VERSION "HNNBNNNYNNNNNNNNNNNNNNNNNNNNNNNNNNNNNNNNNN/4/%%%/4/'%**4NNN///"

NS_ :

BS_:

BU_: Airbag_D4 EPB_D4 ESP_D4 Gateway_D4C7 Getriebe_AL551_951_D4_C7 Getriebe_DL501_C7 Getriebe_VL381_C7 LWS_D4 Motor_EDC17_D4 Motor_ME17_BY Motor_MED17_SIMOS8_D4 Motor_Slave_D4 QSP_D4 SAK_C7 SCR_C7 SCU_D4

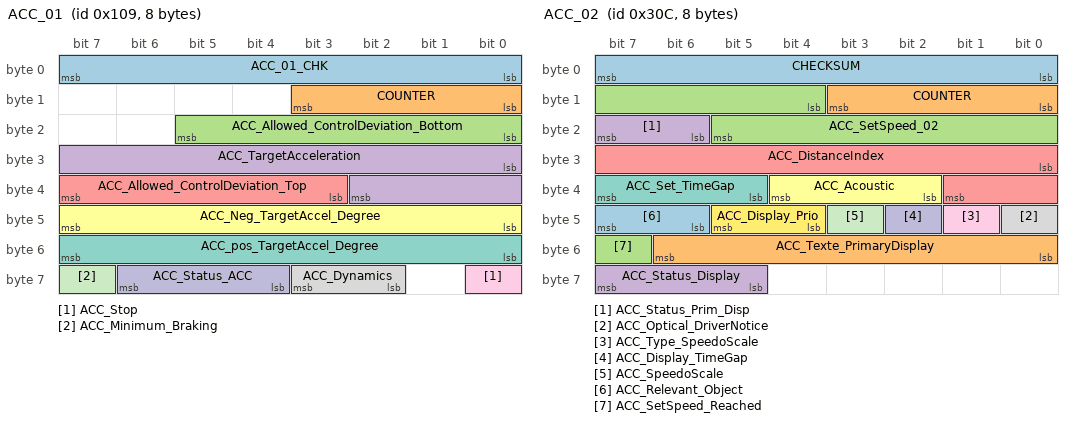
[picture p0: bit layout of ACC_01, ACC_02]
BO_ 265 ACC_01: 8 Gateway_B8
 SG_ ACC_01_CHK : 0|8@1+ (1,0) [0|255] ""  Magnetic_Ride_LB,Motor_MLB_AU48_AU416_Diesel,Motor_MLB_B8_Q5_Otto,Motor_MLB_Q5_Hybrid
 SG_ COUNTER : 8|4@1+ (1,0) [0|15] ""  Magnetic_Ride_LB,Motor_MLB_AU48_AU416_Diesel,Motor_MLB_B8_Q5_Otto,Motor_MLB_Q5_Hybrid
 SG_ ACC_Allowed_ControlDeviation_Bottom : 16|6@1+ (0.024,0) [0|1.512] "Unit_MeterPerSeconSquar"  Motor_MLB_AU48_AU416_Diesel,Motor_MLB_B8_Q5_Otto,Motor_MLB_Q5_Hybrid
 SG_ ACC_TargetAcceleration : 24|11@1+ (0.005,-7.22) [-7.22|3.01] "Unit_MeterPerSeconSquar"  Magnetic_Ride_LB,Motor_MLB_AU48_AU416_Diesel,Motor_MLB_B8_Q5_Otto,Motor_MLB_Q5_Hybrid
 SG_ ACC_Allowed_ControlDeviation_Top : 35|5@1+ (0.0625,0) [0|1.9375] "Unit_MeterPerSeconSquar"  Motor_MLB_AU48_AU416_Diesel,Motor_MLB_B8_Q5_Otto,Motor_MLB_Q5_Hybrid
 SG_ ACC_Neg_TargetAccel_Degree : 40|8@1+ (0.05,0) [0|12.7] "Unit_MeterPerCubicSecon"  Motor_MLB_AU48_AU416_Diesel,Motor_MLB_B8_Q5_Otto,Motor_MLB_Q5_Hybrid
 SG_ ACC_pos_TargetAccel_Degree : 48|8@1+ (0.05,0) [0|12.7] "Unit_MeterPerCubicSecon"  Motor_MLB_AU48_AU416_Diesel,Motor_MLB_B8_Q5_Otto,Motor_MLB_Q5_Hybrid
 SG_ ACC_Dynamics : 58|2@1+ (1,0) [0|3] ""  Motor_MLB_AU48_AU416_Diesel,Motor_MLB_B8_Q5_Otto,Motor_MLB_Q5_Hybrid
 SG_ ACC_Stop : 56|1@1+ (1,0) [0|1] ""  XXX
 SG_ ACC_Status_ACC : 60|3@1+ (1,0) [0|7] ""  XXX
 SG_ ACC_Minimum_Braking : 63|1@1+ (1,0) [0|1] ""  Motor_MLB_AU48_AU416_Diesel,Motor_MLB_B8_Q5_Otto,Motor_MLB_Q5_Hybrid

BO_ 780 ACC_02: 8 Gateway_D4C7
 SG_ CHECKSUM : 0|8@1+ (1,0) [0|255] ""  HUD_C7,Kombi_D4
 SG_ COUNTER : 8|4@1+ (1,0) [0|15] ""  HUD_C7,Kombi_D4
 SG_ ACC_SetSpeed_02 : 12|10@1+ (0.32,0) [0.00|326.72] "Unit_KiloMeterPerHour"  HUD_C7,Kombi_D4
 SG_ ACC_Status_Prim_Disp : 22|2@1+ (1.0,0.0) [0.0|3] ""  HUD_C7,Kombi_D4
 SG_ ACC_DistanceIndex : 24|10@1+ (1,0) [1|1021] ""  HUD_C7,Kombi_D4
 SG_ ACC_Acoustic : 34|3@1+ (1.0,0.0) [0.0|7] ""  Kombi_D4
 SG_ ACC_Set_TimeGap : 37|3@1+ (1.0,0.0) [0.0|7] ""  Kombi_D4
 SG_ ACC_Optical_DriverNotice : 40|1@1+ (1.0,0.0) [0.0|1] ""  Kombi_D4
 SG_ ACC_Type_SpeedoScale : 41|1@1+ (1.0,0.0) [0.0|1] ""  Kombi_D4
 SG_ ACC_Display_TimeGap : 42|1@1+ (1.0,0.0) [0.0|1] ""  Kombi_D4
 SG_ ACC_SpeedoScale : 43|1@1+ (1.0,0.0) [0.0|1] ""  Kombi_D4
 SG_ ACC_Display_Prio : 44|2@1+ (1.0,0.0) [0.0|3] ""  Vector__XXX
 SG_ ACC_Relevant_Object : 46|2@1+ (1.0,0.0) [0.0|3] ""  HUD_C7,Kombi_D4
 SG_ ACC_Texte_PrimaryDisplay : 48|7@1+ (1.0,0.0) [0.0|127] ""  HUD_C7,Kombi_D4
 SG_ ACC_SetSpeed_Reached : 55|1@1+ (1.0,0.0) [0.0|1] ""  Kombi_D4
 SG_ ACC_Status_Display : 61|3@1+ (1.0,0.0) [0.0|7] ""  APS_D4,Kombi_D4

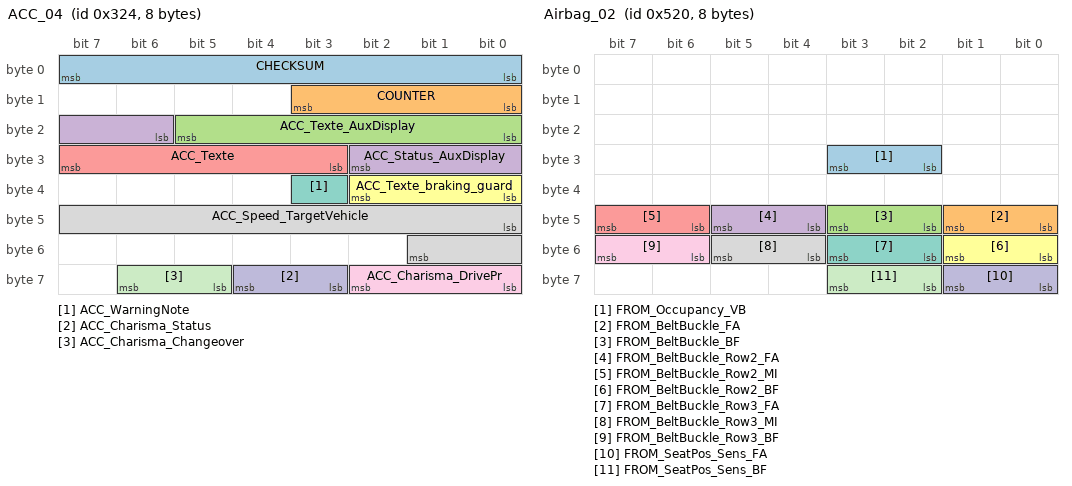
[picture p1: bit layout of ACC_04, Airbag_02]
BO_ 804 ACC_04: 8 Gateway_D4C7
 SG_ CHECKSUM : 0|8@1+ (1,0) [0|255] ""  HUD_C7,Kombi_D4
 SG_ COUNTER : 8|4@1+ (1,0) [0|15] ""  HUD_C7,Kombi_D4
 SG_ ACC_Texte_AuxDisplay : 16|6@1+ (1.0,0.0) [0.0|63] ""  Kombi_D4
 SG_ ACC_Status_AuxDisplay : 22|5@1+ (1.0,0.0) [0.0|31] ""  HUD_C7,Kombi_D4
 SG_ ACC_Texte : 27|5@1+ (1.0,0.0) [0.0|31] ""  Kombi_D4
 SG_ ACC_Texte_braking_guard : 32|3@1+ (1.0,0.0) [0.0|7] ""  HUD_C7,Kombi_D4
 SG_ ACC_WarningNote : 35|1@1+ (1.0,0.0) [0.0|1] ""  Vector__XXX
 SG_ ACC_Speed_TargetVehicle : 40|10@1+ (0.32,0) [0.00|326.72] "Unit_KiloMeterPerHour"  Vector__XXX
 SG_ ACC_Charisma_DrivePr : 56|3@1+ (1.0,0.0) [0.0|7] ""  Vector__XXX
 SG_ ACC_Charisma_Status : 59|2@1+ (1.0,0.0) [0.0|3] ""  Vector__XXX
 SG_ ACC_Charisma_Changeover : 61|2@1+ (1.0,0.0) [0.0|3] ""  Vector__XXX

BO_ 269 ACC_05: 8 Gateway_D4C7
 SG_ ACC_05_CHK : 0|8@1+ (1,0) [0|255] ""  EPB_D4,Getriebe_AL551_951_D4_C7,Getriebe_DL501_C7,Getriebe_VL381_C7,Motor_EDC17_D4,Motor_ME17_BY,Motor_MED17_SIMOS8_D4
 SG_ COUNTER : 8|4@1+ (1,0) [0|15] ""  EPB_D4,Getriebe_AL551_951_D4_C7,Getriebe_DL501_C7,Getriebe_VL381_C7,Motor_EDC17_D4,Motor_ME17_BY,Motor_MED17_SIMOS8_D4
 SG_ ACC_Enable_TorqueReq : 12|1@1+ (1.0,0.0) [0.0|1] ""  Motor_EDC17_D4,Motor_ME17_BY,Motor_MED17_SIMOS8_D4
 SG_ ACC_Enable_DecelReq : 13|1@1+ (1.0,0.0) [0.0|1] ""  Getriebe_AL551_951_D4_C7,Getriebe_DL501_C7,Getriebe_VL381_C7
 SG_ ACC_GearboxPosition_P : 14|1@1+ (1.0,0.0) [0.0|1] ""  Getriebe_AL551_951_D4_C7,Getriebe_DL501_C7,Getriebe_VL381_C7
 SG_ ACC_Limited_PullAwayDyn : 15|1@1+ (1.0,0.0) [0.0|1] ""  Motor_EDC17_D4,Motor_ME17_BY,Motor_MED17_SIMOS8_D4
 SG_ ACC_TorqueRequest : 16|10@1+ (1,0) [0|1021] ""  Motor_EDC17_D4,Motor_ME17_BY,Motor_MED17_SIMOS8_D4
 SG_ ACC_Allowed_ControlDeviation : 26|6@1+ (0.024,0) [0.000|1.512] "Unit_MeterPerSeconSquar"  Getriebe_AL551_951_D4_C7,Getriebe_DL501_C7,Getriebe_VL381_C7
 SG_ ACC_Decel_Req : 32|11@1+ (0.005,-7.22) [-7.220|3.015] "Unit_MeterPerSeconSquar"  Vector__XXX
 SG_ ACC_Loeseanforderung : 43|1@1+ (1.0,0.0) [0.0|1] ""  Vector__XXX
 SG_ ACC_StartStop_Info : 44|2@1+ (1.0,0.0) [0.0|3] ""  Motor_EDC17_D4,Motor_ME17_BY,Motor_MED17_SIMOS8_D4
 SG_ ACC_Vorbefuellung_BrakeSystem : 47|1@1+ (1.0,0.0) [0.0|1] ""  Vector__XXX
 SG_ ACC_ax_Gearbox : 48|9@1+ (0.024,-2.016) [-2.016|10.248] "Unit_MeterPerSeconSquar"  Getriebe_AL551_951_D4_C7,Getriebe_DL501_C7,Getriebe_VL381_C7
 SG_ ACC_Status_ACC : 57|3@1+ (1.0,0.0) [0.0|7] ""  EPB_D4,Motor_EDC17_D4,Motor_ME17_BY,Motor_MED17_SIMOS8_D4
 SG_ ACC_Actuation_EPB : 60|1@1+ (1.0,0.0) [0.0|1] ""  EPB_D4,Motor_EDC17_D4,Motor_ME17_BY,Motor_MED17_SIMOS8_D4
 SG_ ACC_Influence_ESP : 61|1@1+ (1.0,0.0) [0.0|1] ""  Vector__XXX
 SG_ ACC_Stop : 62|1@1+ (1.0,0.0) [0.0|1] ""  Vector__XXX
 SG_ ACC_KD_Error : 63|1@1+ (1.0,0.0) [0.0|1] ""  Vector__XXX

BO_ 279 ACC_10: 8 XXX
 SG_ CHECKSUM : 0|8@1+ (1,0) [0|255] ""  XXX
 SG_ COUNTER : 8|4@1+ (1,0) [0|15] ""  XXX
 SG_ AWV1_Req_Prefill : 16|1@1+ (1,0) [0|1] ""  XXX
 SG_ ANB_CM_Info : 17|1@1+ (1,0) [0|1] ""  XXX
 SG_ AWV2_Enable : 18|1@1+ (1,0) [0|1] ""  XXX
 SG_ AWV1_HBA_Param : 19|2@1+ (1,0) [0|3] ""  XXX
 SG_ AWV2_JerkProfile : 21|3@1+ (1,0) [0|7] ""  XXX
 SG_ AWV2_PrioWarning : 24|1@1+ (1,0) [0|1] ""  XXX
 SG_ ANB_CM_Request : 25|1@1+ (1,0) [0|1] ""  XXX
 SG_ ANB_Info_PartialBraking : 26|1@1+ (1,0) [0|1] ""  XXX
 SG_ ANB_EmergencyFlash : 27|1@1+ (1,0) [0|1] ""  XXX
 SG_ ANB_PartialBraking_Enable : 28|1@1+ (1,0) [0|1] ""  XXX
 SG_ ANB_TargetBrake_Teilbrems_Decel_Req : 29|10@1+ (0.024,-20.016) [-20.016|4.536] "Unit_MeterPerSeconSquar"  XXX
 SG_ ANB_TargetBraking_Enable : 39|1@1+ (1,0) [0|1] ""  XXX
 SG_ AWV_BeforeStage : 40|1@1+ (1,0) [0|1] ""  XXX
 SG_ AWV_Hold : 41|1@1+ (1,0) [0|1] ""  XXX
 SG_ AWV_CityANB_Variant : 42|1@1+ (1,0) [0|1] ""  XXX
 SG_ PCF_Enable : 43|1@1+ (1,0) [0|1] ""  XXX
 SG_ AWV1_ECD_StartUp : 44|1@1+ (1,0) [0|1] ""  XXX
 SG_ AWV_AWA_VZ_Req_Lenkmomoffset : 46|1@1+ (1.0,0.0) [0.0|1] ""  XXX
 SG_ AWV_AWA_Req_Lenkmomoffset : 47|9@1+ (0.01,0) [0.00|5.11] "Unit_NewtoMeter"  XXX
 SG_ PCF_Time_to_collision : 56|8@1+ (0.01,0) [0|2.5] "Unit_Secon"  XXX

BO_ 64 Airbag_01: 8 Airbag_D4
 SG_ Airbag_01_CHK : 0|8@1+ (1,0) [0|255] ""  Gateway_D4C7,Motor_EDC17_D4,Motor_ME17_BY,Motor_MED17_SIMOS8_D4
 SG_ Airbag_01_BZ : 8|4@1+ (1,0) [0|15] ""  Gateway_D4C7,Motor_EDC17_D4,Motor_ME17_BY,Motor_MED17_SIMOS8_D4
 SG_ FROM_RGS_Anst : 12|4@1+ (1.0,0.0) [0.0|15] ""  Gateway_D4C7
 SG_ FROM_Front_Crash : 16|1@1+ (1.0,0.0) [0.0|1] ""  Gateway_D4C7
 SG_ FROM_Rear_Crash : 17|1@1+ (1.0,0.0) [0.0|1] ""  Gateway_D4C7
 SG_ FROM_SF_Crash : 18|1@1+ (1.0,0.0) [0.0|1] ""  Gateway_D4C7
 SG_ FROM_SB_Crash : 19|1@1+ (1.0,0.0) [0.0|1] ""  Gateway_D4C7
 SG_ FROM_Rollover_Crash : 20|1@1+ (1.0,0.0) [0.0|1] ""  Gateway_D4C7
 SG_ FROM_Crash_Int : 21|3@1+ (1.0,0.0) [0.0|7] ""  Gateway_D4C7,Motor_EDC17_D4,Motor_ME17_BY,Motor_MED17_SIMOS8_D4
 SG_ FROM_Lamp : 24|1@1+ (1.0,0.0) [0.0|1] ""  Gateway_D4C7
 SG_ FROM_Deactivated : 25|1@1+ (1.0,0.0) [0.0|1] ""  Gateway_D4C7
 SG_ FROM_VB_Deactivated : 26|1@1+ (1.0,0.0) [0.0|1] ""  Gateway_D4C7
 SG_ FROM_SystemError : 27|1@1+ (1.0,0.0) [0.0|1] ""  Gateway_D4C7
 SG_ FROM_Diagnostics : 28|1@1+ (1.0,0.0) [0.0|1] ""  Gateway_D4C7
 SG_ FROM_ActuatorTest : 29|1@1+ (1.0,0.0) [0.0|1] ""  Gateway_D4C7,Motor_EDC17_D4,Motor_ME17_BY,Motor_MED17_SIMOS8_D4
 SG_ FROM_Erh_Open_VB : 30|2@1+ (1.0,0.0) [0.0|3] ""  Gateway_D4C7
 SG_ FROM_BeltWarn_VF : 32|1@1+ (1.0,0.0) [0.0|1] ""  Gateway_D4C7
 SG_ FROM_BeltWarn_VB : 33|1@1+ (1.0,0.0) [0.0|1] ""  Gateway_D4C7
 SG_ FROM_Display_Pedestrian : 34|2@1+ (1.0,0.0) [0.0|3] ""  Gateway_D4C7
 SG_ FROM_Texte_AKS : 36|2@1+ (1.0,0.0) [0.0|3] ""  Gateway_D4C7
 SG_ FROM_PAO_Lamp_Req : 38|1@1+ (1.0,0.0) [0.0|1] ""  Gateway_D4C7
 SG_ FROM_MKB_Valid : 39|1@1+ (1.0,0.0) [0.0|1] ""  Gateway_D4C7
 SG_ FROM_MKB_Request : 40|1@1+ (1.0,0.0) [0.0|1] ""  Gateway_D4C7
 SG_ FROM_SupplyVoltage : 41|1@1+ (1.0,0.0) [0.0|1] ""  Gateway_D4C7
 SG_ FROM_KD_Error : 63|1@1+ (1.0,0.0) [0.0|1] ""  Gateway_D4C7

BO_ 1312 Airbag_02: 8 Airbag_D4
 SG_ FROM_Occupancy_VB : 26|2@1+ (1.0,0.0) [0.0|3] ""  Gateway_D4C7
 SG_ FROM_BeltBuckle_FA : 40|2@1+ (1.0,0.0) [0.0|3] ""  EPB_D4,Gateway_D4C7,Motor_EDC17_D4,Motor_ME17_BY,Motor_MED17_SIMOS8_D4
 SG_ FROM_BeltBuckle_BF : 42|2@1+ (1.0,0.0) [0.0|3] ""  Gateway_D4C7
 SG_ FROM_BeltBuckle_Row2_FA : 44|2@1+ (1.0,0.0) [0.0|3] ""  Gateway_D4C7
 SG_ FROM_BeltBuckle_Row2_MI : 46|2@1+ (1.0,0.0) [0.0|3] ""  Gateway_D4C7
 SG_ FROM_BeltBuckle_Row2_BF : 48|2@1+ (1.0,0.0) [0.0|3] ""  Gateway_D4C7
 SG_ FROM_BeltBuckle_Row3_FA : 50|2@1+ (1.0,0.0) [0.0|3] ""  Gateway_D4C7
 SG_ FROM_BeltBuckle_Row3_MI : 52|2@1+ (1.0,0.0) [0.0|3] ""  Gateway_D4C7
 SG_ FROM_BeltBuckle_Row3_BF : 54|2@1+ (1.0,0.0) [0.0|3] ""  Gateway_D4C7
 SG_ FROM_SeatPos_Sens_FA : 56|2@1+ (1.0,0.0) [0.0|3] ""  Gateway_D4C7
 SG_ FROM_SeatPos_Sens_BF : 58|2@1+ (1.0,0.0) [0.0|3] ""  Gateway_D4C7

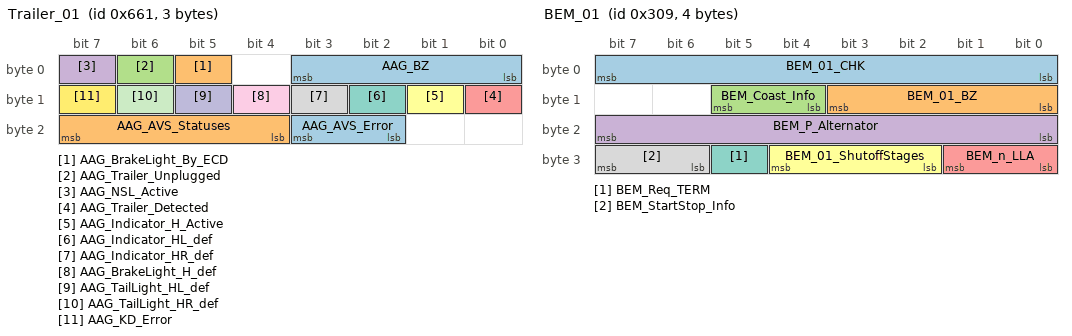
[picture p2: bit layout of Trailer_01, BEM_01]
BO_ 1633 Trailer_01: 3 Gateway_D4C7
 SG_ AAG_BZ : 0|4@1+ (1,0) [0|15] ""  Getriebe_AL551_951_D4_C7,Motor_EDC17_D4,Motor_ME17_BY,Motor_MED17_SIMOS8_D4
 SG_ AAG_BrakeLight_By_ECD : 5|1@1+ (1.0,0.0) [0.0|1] ""  Motor_EDC17_D4,Motor_ME17_BY,Motor_MED17_SIMOS8_D4
 SG_ AAG_Trailer_Unplugged : 6|1@1+ (1.0,0.0) [0.0|1] ""  Vector__XXX
 SG_ AAG_NSL_Active : 7|1@1+ (1.0,0.0) [0.0|1] ""  Vector__XXX
 SG_ AAG_Trailer_Detected : 8|1@1+ (1.0,0.0) [0.0|1] ""  Getriebe_AL551_951_D4_C7,Getriebe_DL501_C7,Getriebe_VL381_C7,Motor_EDC17_D4,Motor_ME17_BY,Motor_MED17_SIMOS8_D4
 SG_ AAG_Indicator_H_Active : 9|1@1+ (1.0,0.0) [0.0|1] ""  Vector__XXX
 SG_ AAG_Indicator_HL_def : 10|1@1+ (1.0,0.0) [0.0|1] ""  Vector__XXX
 SG_ AAG_Indicator_HR_def : 11|1@1+ (1.0,0.0) [0.0|1] ""  Vector__XXX
 SG_ AAG_BrakeLight_H_def : 12|1@1+ (1.0,0.0) [0.0|1] ""  Motor_EDC17_D4,Motor_ME17_BY,Motor_MED17_SIMOS8_D4
 SG_ AAG_TailLight_HL_def : 13|1@1+ (1.0,0.0) [0.0|1] ""  Vector__XXX
 SG_ AAG_TailLight_HR_def : 14|1@1+ (1.0,0.0) [0.0|1] ""  Vector__XXX
 SG_ AAG_KD_Error : 15|1@1+ (1.0,0.0) [0.0|1] ""  Vector__XXX
 SG_ AAG_AVS_Error : 18|2@1+ (1.0,0.0) [0.0|3] ""  Vector__XXX
 SG_ AAG_AVS_Statuses : 20|4@1+ (1.0,0.0) [0.0|15] ""  Vector__XXX

BO_ 777 BEM_01: 4 Gateway_D4C7
 SG_ BEM_01_CHK : 0|8@1+ (1,0) [0|255] ""  Motor_EDC17_D4,Motor_ME17_BY,Motor_MED17_SIMOS8_D4
 SG_ BEM_01_BZ : 8|4@1+ (1,0) [0|15] ""  Motor_EDC17_D4,Motor_ME17_BY,Motor_MED17_SIMOS8_D4
 SG_ BEM_Coast_Info : 12|2@1+ (1.0,0.0) [0.0|3] ""  Vector__XXX
 SG_ BEM_P_Alternator : 16|8@1+ (50,0) [0|12700] "Unit_Watt"  Motor_EDC17_D4,Motor_ME17_BY,Motor_MED17_SIMOS8_D4
 SG_ BEM_n_LLA : 24|2@1+ (1.0,0.0) [0.0|3] ""  Motor_EDC17_D4,Motor_ME17_BY,Motor_MED17_SIMOS8_D4
 SG_ BEM_01_ShutoffStages : 26|3@1+ (1.0,0.0) [0.0|7] ""  Vector__XXX
 SG_ BEM_Req_TERM : 29|1@1+ (1.0,0.0) [0.0|1] ""  Motor_EDC17_D4,Motor_ME17_BY,Motor_MED17_SIMOS8_D4
 SG_ BEM_StartStop_Info : 30|2@1+ (1.0,0.0) [0.0|3] ""  Motor_EDC17_D4,Motor_ME17_BY,Motor_MED17_SIMOS8_D4

BO_ 867 FlashModes_01: 4 Gateway_D4C7
 SG_ BM_ZV_Open : 0|1@1+ (1.0,0.0) [0.0|1] ""  Vector__XXX
 SG_ BM_ZV_Closed : 1|1@1+ (1.0,0.0) [0.0|1] ""  Vector__XXX
 SG_ BM_DWA_On : 2|1@1+ (1.0,0.0) [0.0|1] ""  Vector__XXX
 SG_ BM_DWA_Alarm : 3|1@1+ (1.0,0.0) [0.0|1] ""  Vector__XXX
 SG_ BM_Crash : 4|1@1+ (1.0,0.0) [0.0|1] ""  Vector__XXX
 SG_ BM_Panic : 5|1@1+ (1.0,0.0) [0.0|1] ""  Vector__XXX
 SG_ BM_Not_Braking : 6|1@1+ (1.0,0.0) [0.0|1] ""  Vector__XXX
 SG_ BM_GDO : 7|1@1+ (1.0,0.0) [0.0|1] ""  Vector__XXX
 SG_ BM_Left : 8|1@1+ (1.0,0.0) [0.0|1] ""  Vector__XXX
 SG_ BM_Right : 9|1@1+ (1.0,0.0) [0.0|1] ""  Vector__XXX
 SG_ BM_HazardFlash : 10|1@1+ (1.0,0.0) [0.0|1] ""  Vector__XXX
 SG_ BM_Motorway : 11|1@1+ (1.0,0.0) [0.0|1] ""  Vector__XXX
 SG_ BM_Taxi_Notalarm : 12|1@1+ (1.0,0.0) [0.0|1] ""  Vector__XXX
 SG_ BM_Telematics : 13|1@1+ (1.0,0.0) [0.0|1] ""  Vector__XXX
 SG_ BM_HD_Opening_angelernt : 14|1@1+ (1.0,0.0) [0.0|1] ""  Vector__XXX
 SG_ BM_WBT_Lighting : 15|1@1+ (1.0,0.0) [0.0|1] ""  Vector__XXX
 SG_ Flash_Left_Veh_Clock : 16|1@1+ (1.0,0.0) [0.0|1] ""  Vector__XXX
 SG_ Flash_Right_Veh_Clock : 17|1@1+ (1.0,0.0) [0.0|1] ""  Vector__XXX
 SG_ Flash_Left_Cluster_Clock : 18|1@1+ (1.0,0.0) [0.0|1] ""  Kombi_D4
 SG_ Flash_Right_Cluster_Clock : 19|1@1+ (1.0,0.0) [0.0|1] ""  Kombi_D4
 SG_ BM_NBA_n_Coded_n_Active : 20|1@1+ (1.0,0.0) [0.0|1] ""  Vector__XXX
 SG_ BM_NBA_Status : 21|2@1+ (1.0,0.0) [0.0|3] ""  Vector__XXX
 SG_ Flash_FWB_Active : 23|1@1+ (1.0,0.0) [0.0|1] ""  Vector__XXX

BO_ 482 CCP_GE_CR0_01: 8 Gateway_D4C7
 SG_ CCP_GE_CRO_01_Data : 0|64@1+ (1,0) [0|1] ""  Getriebe_AL551_951_D4_C7,Getriebe_DL501_C7,Getriebe_VL381_C7

BO_ 490 CCP_GE_Ditto_01: 8 Getriebe_AL551_951_D4_C7
 SG_ CCP_GE_Ditto_01_Data : 0|64@1+ (1,0) [0|1] ""  Gateway_D4C7

BO_ 480 CCP_MO_CRO_01: 8 Gateway_D4C7
 SG_ CCP_MO_CRO_01_Data : 0|64@1+ (1,0) [0|1] ""  Motor_EDC17_D4,Motor_ME17_BY,Motor_MED17_SIMOS8_D4

BO_ 2616986624 CCP_MO_CRO_02: 8 Vector__XXX
 SG_ CCP_MO_CRO_02_Data : 0|64@1+ (1,0) [0|1] ""  Motor_EDC17_D4,Motor_ME17_BY,Motor_MED17_SIMOS8_D4

BO_ 488 CCP_MO_Ditto_01: 8 Motor_EDC17_D4
 SG_ CCP_MO_Ditto_01_Data : 0|64@1+ (1,0) [0|1] ""  Gateway_D4C7

BO_ 2616986625 CCP_MO_Ditto_02: 8 Motor_EDC17_D4
 SG_ CCP_MO_Ditto_02_Data : 0|64@1+ (1,0) [0|1] ""  Vector__XXX

BO_ 481 CCP_MOS_CRO_01: 8 Gateway_D4C7
 SG_ CCP_MOS_CRO_01_Data : 0|64@1+ (1,0) [0|1] ""  Motor_Slave_D4

BO_ 2616986629 CCP_MOS_CRO_02: 8 Vector__XXX
 SG_ CCP_MOS_CRO_02_Data : 0|64@1+ (1,0) [0|1] ""  Motor_Slave_D4

BO_ 489 CCP_MOS_Ditto_01: 8 Motor_Slave_D4
 SG_ CCP_MOS_Ditto_01_Data : 0|64@1+ (1,0) [0|1] ""  Gateway_D4C7

BO_ 2616986630 CCP_MOS_Ditto_02: 8 Motor_Slave_D4
 SG_ CCP_MOS_Ditto_02_Data : 0|64@1+ (1,0) [0|1] ""  Vector__XXX

BO_ 2617042432 CCP_SoundActuator_CRO_01: 8 Vector__XXX
 SG_ CCP_SoundActuator_CRO_01_Data : 0|64@1+ (1.0,0.0) [0.0|18446744073709551615] ""  SAK_C7

BO_ 2617042433 CCP_SoundActuator_Ditto_01: 8 SAK_C7
 SG_ CCP_SoundActuator_Ditto_01_Data : 0|64@1+ (1.0,0.0) [0.0|18446744073709551615] ""  Vector__XXX

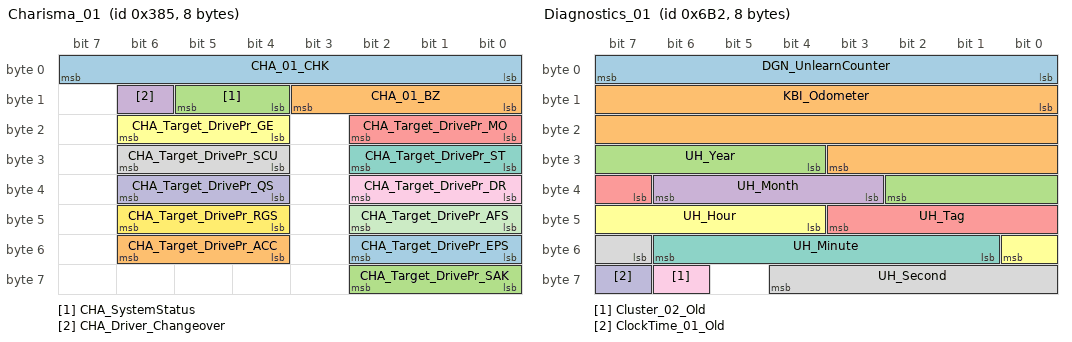
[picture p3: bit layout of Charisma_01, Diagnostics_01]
BO_ 901 Charisma_01: 8 Gateway_D4C7
 SG_ CHA_01_CHK : 0|8@1+ (1,0) [0|255] ""  Getriebe_AL551_951_D4_C7,Getriebe_DL501_C7,Getriebe_VL381_C7,Motor_EDC17_D4,Motor_ME17_BY,Motor_MED17_SIMOS8_D4,SCU_D4
 SG_ CHA_01_BZ : 8|4@1+ (1,0) [0|15] ""  Motor_EDC17_D4,Motor_ME17_BY,Motor_MED17_SIMOS8_D4
 SG_ CHA_SystemStatus : 12|2@1+ (1.0,0.0) [0.0|3] ""  Getriebe_AL551_951_D4_C7,Getriebe_DL501_C7,Getriebe_VL381_C7,Motor_EDC17_D4,Motor_ME17_BY,Motor_MED17_SIMOS8_D4,SCU_D4
 SG_ CHA_Driver_Changeover : 14|1@1+ (1.0,0.0) [0.0|1] ""  Vector__XXX
 SG_ CHA_Target_DrivePr_MO : 16|3@1+ (1.0,0.0) [0.0|7] ""  Motor_EDC17_D4,Motor_ME17_BY,Motor_MED17_SIMOS8_D4
 SG_ CHA_Target_DrivePr_GE : 20|3@1+ (1.0,0.0) [0.0|7] ""  Getriebe_AL551_951_D4_C7,Getriebe_DL501_C7,Getriebe_VL381_C7
 SG_ CHA_Target_DrivePr_ST : 24|3@1+ (1.0,0.0) [0.0|7] ""  Vector__XXX
 SG_ CHA_Target_DrivePr_SCU : 28|3@1+ (1.0,0.0) [0.0|7] ""  SCU_D4
 SG_ CHA_Target_DrivePr_DR : 32|3@1+ (1.0,0.0) [0.0|7] ""  Vector__XXX
 SG_ CHA_Target_DrivePr_QS : 36|3@1+ (1.0,0.0) [0.0|7] ""  Vector__XXX
 SG_ CHA_Target_DrivePr_AFS : 40|3@1+ (1.0,0.0) [0.0|7] ""  Vector__XXX
 SG_ CHA_Target_DrivePr_RGS : 44|3@1+ (1.0,0.0) [0.0|7] ""  Vector__XXX
 SG_ CHA_Target_DrivePr_EPS : 48|3@1+ (1.0,0.0) [0.0|7] ""  Vector__XXX
 SG_ CHA_Target_DrivePr_ACC : 52|3@1+ (1.0,0.0) [0.0|7] ""  Vector__XXX
 SG_ CHA_Target_DrivePr_SAK : 56|3@1+ (1.0,0.0) [0.0|7] ""  Vector__XXX

BO_ 2617027072 DEV_Airbag_01: 4 Airbag_D4
 SG_ DEV_Airbag_01 : 0|32@1+ (1.0,0.0) [0.0|4294967295] ""  Vector__XXX

BO_ 1714 Diagnostics_01: 8 Gateway_D4C7
 SG_ DGN_UnlearnCounter : 0|8@1+ (1,0) [0|254] ""  Airbag_D4,EPB_D4,Getriebe_AL551_951_D4_C7,SAK_C7,SCR_C7,SCU_D4
 SG_ KBI_Odometer : 8|20@1+ (1,0) [0|1048573] "Unit_KiloMeter"  Airbag_D4,EPB_D4,Getriebe_AL551_951_D4_C7,Getriebe_DL501_C7,Getriebe_VL381_C7,Motor_EDC17_D4,Motor_ME17_BY,Motor_MED17_SIMOS8_D4,SAK_C7,SCR_C7,SCU_D4
 SG_ UH_Year : 28|7@1+ (1,2000) [2000|2127] "Unit_Year"  Airbag_D4,EPB_D4,Getriebe_AL551_951_D4_C7,Getriebe_DL501_C7,Getriebe_VL381_C7,Motor_EDC17_D4,Motor_ME17_BY,Motor_MED17_SIMOS8_D4,SAK_C7,SCR_C7,SCU_D4
 SG_ UH_Month : 35|4@1+ (1,0) [1|12] "Unit_Month"  Airbag_D4,EPB_D4,Getriebe_AL551_951_D4_C7,Getriebe_DL501_C7,Getriebe_VL381_C7,Motor_EDC17_D4,Motor_ME17_BY,Motor_MED17_SIMOS8_D4,SAK_C7,SCR_C7,SCU_D4
 SG_ UH_Tag : 39|5@1+ (1,0) [1|31] "Unit_Day"  Airbag_D4,EPB_D4,Getriebe_AL551_951_D4_C7,Getriebe_DL501_C7,Getriebe_VL381_C7,Motor_EDC17_D4,Motor_ME17_BY,Motor_MED17_SIMOS8_D4,SAK_C7,SCR_C7,SCU_D4
 SG_ UH_Hour : 44|5@1+ (1,0) [0|23] "Unit_Hours"  Airbag_D4,EPB_D4,Getriebe_AL551_951_D4_C7,Getriebe_DL501_C7,Getriebe_VL381_C7,Motor_EDC17_D4,Motor_ME17_BY,Motor_MED17_SIMOS8_D4,SAK_C7,SCR_C7,SCU_D4
 SG_ UH_Minute : 49|6@1+ (1,0) [0|59] "Unit_Minut"  Airbag_D4,EPB_D4,Getriebe_AL551_951_D4_C7,Getriebe_DL501_C7,Getriebe_VL381_C7,Motor_EDC17_D4,Motor_ME17_BY,Motor_MED17_SIMOS8_D4,SAK_C7,SCR_C7,SCU_D4
 SG_ UH_Second : 55|6@1+ (1,0) [0|59] "Unit_Secon"  Airbag_D4,EPB_D4,Getriebe_AL551_951_D4_C7,Getriebe_DL501_C7,Getriebe_VL381_C7,Motor_EDC17_D4,Motor_ME17_BY,Motor_MED17_SIMOS8_D4,SAK_C7,SCR_C7,SCU_D4
 SG_ Cluster_02_Old : 62|1@1+ (1.0,0.0) [0.0|1] ""  Airbag_D4,Getriebe_AL551_951_D4_C7,Getriebe_DL501_C7,Getriebe_VL381_C7,SCR_C7,SCU_D4
 SG_ ClockTime_01_Old : 63|1@1+ (1.0,0.0) [0.0|1] ""  Airbag_D4,Getriebe_AL551_951_D4_C7,Getriebe_DL501_C7,Getriebe_VL381_C7,SCR_C7,SCU_D4

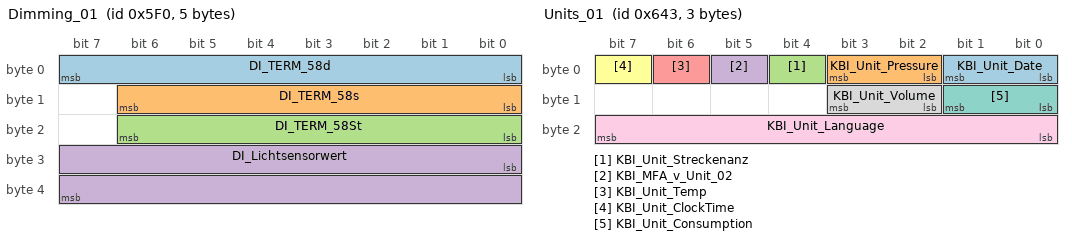
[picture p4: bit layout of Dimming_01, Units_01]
BO_ 1520 Dimming_01: 5 Gateway_D4C7
 SG_ DI_TERM_58d : 0|8@1+ (1,0) [0|253] ""  Airbag_D4,Getriebe_AL551_951_D4_C7
 SG_ DI_TERM_58s : 8|7@1+ (1,0) [0|100] "Unit_PerCent"  Getriebe_AL551_951_D4_C7
 SG_ DI_TERM_58St : 16|7@1+ (1,0) [0|100] "Unit_PerCent"  Getriebe_AL551_951_D4_C7
 SG_ DI_Lichtsensorwert : 24|16@1+ (1,0) [0|65535] ""  Airbag_D4,Getriebe_AL551_951_D4_C7

BO_ 1603 Units_01: 3 Gateway_D4C7
 SG_ KBI_Unit_Date : 0|2@1+ (1.0,0.0) [0.0|3] ""  Vector__XXX
 SG_ KBI_Unit_Pressure : 2|2@1+ (1.0,0.0) [0.0|3] ""  Vector__XXX
 SG_ KBI_Unit_Streckenanz : 4|1@1+ (1.0,0.0) [0.0|1] ""  Motor_EDC17_D4
 SG_ KBI_MFA_v_Unit_02 : 5|1@1+ (1.0,0.0) [0.0|1] ""  Vector__XXX
 SG_ KBI_Unit_Temp : 6|1@1+ (1.0,0.0) [0.0|1] ""  Vector__XXX
 SG_ KBI_Unit_ClockTime : 7|1@1+ (1.0,0.0) [0.0|1] ""  Vector__XXX
 SG_ KBI_Unit_Consumption : 8|2@1+ (1.0,0.0) [0.0|3] ""  Vector__XXX
 SG_ KBI_Unit_Volume : 10|2@1+ (1.0,0.0) [0.0|3] ""  Vector__XXX
 SG_ KBI_Unit_Language : 16|8@1+ (1,0) [0|255] ""  Vector__XXX

BO_ 260 EPB_01: 8 EPB_D4
 SG_ EPB_01_CHK : 0|8@1+ (1,0) [0|255] ""  Gateway_D4C7,Motor_EDC17_D4,Motor_ME17_BY,Motor_MED17_SIMOS8_D4
 SG_ EPB_01_BZ : 8|4@1+ (1,0) [0|15] ""  Gateway_D4C7,Motor_EDC17_D4,Motor_ME17_BY,Motor_MED17_SIMOS8_D4
 SG_ EPB_QBit_LongAccel : 12|1@1+ (1.0,0.0) [0.0|1] ""  Gateway_D4C7
 SG_ EPB_QBit_PedalTravel_Clutch : 13|1@1+ (1.0,0.0) [0.0|1] ""  Gateway_D4C7,Motor_EDC17_D4,Motor_ME17_BY,Motor_MED17_SIMOS8_D4
 SG_ EPB_BCM2_Engine_Wakeup : 14|1@1+ (1.0,0.0) [0.0|1] ""  Gateway_D4C7
 SG_ EPB_Enable_Decel_Req : 15|1@1+ (1.0,0.0) [0.0|1] ""  Gateway_D4C7,Getriebe_AL551_951_D4_C7,Motor_EDC17_D4,Motor_ME17_BY,Motor_MED17_SIMOS8_D4
 SG_ EPB_Decel_Req : 16|8@1+ (0.048,-7.968) [-7.968|4.224] "Unit_MeterPerSeconSquar"  Gateway_D4C7
 SG_ EPB_LongAccel : 24|8@1+ (1,-128) [-128|126] "Unit_PerCentOfForceOfGravi"  Gateway_D4C7
 SG_ EPB_PedalTravel_Clutch : 32|8@1+ (0.4,0) [8.0|92.0] "Unit_PerCent"  Gateway_D4C7,Motor_EDC17_D4,Motor_ME17_BY,Motor_MED17_SIMOS8_D4
 SG_ EPB_PullAwayRequest_Detected : 48|1@1+ (1.0,0.0) [0.0|1] ""  Gateway_D4C7
 SG_ EPB_DAA_BoundaryCond_erf : 49|1@1+ (1.0,0.0) [0.0|1] ""  Gateway_D4C7
 SG_ EPB_ErrorStatus : 50|2@1+ (1.0,0.0) [0.0|3] ""  Gateway_D4C7
 SG_ EPB_Schalterposition : 52|2@1+ (1.0,0.0) [0.0|3] ""  Gateway_D4C7,Getriebe_AL551_951_D4_C7,Motor_EDC17_D4,Motor_ME17_BY,Motor_MED17_SIMOS8_D4
 SG_ EPB_QBit_Schalterpos : 54|1@1+ (1.0,0.0) [0.0|1] ""  Gateway_D4C7,Getriebe_AL551_951_D4_C7,Motor_EDC17_D4,Motor_ME17_BY,Motor_MED17_SIMOS8_D4
 SG_ EPB_Consistency_ACC : 55|1@1+ (1.0,0.0) [0.0|1] ""  Gateway_D4C7
 SG_ EPB_ClampForce : 56|5@1+ (1,0) [0|29] "Unit_KiloNewto"  Gateway_D4C7,Getriebe_AL551_951_D4_C7,Getriebe_DL501_C7,Getriebe_VL381_C7
 SG_ EPB_Status : 61|2@1+ (1.0,0.0) [0.0|3] ""  Gateway_D4C7,Getriebe_AL551_951_D4_C7,Getriebe_DL501_C7,Motor_EDC17_D4,Motor_ME17_BY,Motor_MED17_SIMOS8_D4
 SG_ EPB_KD_Error : 63|1@1+ (1.0,0.0) [0.0|1] ""  Gateway_D4C7

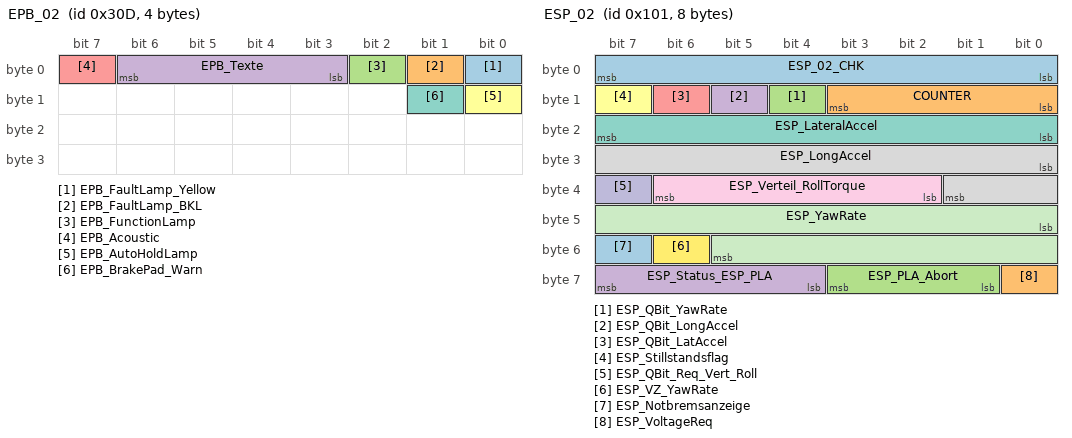
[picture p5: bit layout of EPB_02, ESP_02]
BO_ 781 EPB_02: 4 EPB_D4
 SG_ EPB_FaultLamp_Yellow : 0|1@1+ (1.0,0.0) [0.0|1] ""  Gateway_D4C7
 SG_ EPB_FaultLamp_BKL : 1|1@1+ (1.0,0.0) [0.0|1] ""  Gateway_D4C7
 SG_ EPB_FunctionLamp : 2|1@1+ (1.0,0.0) [0.0|1] ""  Gateway_D4C7
 SG_ EPB_Texte : 3|4@1+ (1.0,0.0) [0.0|15] ""  Gateway_D4C7
 SG_ EPB_Acoustic : 7|1@1+ (1.0,0.0) [0.0|1] ""  Gateway_D4C7
 SG_ EPB_AutoHoldLamp : 8|1@1+ (1.0,0.0) [0.0|1] ""  Gateway_D4C7
 SG_ EPB_BrakePad_Warn : 9|1@1+ (1.0,0.0) [0.0|1] ""  Gateway_D4C7

BO_ 256 ESP_01: 8 Gateway_D4C7
 SG_ ESP_01_CHK : 0|8@1+ (1,0) [0|255] ""  Airbag_D4,EPB_D4,Getriebe_AL551_951_D4_C7,Getriebe_DL501_C7,Getriebe_VL381_C7,Motor_EDC17_D4,Motor_ME17_BY,Motor_MED17_SIMOS8_D4
 SG_ COUNTER : 8|4@1+ (1,0) [0|15] ""  Airbag_D4,EPB_D4,Getriebe_AL551_951_D4_C7,Getriebe_DL501_C7,Getriebe_VL381_C7,Motor_EDC17_D4,Motor_ME17_BY,Motor_MED17_SIMOS8_D4
 SG_ ASR_Torque_Slow : 12|10@1+ (1,0) [0|1021] ""  Airbag_D4,Getriebe_AL551_951_D4_C7,Getriebe_DL501_C7,Motor_EDC17_D4,Motor_ME17_BY,Motor_MED17_SIMOS8_D4
 SG_ ASR_MSR_Torque_Fast : 22|10@1+ (1,0) [0|1021] ""  Airbag_D4,Getriebe_AL551_951_D4_C7,Getriebe_DL501_C7,Motor_EDC17_D4,Motor_ME17_BY,Motor_MED17_SIMOS8_D4
 SG_ ESP_v_Signal : 32|16@1+ (0.01,0) [0.00|655.32] "Unit_KiloMeterPerHour"  Airbag_D4,Getriebe_AL551_951_D4_C7,Getriebe_DL501_C7,Getriebe_VL381_C7,Motor_EDC17_D4,Motor_ME17_BY,Motor_MED17_SIMOS8_D4,SAK_C7,SCR_C7
 SG_ ASR_Keying_Passive : 48|1@1+ (1.0,0.0) [0.0|1] ""  Airbag_D4,Getriebe_AL551_951_D4_C7,Getriebe_DL501_C7,Getriebe_VL381_C7,Motor_EDC17_D4,Motor_ME17_BY,Motor_MED17_SIMOS8_D4
 SG_ ESP_Keying_Passive : 49|1@1+ (1.0,0.0) [0.0|1] ""  Airbag_D4,Getriebe_AL551_951_D4_C7,Getriebe_DL501_C7,Getriebe_VL381_C7,Motor_EDC17_D4,Motor_ME17_BY,Motor_MED17_SIMOS8_D4
 SG_ ESP_SystemStatus : 50|1@1+ (1.0,0.0) [0.0|1] ""  Airbag_D4,Motor_EDC17_D4,Motor_ME17_BY,Motor_MED17_SIMOS8_D4
 SG_ ASR_ShiftIntervention : 51|2@1+ (1.0,0.0) [0.0|3] ""  Airbag_D4,Getriebe_AL551_951_D4_C7,Getriebe_DL501_C7,Getriebe_VL381_C7
 SG_ OBD_RoughRoad : 53|1@1+ (1.0,0.0) [0.0|1] ""  Motor_ME17_BY,Motor_MED17_SIMOS8_D4
 SG_ OBD_QBit_RoughRoad : 54|1@1+ (1.0,0.0) [0.0|1] ""  Motor_ME17_BY,Motor_MED17_SIMOS8_D4
 SG_ ESP_QBit_v_Signal : 55|1@1+ (1.0,0.0) [0.0|1] ""  Airbag_D4,Getriebe_AL551_951_D4_C7,Getriebe_DL501_C7,Getriebe_VL381_C7,Motor_EDC17_D4,Motor_ME17_BY,Motor_MED17_SIMOS8_D4,SCR_C7
 SG_ ABS_Braking : 56|1@1+ (1.0,0.0) [0.0|1] ""  Airbag_D4,EPB_D4,Getriebe_AL551_951_D4_C7,Getriebe_DL501_C7,Getriebe_VL381_C7,Motor_EDC17_D4,Motor_ME17_BY,Motor_MED17_SIMOS8_D4
 SG_ ASR_Req : 57|1@1+ (1.0,0.0) [0.0|1] ""  Airbag_D4,Getriebe_AL551_951_D4_C7,Getriebe_DL501_C7,Getriebe_VL381_C7,Motor_EDC17_D4,Motor_ME17_BY,Motor_MED17_SIMOS8_D4
 SG_ MSR_Req : 58|1@1+ (1.0,0.0) [0.0|1] ""  Airbag_D4,Getriebe_VL381_C7,Motor_EDC17_D4,Motor_ME17_BY,Motor_MED17_SIMOS8_D4
 SG_ EBV_Intervention : 59|1@1+ (1.0,0.0) [0.0|1] ""  Airbag_D4,Getriebe_AL551_951_D4_C7,Getriebe_DL501_C7,Motor_EDC17_D4,Motor_ME17_BY,Motor_MED17_SIMOS8_D4
 SG_ EDS_Intervention : 60|1@1+ (1.0,0.0) [0.0|1] ""  Airbag_D4,Getriebe_AL551_951_D4_C7,Getriebe_DL501_C7,Getriebe_VL381_C7,Motor_EDC17_D4,Motor_ME17_BY,Motor_MED17_SIMOS8_D4
 SG_ ESP_Intervention : 61|1@1+ (1.0,0.0) [0.0|1] ""  Airbag_D4,Getriebe_AL551_951_D4_C7,Getriebe_DL501_C7,Getriebe_VL381_C7,Motor_EDC17_D4,Motor_ME17_BY,Motor_MED17_SIMOS8_D4
 SG_ ESP_ASP : 62|1@1+ (1.0,0.0) [0.0|1] ""  Motor_EDC17_D4,Motor_ME17_BY,Motor_MED17_SIMOS8_D4
 SG_ ESP_KD_Error : 63|1@1+ (1.0,0.0) [0.0|1] ""  Vector__XXX

BO_ 257 ESP_02: 8 Gateway_D4C7
 SG_ ESP_02_CHK : 0|8@1+ (1,0) [0|255] ""  Airbag_D4,EPB_D4,Getriebe_AL551_951_D4_C7,Getriebe_DL501_C7,Getriebe_VL381_C7,Motor_EDC17_D4,Motor_ME17_BY,Motor_MED17_SIMOS8_D4
 SG_ COUNTER : 8|4@1+ (1,0) [0|15] ""  Airbag_D4,EPB_D4,Getriebe_AL551_951_D4_C7,Getriebe_DL501_C7,Getriebe_VL381_C7,Motor_EDC17_D4,Motor_ME17_BY,Motor_MED17_SIMOS8_D4
 SG_ ESP_QBit_YawRate : 12|1@1+ (1.0,0.0) [0.0|1] ""  Airbag_D4
 SG_ ESP_QBit_LongAccel : 13|1@1+ (1.0,0.0) [0.0|1] ""  Airbag_D4,EPB_D4,Getriebe_AL551_951_D4_C7,Getriebe_DL501_C7,Getriebe_VL381_C7,Motor_EDC17_D4,Motor_ME17_BY,Motor_MED17_SIMOS8_D4
 SG_ ESP_QBit_LatAccel : 14|1@1+ (1.0,0.0) [0.0|1] ""  Airbag_D4,Getriebe_AL551_951_D4_C7,Getriebe_DL501_C7,Motor_EDC17_D4,Motor_ME17_BY,Motor_MED17_SIMOS8_D4
 SG_ ESP_Stillstandsflag : 15|1@1+ (1.0,0.0) [0.0|1] ""  Motor_EDC17_D4,Motor_ME17_BY,Motor_MED17_SIMOS8_D4
 SG_ ESP_LateralAccel : 16|8@1+ (0.01,-1.27) [-1.27|1.27] "Unit_ForceOfGravi"  Airbag_D4,Getriebe_AL551_951_D4_C7,Getriebe_DL501_C7,Motor_EDC17_D4,Motor_ME17_BY,Motor_MED17_SIMOS8_D4
 SG_ ESP_LongAccel : 24|10@1+ (0.03125,-16) [-16.00000|15.90625] "Unit_MeterPerSeconSquar"  Airbag_D4,EPB_D4,Getriebe_AL551_951_D4_C7,Getriebe_DL501_C7,Getriebe_VL381_C7,Motor_EDC17_D4,Motor_ME17_BY,Motor_MED17_SIMOS8_D4
 SG_ ESP_Verteil_RollTorque : 34|5@1+ (0.1,-1) [-1.0|1.0] ""  Vector__XXX
 SG_ ESP_QBit_Req_Vert_Roll : 39|1@1+ (1.0,0.0) [0.0|1] ""  Vector__XXX
 SG_ ESP_YawRate : 40|14@1+ (0.01,0) [0.00|163.82] "Unit_DegreOfArcPerSecon"  Airbag_D4
 SG_ ESP_VZ_YawRate : 54|1@1+ (1.0,0.0) [0.0|1] ""  Airbag_D4
 SG_ ESP_Notbremsanzeige : 55|1@1+ (1.0,0.0) [0.0|1] ""  Vector__XXX
 SG_ ESP_VoltageReq : 56|1@1+ (1.0,0.0) [0.0|1] ""  Vector__XXX
 SG_ ESP_PLA_Abort : 57|3@1+ (1.0,0.0) [0.0|7] ""  Vector__XXX
 SG_ ESP_Status_ESP_PLA : 60|4@1+ (1.0,0.0) [0.0|15] ""  Vector__XXX

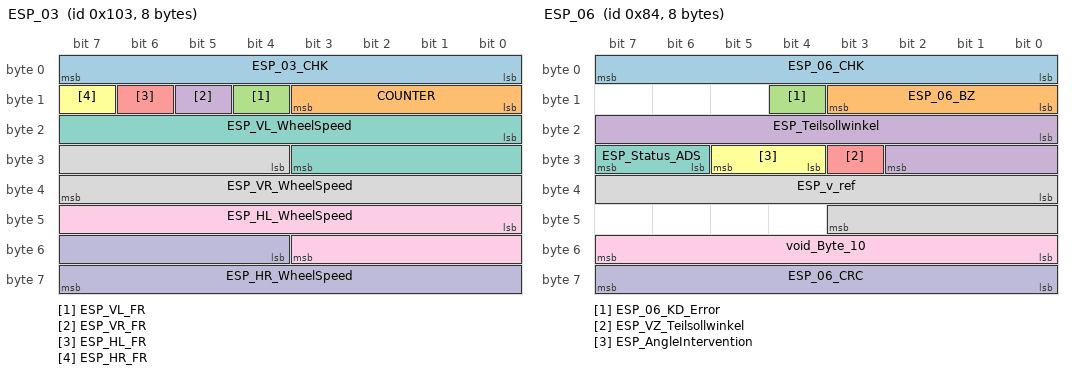
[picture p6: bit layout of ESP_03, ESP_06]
BO_ 259 ESP_03: 8 Gateway_D4C7
 SG_ ESP_03_CHK : 0|8@1+ (1,0) [0|255] ""  Airbag_D4,EPB_D4,Getriebe_AL551_951_D4_C7,Getriebe_DL501_C7,Getriebe_VL381_C7,LWS_D4,Motor_EDC17_D4,Motor_ME17_BY,Motor_MED17_SIMOS8_D4,SCU_D4
 SG_ COUNTER : 8|4@1+ (1,0) [0|15] ""  Airbag_D4,EPB_D4,Getriebe_AL551_951_D4_C7,Getriebe_DL501_C7,Getriebe_VL381_C7,LWS_D4,Motor_EDC17_D4,Motor_ME17_BY,Motor_MED17_SIMOS8_D4,SCU_D4
 SG_ ESP_VL_FR : 12|1@1+ (1.0,0.0) [0.0|1] ""  Airbag_D4,EPB_D4,Getriebe_AL551_951_D4_C7,Getriebe_DL501_C7,Motor_EDC17_D4,Motor_ME17_BY,Motor_MED17_SIMOS8_D4,SCU_D4
 SG_ ESP_VR_FR : 13|1@1+ (1.0,0.0) [0.0|1] ""  Airbag_D4,EPB_D4,Getriebe_AL551_951_D4_C7,Getriebe_DL501_C7,Motor_EDC17_D4,Motor_ME17_BY,Motor_MED17_SIMOS8_D4,SCU_D4
 SG_ ESP_HL_FR : 14|1@1+ (1.0,0.0) [0.0|1] ""  Airbag_D4,EPB_D4,Getriebe_AL551_951_D4_C7,Getriebe_DL501_C7,Motor_EDC17_D4,Motor_ME17_BY,Motor_MED17_SIMOS8_D4,SCU_D4
 SG_ ESP_HR_FR : 15|1@1+ (1.0,0.0) [0.0|1] ""  Airbag_D4,EPB_D4,Getriebe_AL551_951_D4_C7,Getriebe_DL501_C7,Motor_EDC17_D4,Motor_ME17_BY,Motor_MED17_SIMOS8_D4,SCU_D4
 SG_ ESP_VL_WheelSpeed : 16|12@1+ (0.1,0) [0.0|409.2] "Unit_KiloMeterPerHour"  Airbag_D4,EPB_D4,Getriebe_AL551_951_D4_C7,Getriebe_DL501_C7,Getriebe_VL381_C7,LWS_D4,SCU_D4
 SG_ ESP_VR_WheelSpeed : 28|12@1+ (0.1,0) [0.0|409.2] "Unit_KiloMeterPerHour"  Airbag_D4,EPB_D4,Getriebe_AL551_951_D4_C7,Getriebe_DL501_C7,Getriebe_VL381_C7,LWS_D4,SCU_D4
 SG_ ESP_HL_WheelSpeed : 40|12@1+ (0.1,0) [0.0|409.2] "Unit_KiloMeterPerHour"  Airbag_D4,EPB_D4,Getriebe_AL551_951_D4_C7,Getriebe_DL501_C7,Getriebe_VL381_C7,LWS_D4,SCU_D4
 SG_ ESP_HR_WheelSpeed : 52|12@1+ (0.1,0) [0.0|409.2] "Unit_KiloMeterPerHour"  Airbag_D4,EPB_D4,Getriebe_AL551_951_D4_C7,Getriebe_DL501_C7,Getriebe_VL381_C7,LWS_D4,SCU_D4

BO_ 776 ESP_04: 8 Gateway_D4C7
 SG_ ESP_Meldungen : 0|3@1+ (1.0,0.0) [0.0|7] ""  Vector__XXX
 SG_ ESP_HDC_FuncLamp : 3|1@1+ (1.0,0.0) [0.0|1] ""  Vector__XXX
 SG_ ESP_Lamp : 4|1@1+ (1.0,0.0) [0.0|1] ""  Vector__XXX
 SG_ ABS_Lamp : 5|1@1+ (1.0,0.0) [0.0|1] ""  Vector__XXX
 SG_ BK_Lamp : 6|1@1+ (1.0,0.0) [0.0|1] ""  Vector__XXX
 SG_ ESP_Acoustic : 7|2@1+ (1.0,0.0) [0.0|3] ""  Vector__XXX
 SG_ ESP_Diagnostics : 9|1@1+ (1.0,0.0) [0.0|1] ""  SCU_D4
 SG_ ESP_Textanzeigen_02 : 10|5@1+ (1.0,0.0) [0.0|31] ""  Vector__XXX
 SG_ ESP_Off_Lamp : 15|1@1+ (1.0,0.0) [0.0|1] ""  Vector__XXX
 SG_ ESP_m_WheelSpeed : 16|15@1+ (0.002,0) [0.000|65.278] "Unit_Hertz"  Vector__XXX
 SG_ ESP_ASR_Lamp : 31|1@1+ (1.0,0.0) [0.0|1] ""  Vector__XXX
 SG_ ESP_DistPulse_VA : 32|11@1+ (1,0) [0|2047] ""  Vector__XXX
 SG_ ESP_ErrorStatus_DistPulse : 43|1@1+ (1.0,0.0) [0.0|1] ""  Vector__XXX
 SG_ ESP_DistPulse_Overflow : 44|1@1+ (1.0,0.0) [0.0|1] ""  Vector__XXX
 SG_ ESP_QBit_DistPulse_VA : 45|1@1+ (1.0,0.0) [0.0|1] ""  Vector__XXX
 SG_ ESP_Displaywarnungen : 46|2@1+ (1.0,0.0) [0.0|3] ""  Vector__XXX
 SG_ ESP_HDC_ControlSpeed : 48|7@1+ (0.32,0) [0.32|39.68] "Unit_KiloMeterPerHour"  Vector__XXX
 SG_ ESP_BKV_Warning : 55|1@1+ (1.0,0.0) [0.0|1] ""  Vector__XXX
 SG_ ESP_ToothCount : 56|8@1+ (1,0) [0|255] ""  Vector__XXX

BO_ 262 ESP_05: 8 Gateway_D4C7
 SG_ ESP_05_CHK : 0|8@1+ (1,0) [0|255] ""  EPB_D4,Getriebe_AL551_951_D4_C7,Getriebe_DL501_C7,Getriebe_VL381_C7,Motor_EDC17_D4,Motor_ME17_BY,Motor_MED17_SIMOS8_D4,SCU_D4
 SG_ COUNTER : 8|4@1+ (1,0) [0|15] ""  EPB_D4,Getriebe_AL551_951_D4_C7,Getriebe_DL501_C7,Getriebe_VL381_C7,Motor_EDC17_D4,Motor_ME17_BY,Motor_MED17_SIMOS8_D4,SCU_D4
 SG_ ESP_QBit_BrakePressure : 12|1@1+ (1.0,0.0) [0.0|1] ""  EPB_D4,Getriebe_AL551_951_D4_C7,Getriebe_DL501_C7,Motor_EDC17_D4,Motor_ME17_BY,Motor_MED17_SIMOS8_D4
 SG_ ESP_QBit_Driver_Brakes : 13|1@1+ (1.0,0.0) [0.0|1] ""  Motor_EDC17_D4,Motor_ME17_BY,Motor_MED17_SIMOS8_D4
 SG_ ESP_Threshold_Vacuum : 14|2@1+ (1.0,0.0) [0.0|3] ""  Vector__XXX
 SG_ ESP_BrakePressure : 16|10@1+ (0.3,-30) [-30.0|276.6] "Unit_Bar"  EPB_D4,Getriebe_AL551_951_D4_C7,Getriebe_DL501_C7,Motor_EDC17_D4,Motor_ME17_BY,Motor_MED17_SIMOS8_D4
 SG_ ESP_Driver_Brakes : 26|1@1+ (1.0,0.0) [0.0|1] ""  Motor_EDC17_D4,Motor_ME17_BY,Motor_MED17_SIMOS8_D4
 SG_ ESP_Decel_TSK_Active : 27|1@1+ (1.0,0.0) [0.0|1] ""  Getriebe_AL551_951_D4_C7,Motor_EDC17_D4,Motor_ME17_BY,Motor_MED17_SIMOS8_D4
 SG_ ESP_SteeringIntervention_ADS : 28|1@1+ (1.0,0.0) [0.0|1] ""  Motor_EDC17_D4,Motor_ME17_BY,Motor_MED17_SIMOS8_D4,SCU_D4
 SG_ ESP_Consistency_TSK : 29|1@1+ (1.0,0.0) [0.0|1] ""  Motor_EDC17_D4,Motor_ME17_BY,Motor_MED17_SIMOS8_D4
 SG_ ESP_BrakeJerk_AWV2 : 30|1@1+ (1.0,0.0) [0.0|1] ""  Vector__XXX
 SG_ ESP_Consistency_AWV2 : 31|1@1+ (1.0,0.0) [0.0|1] ""  Vector__XXX
 SG_ ECD_Error : 32|1@1+ (1.0,0.0) [0.0|1] ""  Motor_EDC17_D4,Motor_ME17_BY,Motor_MED17_SIMOS8_D4
 SG_ ECD_Not_Available : 33|1@1+ (1.0,0.0) [0.0|1] ""  Motor_EDC17_D4,Motor_ME17_BY,Motor_MED17_SIMOS8_D4
 SG_ ESP_Status_BrakesTemp : 34|1@1+ (1.0,0.0) [0.0|1] ""  Motor_EDC17_D4,Motor_ME17_BY,Motor_MED17_SIMOS8_D4
 SG_ ESP_AutoHold_Standby : 35|1@1+ (1.0,0.0) [0.0|1] ""  EPB_D4,Getriebe_AL551_951_D4_C7
 SG_ ESP_HDC_Standby : 36|1@1+ (1.0,0.0) [0.0|1] ""  Vector__XXX
 SG_ ESP_HBA_Active : 37|1@1+ (1.0,0.0) [0.0|1] ""  Vector__XXX
 SG_ ESP_Prefill_Triggered : 38|1@1+ (1.0,0.0) [0.0|1] ""  Vector__XXX
 SG_ ESP_Reversing_Detected : 39|1@1+ (1.0,0.0) [0.0|1] ""  Motor_EDC17_D4,Motor_ME17_BY,Motor_MED17_SIMOS8_D4
 SG_ ESP_Status_HillStartAssist : 40|1@1+ (1.0,0.0) [0.0|1] ""  Motor_EDC17_D4,Motor_MED17_SIMOS8_D4
 SG_ ESP_HDC_Active : 41|1@1+ (1.0,0.0) [0.0|1] ""  Vector__XXX
 SG_ ESP_StartStop_Info : 42|2@1+ (1.0,0.0) [0.0|3] ""  Motor_EDC17_D4,Motor_ME17_BY,Motor_MED17_SIMOS8_D4
 SG_ ESP_Interv_HL : 44|1@1+ (1.0,0.0) [0.0|1] ""  Vector__XXX
 SG_ ESP_Interv_HR : 45|1@1+ (1.0,0.0) [0.0|1] ""  Vector__XXX
 SG_ ESP_Interv_VL : 46|1@1+ (1.0,0.0) [0.0|1] ""  Vector__XXX
 SG_ ESP_Interv_VR : 47|1@1+ (1.0,0.0) [0.0|1] ""  Vector__XXX
 SG_ ESP_BKV_Vacuum : 48|8@1+ (4,0) [0|1012] "Unit_MilliBar"  Motor_EDC17_D4,Motor_ME17_BY,Motor_MED17_SIMOS8_D4
 SG_ ESP_AutoHold_Active : 56|1@1+ (1.0,0.0) [0.0|1] ""  EPB_D4,Getriebe_AL551_951_D4_C7,Getriebe_DL501_C7,Getriebe_VL381_C7,Motor_EDC17_D4,Motor_ME17_BY,Motor_MED17_SIMOS8_D4
 SG_ ESP_FStatus_HillStartAssist : 57|1@1+ (1.0,0.0) [0.0|1] ""  Vector__XXX
 SG_ ESP_Decel_EPB_Active : 58|1@1+ (1.0,0.0) [0.0|1] ""  EPB_D4,Getriebe_AL551_951_D4_C7
 SG_ ECD_BrakeLight : 59|1@1+ (1.0,0.0) [0.0|1] ""  Motor_EDC17_D4,Motor_ME17_BY,Motor_MED17_SIMOS8_D4
 SG_ ESP_Decel_EPB_Avail : 60|1@1+ (1.0,0.0) [0.0|1] ""  EPB_D4
 SG_ ESP_Status_BrakePressure : 61|1@1+ (1.0,0.0) [0.0|1] ""  EPB_D4,Motor_EDC17_D4,Motor_ME17_BY,Motor_MED17_SIMOS8_D4
 SG_ ESP_Request_EPB : 62|2@1+ (1.0,0.0) [0.0|3] ""  EPB_D4

BO_ 132 ESP_06: 8 ESP_D4
 SG_ ESP_06_CHK : 0|8@1+ (1,0) [0|255] ""  SCU_D4
 SG_ ESP_06_BZ : 8|4@1+ (1,0) [0|15] ""  Airbag_D4,SCU_D4
 SG_ ESP_06_KD_Error : 12|1@1+ (1.0,0.0) [0.0|1] ""  Gateway_D4C7
 SG_ ESP_Teilsollwinkel : 16|11@1+ (0.1,0) [0.0|204.7] "Unit_DegreOfArc"  SCU_D4
 SG_ ESP_VZ_Teilsollwinkel : 27|1@1+ (1.0,0.0) [0.0|1] ""  SCU_D4
 SG_ ESP_AngleIntervention : 28|2@1+ (1.0,0.0) [0.0|3] ""  SCU_D4
 SG_ ESP_Status_ADS : 30|2@1+ (1.0,0.0) [0.0|3] ""  SCU_D4
 SG_ ESP_v_ref : 32|12@1+ (0.125,0) [0.000|511.500] "Unit_KiloMeterPerHour"  Airbag_D4
 SG_ void_Byte_10 : 48|8@1+ (1,0) [0|255] ""  Vector__XXX
 SG_ ESP_06_CRC : 56|8@1+ (1,0) [0|255] ""  Airbag_D4,SCU_D4

BO_ 914 ESP_07_FR: 8 Gateway_D4C7
 SG_ ESP_07_CHK : 0|8@1+ (1,0) [0|255] ""  LWS_D4,Motor_EDC17_D4,Motor_ME17_BY,Motor_MED17_SIMOS8_D4
 SG_ ESP_07_BZ : 8|4@1+ (1,0) [0|15] ""  LWS_D4,Motor_EDC17_D4,Motor_ME17_BY,Motor_MED17_SIMOS8_D4
 SG_ ESP_ACC_LDE : 12|1@1+ (1.0,0.0) [0.0|1] ""  Vector__XXX
 SG_ ESP_Quattro_Drive : 13|1@1+ (1.0,0.0) [0.0|1] ""  Vector__XXX
 SG_ ESP_Coding_ADS : 14|2@1+ (1.0,0.0) [0.0|3] ""  LWS_D4
 SG_ ESP_RTA_HL : 16|8@1+ (0.048828125,-6.20117) [-6.201170000|6.152345625] "Unit_PerCent"  Vector__XXX
 SG_ ESP_RTA_HR : 24|8@1+ (0.048828125,-6.20117) [-6.201170000|6.152345625] "Unit_PerCent"  Vector__XXX
 SG_ ESP_RTA_VR : 32|8@1+ (0.048828125,-6.20117) [-6.201170000|6.152345625] "Unit_PerCent"  Vector__XXX
 SG_ OBD_Error_WheelSensor_HL : 40|4@1+ (1.0,0.0) [0.0|15] ""  Motor_EDC17_D4,Motor_ME17_BY,Motor_MED17_SIMOS8_D4
 SG_ OBD_Error_WheelSensor_HR : 44|4@1+ (1.0,0.0) [0.0|15] ""  Motor_EDC17_D4,Motor_ME17_BY,Motor_MED17_SIMOS8_D4
 SG_ OBD_Error_WheelSensor_VL : 48|4@1+ (1.0,0.0) [0.0|15] ""  Motor_EDC17_D4,Motor_ME17_BY,Motor_MED17_SIMOS8_D4
 SG_ OBD_Error_WheelSensor_VR : 52|4@1+ (1.0,0.0) [0.0|15] ""  Motor_EDC17_D4,Motor_ME17_BY,Motor_MED17_SIMOS8_D4
 SG_ ESP_Qualification_DriveType : 56|1@1+ (1.0,0.0) [0.0|1] ""  Vector__XXX
 SG_ ESP_Offroad_Mode : 57|1@1+ (1.0,0.0) [0.0|1] ""  Vector__XXX
 SG_ ESP_MKB_ausloesbar : 58|1@1+ (1.0,0.0) [0.0|1] ""  Vector__XXX
 SG_ ESP_MKB_Status : 59|1@1+ (1.0,0.0) [0.0|1] ""  Vector__XXX
 SG_ ESP_CM_Variant : 60|1@1+ (1.0,0.0) [0.0|1] ""  Vector__XXX
 SG_ ESP_OBD_Status : 61|1@1+ (1.0,0.0) [0.0|1] ""  Vector__XXX

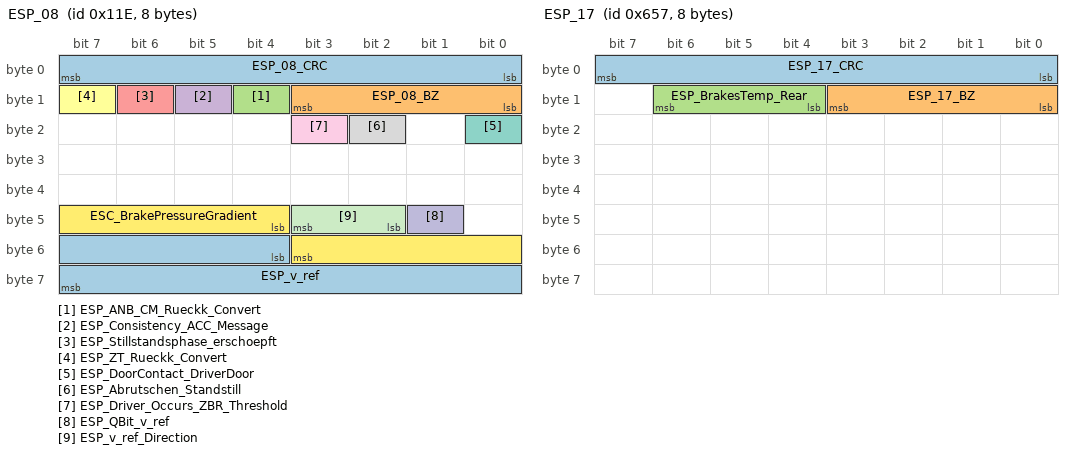
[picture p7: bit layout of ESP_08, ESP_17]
BO_ 286 ESP_08: 8 Vector__XXX
 SG_ ESP_08_CRC : 0|8@1+ (1,0) [0|255] "" Vector__XXX
 SG_ ESP_08_BZ : 8|4@1+ (1,0) [0|15] "" Vector__XXX
 SG_ ESP_ANB_CM_Rueckk_Convert : 12|1@1+ (1,0) [0|1] "" Vector__XXX
 SG_ ESP_Consistency_ACC_Message : 13|1@1+ (1,0) [0|1] "" Vector__XXX
 SG_ ESP_Stillstandsphase_erschoepft : 14|1@1+ (1,0) [0|1] "" Vector__XXX
 SG_ ESP_ZT_Rueckk_Convert : 15|1@1+ (1,0) [0|1] "" Vector__XXX
 SG_ ESP_DoorContact_DriverDoor : 16|1@1+ (1,0) [0|1] "" Vector__XXX
 SG_ ESP_Abrutschen_Standstill : 18|1@1+ (1,0) [0|1] "" Vector__XXX
 SG_ ESP_Driver_Occurs_ZBR_Threshold : 19|1@1+ (1,0) [0|1] "" Vector__XXX
 SG_ ESP_QBit_v_ref : 41|1@1+ (1,0) [0|1] "" Vector__XXX
 SG_ ESP_v_ref_Direction : 42|2@1+ (1,0) [0|3] "" Vector__XXX
 SG_ ESC_BrakePressureGradient : 44|8@1+ (10,0) [0|2500] "Unit_BarPerSecon" Vector__XXX
 SG_ ESP_v_ref : 52|12@1+ (0.125,0) [0|511.5] "Unit_KiloMeterPerHour" Vector__XXX

BO_ 1623 ESP_17: 8 ESP_D4
 SG_ ESP_17_CRC : 0|8@1+ (1,0) [0|255] ""  EPB_D4
 SG_ ESP_17_BZ : 8|4@1+ (1,0) [0|15] ""  EPB_D4
 SG_ ESP_BrakesTemp_Rear : 12|3@1+ (1.0,0.0) [0.0|7] ""  EPB_D4

BO_ 924 Gateway_05: 8 Gateway_D4C7
 SG_ BCM1_02_Old : 0|1@1+ (1.0,0.0) [0.0|1] ""  Motor_EDC17_D4,Motor_ME17_BY,Motor_MED17_SIMOS8_D4
 SG_ Wiper_01_Old : 1|1@1+ (1.0,0.0) [0.0|1] ""  Motor_EDC17_D4,Motor_ME17_BY,Motor_MED17_SIMOS8_D4
 SG_ Climate_02_Old : 2|1@1+ (1.0,0.0) [0.0|1] ""  Vector__XXX
 SG_ BCM1_01_Old : 3|1@1+ (1.0,0.0) [0.0|1] ""  EPB_D4,Motor_EDC17_D4,Motor_ME17_BY,Motor_MED17_SIMOS8_D4
 SG_ ESP_07_Old : 4|1@1+ (1.0,0.0) [0.0|1] ""  Airbag_D4,Motor_EDC17_D4,Motor_ME17_BY,Motor_MED17_SIMOS8_D4
 SG_ DoorECU_BT_1_Old : 5|1@1+ (1.0,0.0) [0.0|1] ""  Motor_EDC17_D4,Motor_ME17_BY,Motor_MED17_SIMOS8_D4
 SG_ DoorECU_HL_1_Old : 6|1@1+ (1.0,0.0) [0.0|1] ""  Motor_EDC17_D4,Motor_ME17_BY,Motor_MED17_SIMOS8_D4
 SG_ DoorECU_HR_1_Old : 7|1@1+ (1.0,0.0) [0.0|1] ""  Motor_EDC17_D4,Motor_ME17_BY,Motor_MED17_SIMOS8_D4
 SG_ Engine_02_Old : 8|1@1+ (1.0,0.0) [0.0|1] ""  Vector__XXX
 SG_ Climate_Sensor_02_Old : 9|1@1+ (1.0,0.0) [0.0|1] ""  Motor_EDC17_D4,Motor_ME17_BY,Motor_MED17_SIMOS8_D4,SCR_C7
 SG_ DoorECU_FT_1_Old : 10|1@1+ (1.0,0.0) [0.0|1] ""  Getriebe_AL551_951_D4_C7,Motor_EDC17_D4,Motor_ME17_BY,Motor_MED17_SIMOS8_D4
 SG_ Engine_05_Old : 11|1@1+ (1.0,0.0) [0.0|1] ""  Vector__XXX
 SG_ QSP_01_Old : 12|1@1+ (1.0,0.0) [0.0|1] ""  Motor_EDC17_D4,Motor_ME17_BY,Motor_MED17_SIMOS8_D4
 SG_ ParkAssist_01_Old : 13|1@1+ (1.0,0.0) [0.0|1] ""  Motor_EDC17_D4,Motor_ME17_BY,Motor_MED17_SIMOS8_D4
 SG_ Chassis_02_Old : 14|1@1+ (1.0,0.0) [0.0|1] ""  Motor_EDC17_D4,Motor_ME17_BY,Motor_MED17_SIMOS8_D4
 SG_ GW_05_va_27 : 15|1@1+ (1,0) [0|1] ""  Vector__XXX
 SG_ BCM1_MH_WIV_Switch : 16|1@1+ (1.0,0.0) [0.0|1] ""  Motor_EDC17_D4,Motor_ME17_BY,Motor_MED17_SIMOS8_D4
 SG_ Wiper_Front_Active : 17|1@1+ (1.0,0.0) [0.0|1] ""  Motor_EDC17_D4,Motor_ME17_BY,Motor_MED17_SIMOS8_D4
 SG_ BCM1_ReversingLight_Switch : 18|1@1+ (1.0,0.0) [0.0|1] ""  EPB_D4,Motor_EDC17_D4,Motor_ME17_BY,Motor_MED17_SIMOS8_D4
 SG_ MO_Status_NormalOperation_01 : 19|1@1+ (1.0,0.0) [0.0|1] ""  Vector__XXX
 SG_ TERM_AuxHeater_Enable : 20|1@1+ (1.0,0.0) [0.0|1] ""  Vector__XXX
 SG_ BCM1_ForwardGear_Engaged : 21|1@1+ (1.0,0.0) [0.0|1] ""  EPB_D4
 SG_ ESP_Coding_ADS : 22|2@1+ (1.0,0.0) [0.0|3] ""  Airbag_D4,Motor_EDC17_D4,Motor_ME17_BY,Motor_MED17_SIMOS8_D4
 SG_ QSP_StartStop_Info : 24|2@1+ (1.0,0.0) [0.0|3] ""  Motor_EDC17_D4,Motor_ME17_BY,Motor_MED17_SIMOS8_D4
 SG_ FA_StartStop_Info : 26|2@1+ (1.0,0.0) [0.0|3] ""  Motor_EDC17_D4,Motor_ME17_BY,Motor_MED17_SIMOS8_D4
 SG_ PH_StartStop_Info : 28|2@1+ (1.0,0.0) [0.0|3] ""  Motor_EDC17_D4,Motor_ME17_BY,Motor_MED17_SIMOS8_D4
 SG_ TERM_FoggingRisk : 30|1@1+ (1.0,0.0) [0.0|1] ""  Vector__XXX
 SG_ BCM1_GLW_HighBeam_Req : 31|1@1+ (1.0,0.0) [0.0|1] ""  Vector__XXX
 SG_ BCM1_RHeadlights_Veh_Req : 32|1@1+ (1.0,0.0) [0.0|1] ""  Vector__XXX
 SG_ FT_Door_Opened : 33|1@1+ (1.0,0.0) [0.0|1] ""  Getriebe_AL551_951_D4_C7,Motor_EDC17_D4,Motor_ME17_BY,Motor_MED17_SIMOS8_D4
 SG_ MO_Handshake_STH : 34|1@1+ (1.0,0.0) [0.0|1] ""  Vector__XXX
 SG_ FT_ParkPawl : 35|1@1+ (1.0,0.0) [0.0|1] ""  Motor_EDC17_D4,Motor_ME17_BY,Motor_MED17_SIMOS8_D4
 SG_ BCM1_OBD_FStatus_ATemp : 36|4@1+ (1.0,0.0) [0.0|15] ""  Airbag_D4,Motor_EDC17_D4,Motor_ME17_BY,Motor_MED17_SIMOS8_D4,SCR_C7
 SG_ BCM1_Outside_Temp_Unfilt : 40|8@1+ (0.5,-50) [-50.0|76.0] "Unit_DegreCelsi"  Airbag_D4,Motor_EDC17_D4,Motor_ME17_BY,Motor_MED17_SIMOS8_D4,SCR_C7
 SG_ BCM1_OilPressure_Switch : 48|1@1+ (1.0,0.0) [0.0|1] ""  Vector__XXX
 SG_ BCM1_OilPressure_Switch_2 : 49|1@1+ (1.0,0.0) [0.0|1] ""  Vector__XXX
 SG_ BT_Door_Opened : 50|1@1+ (1.0,0.0) [0.0|1] ""  Motor_EDC17_D4,Motor_ME17_BY,Motor_MED17_SIMOS8_D4
 SG_ HL_Door_Opened : 51|1@1+ (1.0,0.0) [0.0|1] ""  Motor_EDC17_D4,Motor_ME17_BY,Motor_MED17_SIMOS8_D4
 SG_ HR_Door_Opened : 52|1@1+ (1.0,0.0) [0.0|1] ""  Motor_EDC17_D4,Motor_ME17_BY,Motor_MED17_SIMOS8_D4
 SG_ BCM1_Adaptive_LightDistribution_Req : 53|1@1+ (1.0,0.0) [0.0|1] ""  Vector__XXX
 SG_ BCM1_Sliding_Leuchtw_Req : 54|1@1+ (1.0,0.0) [0.0|1] ""  Vector__XXX
 SG_ BCM1_Switch_StartStop : 55|1@1+ (1.0,0.0) [0.0|1] ""  Motor_EDC17_D4,Motor_ME17_BY,Motor_MED17_SIMOS8_D4
 SG_ ESP_Offroad_Mode : 56|1@1+ (1.0,0.0) [0.0|1] ""  Vector__XXX
 SG_ MO_Enable_Recup : 57|2@1+ (1.0,0.0) [0.0|3] ""  Vector__XXX

BO_ 927 Gateway_06: 8 XXX
 SG_ FROM_BeltBuckle_FA : 30|2@1+ (1,0) [0|3] "" XXX

BO_ 1604 Gateway_11: 8 Gateway_D4C7
 SG_ SMLS_01_Old : 0|1@1+ (1.0,0.0) [0.0|1] ""  Motor_EDC17_D4,Motor_ME17_BY,Motor_MED17_SIMOS8_D4
 SG_ HUD_01_Old : 1|1@1+ (1,0) [0|1] ""  Vector__XXX
 SG_ BCM1_01_Old : 2|1@1+ (1.0,0.0) [0.0|1] ""  Vector__XXX
 SG_ BCM1_02_Old : 3|1@1+ (1.0,0.0) [0.0|1] ""  Motor_EDC17_D4,Motor_ME17_BY,Motor_MED17_SIMOS8_D4
 SG_ BCM2_02_Old : 4|1@1+ (1.0,0.0) [0.0|1] ""  Getriebe_VL381_C7
 SG_ HYB_Req_E_Mode_Old : 5|1@1+ (1.0,0.0) [0.0|1] ""  Vector__XXX
 SG_ BCM1_04_Old : 6|1@1+ (1,0) [0|1] ""  Vector__XXX
 SG_ ESP_04_Old : 7|1@1+ (1.0,0.0) [0.0|1] ""  SCU_D4
 SG_ GW_11_va_20 : 8|1@1+ (1,0) [0|1] ""  Vector__XXX
 SG_ GW_11_va_21 : 9|1@1+ (1,0) [0|1] ""  Vector__XXX
 SG_ GW_11_va_22 : 10|1@1+ (1,0) [0|1] ""  Vector__XXX
 SG_ GW_11_va_23 : 11|1@1+ (1,0) [0|1] ""  Vector__XXX
 SG_ GW_11_va_24 : 12|1@1+ (1,0) [0|1] ""  Vector__XXX
 SG_ GW_11_va_25 : 13|1@1+ (1,0) [0|1] ""  Vector__XXX
 SG_ GW_11_va_26 : 14|1@1+ (1,0) [0|1] ""  Vector__XXX
 SG_ GW_11_va_27 : 15|1@1+ (1,0) [0|1] ""  Vector__XXX
 SG_ BH_Indicator_Left : 16|1@1+ (1.0,0.0) [0.0|1] ""  Motor_EDC17_D4,Motor_ME17_BY,Motor_MED17_SIMOS8_D4
 SG_ BH_Indicator_Right : 17|1@1+ (1.0,0.0) [0.0|1] ""  Motor_EDC17_D4,Motor_ME17_BY,Motor_MED17_SIMOS8_D4
 SG_ BM_Motorway : 18|1@1+ (1.0,0.0) [0.0|1] ""  Vector__XXX
 SG_ BH_HighBeam : 19|1@1+ (1.0,0.0) [0.0|1] ""  Vector__XXX
 SG_ BH_HeadlightFlash : 20|1@1+ (1.0,0.0) [0.0|1] ""  Vector__XXX
 SG_ BCM1_MH_Switch : 21|1@1+ (1.0,0.0) [0.0|1] ""  Motor_EDC17_D4,Motor_ME17_BY,Motor_MED17_SIMOS8_D4
 SG_ HYB_Req_E_Mode : 22|1@1+ (1.0,0.0) [0.0|1] ""  Vector__XXX
 SG_ HUD_NV_in_Display : 23|1@1+ (1.0,0.0) [0.0|1] ""  Vector__XXX
 SG_ BCM1_Tourist_Light_Req : 24|1@1+ (1.0,0.0) [0.0|1] ""  Vector__XXX
 SG_ LV_LowBeam_Left_def : 25|1@1+ (1.0,0.0) [0.0|1] ""  Vector__XXX
 SG_ LV_LowBeam_Right_def : 26|1@1+ (1.0,0.0) [0.0|1] ""  Vector__XXX
 SG_ LV_LowBeam_Display : 27|1@1+ (1.0,0.0) [0.0|1] ""  Vector__XXX
 SG_ LV_AFL_Active_Display : 28|1@1+ (1.0,0.0) [0.0|1] ""  Vector__XXX
 SG_ BCM1_Light_Darkness_Active : 29|1@1+ (1.0,0.0) [0.0|1] ""  Vector__XXX
 SG_ LV_RearFogLight_Display : 30|1@1+ (1.0,0.0) [0.0|1] ""  Vector__XXX
 SG_ BCM1_LeftHandTraffic : 31|1@1+ (1.0,0.0) [0.0|1] ""  Vector__XXX
 SG_ BCM2_P_Locked : 32|1@1+ (1.0,0.0) [0.0|1] ""  Getriebe_VL381_C7
 SG_ BCM1_LDS_Position : 33|3@1+ (1.0,0.0) [0.0|7] ""  Vector__XXX
 SG_ BCM1_AllWeatherLight_Req : 36|1@1+ (1.0,0.0) [0.0|1] ""  Vector__XXX
 SG_ HUD_DisplayFault_NV : 37|1@1+ (1.0,0.0) [0.0|1] ""  Vector__XXX
 SG_ ESP_Diagnostics : 38|1@1+ (1.0,0.0) [0.0|1] ""  SCU_D4

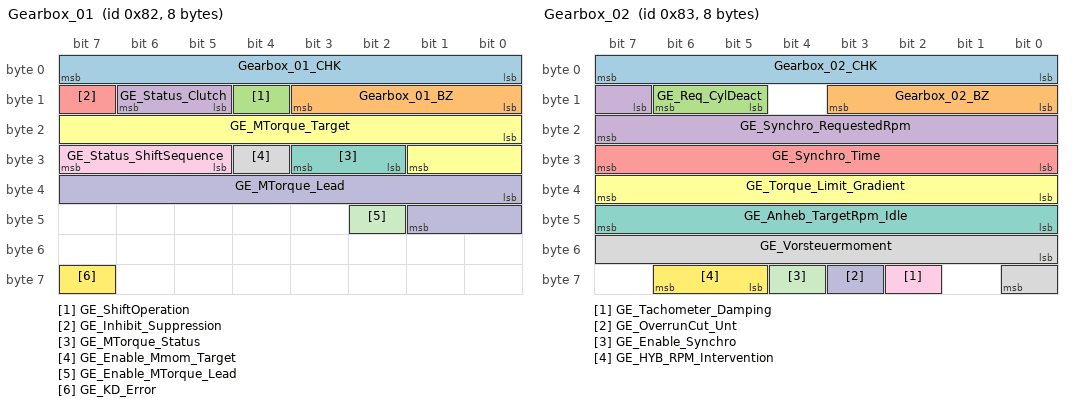
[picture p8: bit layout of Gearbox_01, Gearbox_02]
BO_ 130 Gearbox_01: 8 Getriebe_AL551_951_D4_C7
 SG_ Gearbox_01_CHK : 0|8@1+ (1,0) [0|255] ""  Gateway_D4C7,Motor_EDC17_D4,Motor_ME17_BY,Motor_MED17_SIMOS8_D4
 SG_ Gearbox_01_BZ : 8|4@1+ (1,0) [0|15] ""  Gateway_D4C7,Motor_EDC17_D4,Motor_ME17_BY,Motor_MED17_SIMOS8_D4
 SG_ GE_ShiftOperation : 12|1@1+ (1.0,0.0) [0.0|1] ""  Gateway_D4C7,Motor_EDC17_D4,Motor_ME17_BY,Motor_MED17_SIMOS8_D4
 SG_ GE_Status_Clutch : 13|2@1+ (1.0,0.0) [0.0|3] ""  Gateway_D4C7,Motor_EDC17_D4,Motor_ME17_BY,Motor_MED17_SIMOS8_D4
 SG_ GE_Inhibit_Suppression : 15|1@1+ (1.0,0.0) [0.0|1] ""  Gateway_D4C7,Motor_EDC17_D4,Motor_ME17_BY,Motor_MED17_SIMOS8_D4
 SG_ GE_MTorque_Target : 16|10@1+ (1,0) [0|1021] ""  Gateway_D4C7,Motor_EDC17_D4,Motor_ME17_BY,Motor_MED17_SIMOS8_D4
 SG_ GE_MTorque_Status : 26|2@1+ (1.0,0.0) [0.0|3] ""  Gateway_D4C7,Motor_EDC17_D4,Motor_ME17_BY,Motor_MED17_SIMOS8_D4
 SG_ GE_Enable_Mmom_Target : 28|1@1+ (1,0) [0|1] ""  Gateway_D4C7
 SG_ GE_Status_ShiftSequence : 29|3@1+ (1,0) [0|7] ""  Gateway_D4C7
 SG_ GE_MTorque_Lead : 32|10@1+ (1,0) [0|1021] ""  Gateway_D4C7,Motor_EDC17_D4,Motor_ME17_BY,Motor_MED17_SIMOS8_D4
 SG_ GE_Enable_MTorque_Lead : 42|1@1+ (1.0,0.0) [0.0|1] ""  Gateway_D4C7,Motor_EDC17_D4,Motor_ME17_BY,Motor_MED17_SIMOS8_D4
 SG_ GE_KD_Error : 63|1@1+ (1.0,0.0) [0.0|1] ""  Gateway_D4C7

BO_ 131 Gearbox_02: 8 Getriebe_AL551_951_D4_C7
 SG_ Gearbox_02_CHK : 0|8@1+ (1,0) [0|255] ""  Motor_EDC17_D4,Motor_ME17_BY,Motor_MED17_SIMOS8_D4
 SG_ Gearbox_02_BZ : 8|4@1+ (1,0) [0|15] ""  Motor_EDC17_D4,Motor_ME17_BY,Motor_MED17_SIMOS8_D4
 SG_ GE_Req_CylDeact : 13|2@1+ (1.0,0.0) [0.0|3] ""  Motor_ME17_BY,Motor_MED17_SIMOS8_D4
 SG_ GE_Synchro_RequestedRpm : 15|9@1+ (25,0) [0|12750] "Unit_MinutInver"  Motor_EDC17_D4,Motor_ME17_BY,Motor_MED17_SIMOS8_D4
 SG_ GE_Synchro_Time : 24|8@1+ (20,0) [0|5080] "Unit_MilliSecon"  Motor_EDC17_D4,Motor_ME17_BY,Motor_MED17_SIMOS8_D4
 SG_ GE_Torque_Limit_Gradient : 32|8@1+ (10,0) [0|2540] "Unit_NewtoMeterPerSecon"  Motor_EDC17_D4,Motor_ME17_BY,Motor_MED17_SIMOS8_D4
 SG_ GE_Anheb_TargetRpm_Idle : 40|8@1+ (10,0) [0|2540] "Unit_MinutInver"  Motor_EDC17_D4,Motor_ME17_BY,Motor_MED17_SIMOS8_D4
 SG_ GE_Vorsteuermoment : 48|9@1+ (1,0) [0|509] ""  Motor_EDC17_D4,Motor_ME17_BY,Motor_MED17_SIMOS8_D4
 SG_ GE_Tachometer_Damping : 58|1@1+ (1.0,0.0) [0.0|1] ""  Motor_EDC17_D4,Motor_ME17_BY,Motor_MED17_SIMOS8_D4
 SG_ GE_OverrunCut_Unt : 59|1@1+ (1.0,0.0) [0.0|1] ""  Motor_EDC17_D4,Motor_ME17_BY,Motor_MED17_SIMOS8_D4
 SG_ GE_Enable_Synchro : 60|1@1+ (1.0,0.0) [0.0|1] ""  Motor_EDC17_D4,Motor_ME17_BY,Motor_MED17_SIMOS8_D4
 SG_ GE_HYB_RPM_Intervention : 61|2@1+ (1.0,0.0) [0.0|3] ""  Vector__XXX

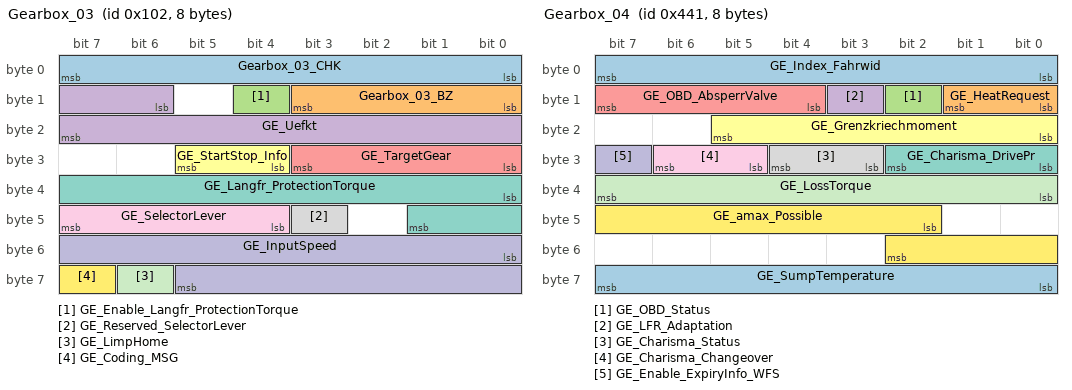
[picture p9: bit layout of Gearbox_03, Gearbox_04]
BO_ 258 Gearbox_03: 8 Getriebe_AL551_951_D4_C7
 SG_ Gearbox_03_CHK : 0|8@1+ (1,0) [0|255] ""  EPB_D4,Gateway_D4C7,Motor_EDC17_D4,Motor_ME17_BY,Motor_MED17_SIMOS8_D4
 SG_ Gearbox_03_BZ : 8|4@1+ (1,0) [0|15] ""  EPB_D4,Gateway_D4C7,Motor_EDC17_D4,Motor_ME17_BY,Motor_MED17_SIMOS8_D4
 SG_ GE_Enable_Langfr_ProtectionTorque : 12|1@1+ (1.0,0.0) [0.0|1] ""  Gateway_D4C7,Motor_EDC17_D4,Motor_ME17_BY,Motor_MED17_SIMOS8_D4
 SG_ GE_Uefkt : 14|10@1+ (0.1,0) [0.0|102.2] ""  EPB_D4,Gateway_D4C7,Motor_EDC17_D4,Motor_ME17_BY,Motor_MED17_SIMOS8_D4
 SG_ GE_TargetGear : 24|4@1+ (1.0,0.0) [0.0|15] ""  Gateway_D4C7,Motor_EDC17_D4,Motor_ME17_BY,Motor_MED17_SIMOS8_D4
 SG_ GE_StartStop_Info : 28|2@1+ (1.0,0.0) [0.0|3] ""  Gateway_D4C7,Motor_EDC17_D4,Motor_ME17_BY,Motor_MED17_SIMOS8_D4
 SG_ GE_Langfr_ProtectionTorque : 32|10@1+ (1,0) [0|1021] ""  Gateway_D4C7,Motor_EDC17_D4,Motor_ME17_BY,Motor_MED17_SIMOS8_D4
 SG_ GE_Reserved_SelectorLever : 43|1@1+ (1,0) [0|1] ""  Gateway_D4C7
 SG_ GE_SelectorLever : 44|4@1+ (1.0,0.0) [0.0|15] ""  EPB_D4,Gateway_D4C7,Motor_EDC17_D4,Motor_ME17_BY,Motor_MED17_SIMOS8_D4
 SG_ GE_InputSpeed : 48|14@1+ (1,0) [0|16381] "Unit_MinutInver"  Gateway_D4C7,Motor_EDC17_D4,Motor_ME17_BY,Motor_MED17_SIMOS8_D4
 SG_ GE_LimpHome : 62|1@1+ (1.0,0.0) [0.0|1] ""  Gateway_D4C7,Motor_EDC17_D4,Motor_ME17_BY,Motor_MED17_SIMOS8_D4
 SG_ GE_Coding_MSG : 63|1@1+ (1.0,0.0) [0.0|1] ""  Gateway_D4C7

BO_ 1089 Gearbox_04: 8 Getriebe_AL551_951_D4_C7
 SG_ GE_Index_Fahrwid : 0|8@1+ (0.249,-31.623) [-31.623|31.623] ""  Gateway_D4C7,Motor_EDC17_D4,Motor_ME17_BY,Motor_MED17_SIMOS8_D4
 SG_ GE_HeatRequest : 8|2@1+ (1.0,0.0) [0.0|3] ""  Gateway_D4C7,Motor_EDC17_D4,Motor_ME17_BY,Motor_MED17_SIMOS8_D4
 SG_ GE_OBD_Status : 10|1@1+ (1.0,0.0) [0.0|1] ""  Gateway_D4C7,Motor_EDC17_D4,Motor_ME17_BY,Motor_MED17_SIMOS8_D4
 SG_ GE_LFR_Adaptation : 11|1@1+ (1,0) [0|1] ""  Gateway_D4C7,Motor_EDC17_D4,Motor_ME17_BY,Motor_MED17_SIMOS8_D4
 SG_ GE_OBD_AbsperrValve : 12|4@1+ (1.0,0.0) [0.0|15] ""  Gateway_D4C7
 SG_ GE_Grenzkriechmoment : 16|6@1+ (2,0) [0|122] ""  Gateway_D4C7
 SG_ GE_Charisma_DrivePr : 24|3@1+ (1.0,0.0) [0.0|7] ""  Gateway_D4C7
 SG_ GE_Charisma_Status : 27|2@1+ (1.0,0.0) [0.0|3] ""  Gateway_D4C7
 SG_ GE_Charisma_Changeover : 29|2@1+ (1.0,0.0) [0.0|3] ""  Gateway_D4C7
 SG_ GE_Enable_ExpiryInfo_WFS : 31|1@1+ (1.0,0.0) [0.0|1] ""  Gateway_D4C7,Motor_EDC17_D4,Motor_ME17_BY,Motor_MED17_SIMOS8_D4
 SG_ GE_LossTorque : 32|8@1+ (1,0) [0|254] ""  EPB_D4,Gateway_D4C7,Motor_EDC17_D4,Motor_ME17_BY,Motor_MED17_SIMOS8_D4
 SG_ GE_amax_Possible : 42|9@1+ (0.024,-2.016) [-2.016|10.224] "Unit_MeterPerSeconSquar"  Gateway_D4C7,Motor_EDC17_D4,Motor_ME17_BY,Motor_MED17_SIMOS8_D4
 SG_ GE_SumpTemperature : 56|8@1+ (1,-58) [-58|196] "Unit_DegreCelsi"  Gateway_D4C7,Motor_EDC17_D4,Motor_ME17_BY,Motor_MED17_SIMOS8_D4

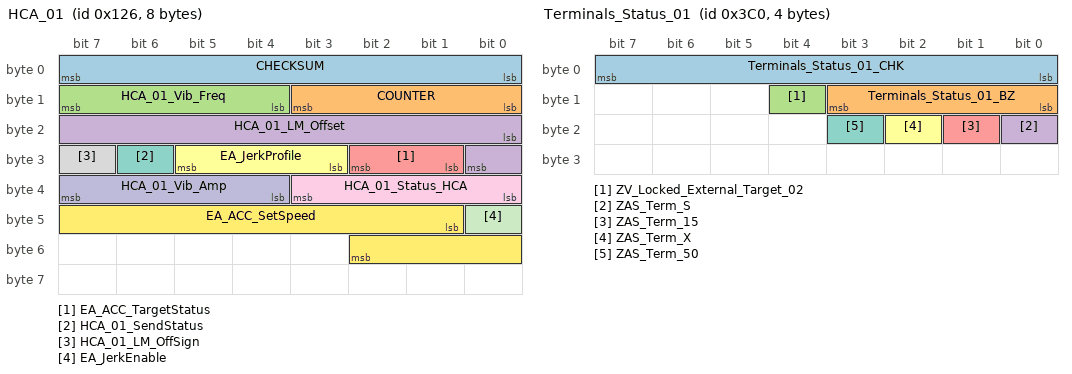
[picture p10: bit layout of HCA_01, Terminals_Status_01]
BO_ 294 HCA_01: 8 Frontsensorik
 SG_ CHECKSUM : 0|8@1+ (1,0) [0|255] "" Vector__XXX
 SG_ COUNTER : 8|4@1+ (1,0) [0|15] "" Vector__XXX
 SG_ HCA_01_Vib_Freq : 12|4@1+ (1,15) [15|30] "Unit_Hertz" Vector__XXX
 SG_ HCA_01_LM_Offset : 16|9@1+ (1,0) [0|511] "Unit_centiNewtoMeter" Vector__XXX
 SG_ EA_ACC_TargetStatus : 25|2@1+ (1,0) [0|3] ""  Frontradar
 SG_ EA_JerkProfile : 27|3@1+ (1,0) [0|7] "" Vector__XXX
 SG_ HCA_01_SendStatus : 30|1@1+ (1,0) [0|1] "" Vector__XXX
 SG_ HCA_01_LM_OffSign : 31|1@1+ (1,0) [0|1] "" Vector__XXX
 SG_ HCA_01_Status_HCA : 32|4@1+ (1,0) [0|15] "" Vector__XXX
 SG_ HCA_01_Vib_Amp : 36|4@1+ (0.2,0) [0|3] "Unit_NewtoMeter" Vector__XXX
 SG_ EA_JerkEnable : 40|1@1+ (1,0) [0|1] "" Vector__XXX
 SG_ EA_ACC_SetSpeed : 41|10@1+ (0.32,0) [0|327.04] "Unit_KiloMeterPerHour"  Frontradar

BO_ 1811 ISO_ABS_Req: 8 Gateway_D4C7
 SG_ ISO_ABS_Req_Data : 0|64@1+ (1.0,0.0) [0.0|18446744073709551615] ""  ESP_D4

BO_ 1917 ISO_ABS_Resp: 8 ESP_D4
 SG_ ISO_ABS_Resp_Data : 0|64@1+ (1.0,0.0) [0.0|18446744073709551615] ""  Gateway_D4C7

BO_ 1813 ISO_Airbag_01_Req: 8 Gateway_D4C7
 SG_ ISO_Airbag_01_Req_Data : 0|64@1+ (1.0,0.0) [0.0|18446744073709551615] ""  Airbag_D4

BO_ 1919 ISO_Airbag_01_Resp: 8 Airbag_D4
 SG_ ISO_Airbag_01_Resp_Data : 0|64@1+ (1.0,0.0) [0.0|18446744073709551615] ""  Gateway_D4C7

BO_ 1874 ISO_EPB_Req: 8 Gateway_D4C7
 SG_ ISO_EPB_Req_Data : 0|64@1+ (1.0,0.0) [0.0|18446744073709551615] ""  EPB_D4

BO_ 1980 ISO_EPB_Resp: 8 EPB_D4
 SG_ ISO_EPB_Resp_Data : 0|64@1+ (1.0,0.0) [0.0|18446744073709551615] ""  Gateway_D4C7

BO_ 1795 ISO_Functional_Req_Aggregate: 8 Gateway_D4C7
 SG_ ISO_Functionaler_Req_Aggregate : 0|64@1+ (1.0,0.0) [0.0|18446744073709551615] ""  Getriebe_AL551_951_D4_C7,Getriebe_DL501_C7,Getriebe_VL381_C7,Motor_EDC17_D4,Motor_ME17_BY,Motor_MED17_SIMOS8_D4,Motor_Slave_D4,SCR_C7

BO_ 1792 ISO_Functional_Req_All: 8 Gateway_D4C7
 SG_ ISO_ALL_01_Req_Data : 0|64@1+ (1.0,0.0) [0.0|18446744073709551615] ""  Airbag_D4,EPB_D4,ESP_D4,Getriebe_AL551_951_D4_C7,Getriebe_DL501_C7,Getriebe_VL381_C7,Motor_EDC17_D4,Motor_ME17_BY,Motor_MED17_SIMOS8_D4,Motor_Slave_D4,SAK_C7,SCR_C7

BO_ 2015 ISO_Functional_Req_OBD: 8 Gateway_D4C7
 SG_ ISO_OBD_Functional_Req_Data : 0|64@1+ (1.0,0.0) [0.0|18446744073709551615] ""  Getriebe_AL551_951_D4_C7,Getriebe_DL501_C7,Getriebe_VL381_C7,Motor_EDC17_D4,Motor_ME17_BY,Motor_MED17_SIMOS8_D4,Motor_Slave_D4,SCR_C7

BO_ 2017 ISO_Gearbox_01_Req: 8 Gateway_D4C7
 SG_ ISO_Gearbox_01_Req_Data : 0|64@1+ (1.0,0.0) [0.0|18446744073709551615] ""  Getriebe_AL551_951_D4_C7,Getriebe_DL501_C7,Getriebe_VL381_C7

BO_ 2025 ISO_Gearbox_01_Resp: 8 Getriebe_AL551_951_D4_C7
 SG_ ISO_Gearbox_01_Resp_Data : 0|64@1+ (1.0,0.0) [0.0|18446744073709551615] ""  Gateway_D4C7

BO_ 2016 ISO_MO_01_Req: 8 Gateway_D4C7
 SG_ ISO_MO_01_Req_Data : 0|64@1+ (1.0,0.0) [0.0|18446744073709551615] ""  Motor_EDC17_D4,Motor_ME17_BY,Motor_MED17_SIMOS8_D4

BO_ 2024 ISO_MO_01_Resp: 8 Motor_EDC17_D4
 SG_ ISO_MO_01_Resp_Data : 0|64@1+ (1.0,0.0) [0.0|18446744073709551615] ""  Gateway_D4C7

BO_ 2018 ISO_MOS_01_Req: 8 Gateway_D4C7
 SG_ ISO_MOS_01_Req_Data : 0|64@1+ (1.0,0.0) [0.0|18446744073709551615] ""  Motor_Slave_D4

BO_ 2026 ISO_MOS_01_Resp: 8 Motor_Slave_D4
 SG_ ISO_MOS_01_Resp_Data : 0|64@1+ (1.0,0.0) [0.0|18446744073709551615] ""  Gateway_D4C7

BO_ 2019 ISO_OBD_Reserved5_Req: 8 Gateway_D4C7
 SG_ ISO_OBD_Reserved5_Req_Data : 0|64@1+ (1.0,0.0) [0.0|18446744073709551615] ""  Vector__XXX

BO_ 2027 ISO_OBD_Reserved5_Resp: 8 Vector__XXX
 SG_ ISO_OBD_Reserved5_Resp_Data : 0|64@1+ (1.0,0.0) [0.0|18446744073709551615] ""  Gateway_D4C7

BO_ 1834 ISO_SCR_Req: 8 Gateway_D4C7
 SG_ ISO_SCR_Req_Data : 0|64@1+ (1.0,0.0) [0.0|18446744073709551615] ""  SCR_C7

BO_ 1940 ISO_SCR_Resp: 8 SCR_C7
 SG_ ISO_SCR_Resp_Data : 0|64@1+ (1.0,0.0) [0.0|18446744073709551615] ""  Gateway_D4C7

BO_ 1814 ISO_SCU_Req: 8 Gateway_D4C7
 SG_ ISO_SCU_Req_Data : 0|64@1+ (1.0,0.0) [0.0|18446744073709551615] ""  Vector__XXX

BO_ 1920 ISO_SCU_Resp: 8 Vector__XXX
 SG_ ISO_SCU_Resp_Data : 0|64@1+ (1.0,0.0) [0.0|18446744073709551615] ""  Gateway_D4C7

BO_ 1820 ISO_SoundActuator_Req: 8 Gateway_D4C7
 SG_ ISO_SoundActuator_Req_Data : 0|64@1+ (1.0,0.0) [0.0|18446744073709551615] ""  SAK_C7

BO_ 1926 ISO_SoundActuator_Resp: 8 SAK_C7
 SG_ ISO_SoundActuator_Resp_Data : 0|64@1+ (1.0,0.0) [0.0|18446744073709551615] ""  Gateway_D4C7

BO_ 1875 ISO_SelectorLever_Req: 8 Gateway_D4C7
 SG_ ISO_SelectorLever_Req_Data : 0|64@1+ (1.0,0.0) [0.0|18446744073709551615] ""  Getriebe_AL551_951_D4_C7

BO_ 1981 ISO_SelectorLever_Resp: 8 Getriebe_AL551_951_D4_C7
 SG_ ISO_SelectorLever_Resp_Data : 0|64@1+ (1.0,0.0) [0.0|18446744073709551615] ""  Gateway_D4C7

BO_ 1424 Kessy_02: 8 Gateway_D4C7
 SG_ KY_Funkschl_Nr : 0|4@1+ (1.0,0.0) [0.0|15] ""  Vector__XXX
 SG_ KY_ID_Geb_Authorised : 4|1@1+ (1.0,0.0) [0.0|1] ""  Vector__XXX
 SG_ KY_ID_Geb_Inserted : 5|1@1+ (1.0,0.0) [0.0|1] ""  Vector__XXX
 SG_ KY_FFB_Frequency : 6|2@1+ (1.0,0.0) [0.0|3] ""  Vector__XXX
 SG_ KY_HF_Active : 8|1@1+ (1.0,0.0) [0.0|1] ""  Vector__XXX
 SG_ KY_LF_Active : 9|1@1+ (1.0,0.0) [0.0|1] ""  Vector__XXX
 SG_ KY_ELV_Lock : 10|1@1+ (1.0,0.0) [0.0|1] ""  EPB_D4
 SG_ KY_ELV_entr : 11|1@1+ (1.0,0.0) [0.0|1] ""  Vector__XXX
 SG_ KY_ELV_enable_Request : 12|1@1+ (1.0,0.0) [0.0|1] ""  Vector__XXX
 SG_ KY_Valet_Parking : 14|1@1+ (1.0,0.0) [0.0|1] ""  Vector__XXX
 SG_ KY_Keyless_Fitment : 15|1@1+ (1.0,0.0) [0.0|1] ""  Vector__XXX
 SG_ KY_FBS_Driver_Notices : 16|3@1+ (1.0,0.0) [0.0|7] ""  Vector__XXX
 SG_ FBS_Warn_Steering_def : 19|1@1+ (1.0,0.0) [0.0|1] ""  Vector__XXX
 SG_ FBS_Warn_SteerLocking_def : 20|1@1+ (1.0,0.0) [0.0|1] ""  Vector__XXX
 SG_ FBS_Warn_Key_Batt : 21|1@1+ (1.0,0.0) [0.0|1] ""  Vector__XXX
 SG_ FBS_Prio_Warn_04 : 22|1@1+ (1.0,0.0) [0.0|1] ""  Vector__XXX
 SG_ FBS_Prio_Warn_05 : 23|1@1+ (1.0,0.0) [0.0|1] ""  Vector__XXX
 SG_ KY_KYL_Driver_Notices : 24|3@1+ (1.0,0.0) [0.0|7] ""  Vector__XXX
 SG_ KYL_Warn_No_Key : 27|1@1+ (1.0,0.0) [0.0|1] ""  Vector__XXX
 SG_ KYL_Warn_Kessy_Defective : 28|1@1+ (1.0,0.0) [0.0|1] ""  Vector__XXX
 SG_ KY_KYL_Prio_Warn_03 : 29|1@1+ (1.0,0.0) [0.0|1] ""  Vector__XXX
 SG_ KY_KYL_Prio_Warn_04 : 30|1@1+ (1.0,0.0) [0.0|1] ""  Vector__XXX
 SG_ KY_KYL_Prio_Warn_05 : 31|1@1+ (1.0,0.0) [0.0|1] ""  Vector__XXX
 SG_ KY_Key_Target : 32|4@1+ (1.0,0.0) [0.0|15] ""  Vector__XXX
 SG_ KY_Key_Actual : 36|4@1+ (1.0,0.0) [0.0|15] ""  Vector__XXX
 SG_ KY_WFS_Safe : 40|1@1+ (1.0,0.0) [0.0|1] ""  Vector__XXX
 SG_ KY_WFS_LZ : 41|2@1+ (1.0,0.0) [0.0|3] ""  Vector__XXX
 SG_ KY_StartStop_Info : 43|2@1+ (1.0,0.0) [0.0|3] ""  Motor_EDC17_D4,Motor_ME17_BY,Motor_MED17_SIMOS8_D4
 SG_ KYL_Notzuendschloss : 45|1@1+ (1.0,0.0) [0.0|1] ""  Vector__XXX
 SG_ KYL_Warn_Notzuendschloss : 46|1@1+ (1.0,0.0) [0.0|1] ""  Vector__XXX
 SG_ FBS_KD_Error : 47|1@1+ (1.0,0.0) [0.0|1] ""  Vector__XXX

BO_ 960 Terminals_Status_01: 4 Gateway_D4C7
 SG_ Terminals_Status_01_CHK : 0|8@1+ (1,0) [0|255] ""  EPB_D4,Getriebe_AL551_951_D4_C7,Motor_EDC17_D4,Motor_ME17_BY,Motor_MED17_SIMOS8_D4
 SG_ Terminals_Status_01_BZ : 8|4@1+ (1,0) [0|15] ""  EPB_D4,Getriebe_AL551_951_D4_C7,Motor_EDC17_D4,Motor_ME17_BY,Motor_MED17_SIMOS8_D4
 SG_ ZV_Locked_External_Target_02 : 12|1@1+ (1.0,0.0) [0.0|1] ""  Getriebe_AL551_951_D4_C7
 SG_ ZAS_Term_S : 16|1@1+ (1.0,0.0) [0.0|1] ""  EPB_D4,Getriebe_AL551_951_D4_C7
 SG_ ZAS_Term_15 : 17|1@1+ (1.0,0.0) [0.0|1] ""  EPB_D4,Getriebe_AL551_951_D4_C7,Getriebe_DL501_C7,Motor_EDC17_D4,Motor_ME17_BY,Motor_MED17_SIMOS8_D4,SCU_D4
 SG_ ZAS_Term_X : 18|1@1+ (1.0,0.0) [0.0|1] ""  EPB_D4,SCU_D4
 SG_ ZAS_Term_50 : 19|1@1+ (1.0,0.0) [0.0|1] ""  EPB_D4,Motor_EDC17_D4,Motor_ME17_BY,Motor_MED17_SIMOS8_D4

BO_ 959 Climate_01: 8 Gateway_D4C7
 SG_ TERM_Rpm_Trailer : 0|1@1+ (1.0,0.0) [0.0|1] ""  Motor_EDC17_D4,Motor_ME17_BY,Motor_MED17_SIMOS8_D4
 SG_ TERM_PreWarn_Compressor_On : 1|1@1+ (1.0,0.0) [0.0|1] ""  Motor_EDC17_D4,Motor_ME17_BY,Motor_MED17_SIMOS8_D4
 SG_ TERM_Handshake_BEM : 2|1@1+ (1.0,0.0) [0.0|1] ""  Vector__XXX
 SG_ TERM_Compressor_Torque_Old : 3|1@1+ (1.0,0.0) [0.0|1] ""  Vector__XXX
 SG_ TERM_PreWarn_HHS_On : 4|1@1+ (1.0,0.0) [0.0|1] ""  Motor_EDC17_D4,Motor_ME17_BY,Motor_MED17_SIMOS8_D4
 SG_ TERM_PreWarn_HFS_On : 5|1@1+ (1.0,0.0) [0.0|1] ""  Motor_EDC17_D4,Motor_ME17_BY,Motor_MED17_SIMOS8_D4
 SG_ TERM_PreWarn_AuxHeater_On : 6|1@1+ (1.0,0.0) [0.0|1] ""  Vector__XXX
 SG_ TERM_KD_Error : 7|1@1+ (1.0,0.0) [0.0|1] ""  Vector__XXX
 SG_ TERM_Comp_rev_rq : 8|8@1+ (50,0) [0|8600] "Unit_MinutInver"  Vector__XXX
 SG_ TERM_Charisma_DrivePr : 16|3@1+ (1.0,0.0) [0.0|7] ""  Vector__XXX
 SG_ TERM_Charisma_Status : 19|2@1+ (1.0,0.0) [0.0|3] ""  Vector__XXX
 SG_ TERM_Charisma_Changeover : 21|2@1+ (1.0,0.0) [0.0|3] ""  Vector__XXX
 SG_ TERM_Load_Compressor : 24|8@1+ (0.25,0) [0.00|63.50] "Unit_NewtoMeter"  Motor_EDC17_D4,Motor_ME17_BY,Motor_MED17_SIMOS8_D4
 SG_ TERM_Power_Hzg_Target : 32|8@1+ (11,0) [0|2805] "Unit_Watt"  Vector__XXX
 SG_ TERM_Req_TERM : 40|8@1+ (0.4,0) [0.0|101.6] "Unit_PerCent"  Motor_EDC17_D4,Motor_ME17_BY,Motor_MED17_SIMOS8_D4
 SG_ TERM_4_Zones : 48|1@1+ (1.0,0.0) [0.0|1] ""  Motor_EDC17_D4,Motor_ME17_BY,Motor_MED17_SIMOS8_D4
 SG_ TERM_AC_Switch : 49|1@1+ (1.0,0.0) [0.0|1] ""  Getriebe_AL551_951_D4_C7
 SG_ TERM_State : 50|1@1+ (1.0,0.0) [0.0|1] ""  Getriebe_AL551_951_D4_C7,Motor_EDC17_D4,Motor_ME17_BY,Motor_MED17_SIMOS8_D4
 SG_ TERM_ThermalManagement : 51|2@1+ (1.0,0.0) [0.0|3] ""  Motor_EDC17_D4,Motor_ME17_BY,Motor_MED17_SIMOS8_D4
 SG_ TERM_Comp_enable : 53|1@1+ (1.0,0.0) [0.0|1] ""  Vector__XXX
 SG_ TERM_StartStop_Info : 54|2@1+ (1.0,0.0) [0.0|3] ""  Motor_EDC17_D4,Motor_ME17_BY,Motor_MED17_SIMOS8_D4
 SG_ TERM_el_AuxHeater_Stage : 56|3@1+ (1.0,0.0) [0.0|7] ""  Motor_EDC17_D4
 SG_ TERM_Diag_Absperrvent : 59|4@1+ (1.0,0.0) [0.0|15] ""  Vector__XXX

BO_ 779 Cluster_01: 8 Gateway_D4C7
 SG_ KBI_ABS_Lamp : 0|1@1+ (1.0,0.0) [0.0|1] ""  Getriebe_AL551_951_D4_C7
 SG_ KBI_ESP_Lamp : 1|1@1+ (1.0,0.0) [0.0|1] ""  Getriebe_AL551_951_D4_C7
 SG_ KBI_BKL_Lamp : 2|1@1+ (1.0,0.0) [0.0|1] ""  Getriebe_AL551_951_D4_C7
 SG_ KBI_Airbag_Lamp : 3|1@1+ (1.0,0.0) [0.0|1] ""  Getriebe_AL551_951_D4_C7
 SG_ KBI_SILA_Valid : 4|1@1+ (1.0,0.0) [0.0|1] ""  Getriebe_AL551_951_D4_C7
 SG_ KBI_Steering_Lamp : 5|1@1+ (1,0) [0|1] ""  Getriebe_AL551_951_D4_C7
 SG_ KBI_Preheat_System_Lamp : 6|1@1+ (1.0,0.0) [0.0|1] ""  Getriebe_AL551_951_D4_C7,Motor_EDC17_D4
 SG_ KBI_NV_in_Display : 7|1@1+ (1.0,0.0) [0.0|1] ""  Getriebe_AL551_951_D4_C7
 SG_ XCOUNTER : 8|4@1+ (1,0) [0|15] ""  Getriebe_AL551_951_D4_C7
 SG_ KBI_DisplayStatus_ACC : 12|1@1+ (1.0,0.0) [0.0|1] ""  Getriebe_AL551_951_D4_C7
 SG_ KBI_OilPressure_Switch : 15|1@1+ (1.0,0.0) [0.0|1] ""  Getriebe_AL551_951_D4_C7
 SG_ KBI_LowFuelWarning : 16|1@1+ (1.0,0.0) [0.0|1] ""  Getriebe_AL551_951_D4_C7,Motor_EDC17_D4,Motor_ME17_BY,Motor_MED17_SIMOS8_D4
 SG_ KBI_MFA_v_Unit_01 : 17|1@1+ (1.0,0.0) [0.0|1] ""  Getriebe_AL551_951_D4_C7,Motor_EDC17_D4,Motor_ME17_BY,Motor_MED17_SIMOS8_D4
 SG_ KBI_In_ActuatorTest : 18|1@1+ (1.0,0.0) [0.0|1] ""  Getriebe_AL551_951_D4_C7
 SG_ KBI_DisplayFault_LDW : 19|2@1+ (1.0,0.0) [0.0|3] ""  Getriebe_AL551_951_D4_C7
 SG_ KBI_Variant_USA : 21|1@1+ (1.0,0.0) [0.0|1] ""  Getriebe_AL551_951_D4_C7
 SG_ KBI_OilPressureWarning : 22|1@1+ (1.0,0.0) [0.0|1] ""  Getriebe_AL551_951_D4_C7
 SG_ KBI_Handbrake : 23|1@1+ (1.0,0.0) [0.0|1] ""  Getriebe_AL551_951_D4_C7
 SG_ KBI_V_Digital : 24|9@1+ (1,0) [0|511] ""  Getriebe_AL551_951_D4_C7
 SG_ KBI_PLA_in_Display : 33|1@1+ (1.0,0.0) [0.0|1] ""  Getriebe_AL551_951_D4_C7
 SG_ KBI_DisplayFault_NV : 34|1@1+ (1.0,0.0) [0.0|1] ""  Getriebe_AL551_951_D4_C7
 SG_ KBI_Displayed_Speed : 48|10@1+ (0.32,0) [0.00|325.12] "Unit_KiloMeterPerHour"  Getriebe_AL551_951_D4_C7,Getriebe_DL501_C7,Getriebe_VL381_C7,Motor_EDC17_D4,Motor_ME17_BY,Motor_MED17_SIMOS8_D4
 SG_ KBI_Unit_Speedo : 58|1@1+ (1.0,0.0) [0.0|1] ""  Getriebe_AL551_951_D4_C7,Motor_EDC17_D4,Motor_ME17_BY,Motor_MED17_SIMOS8_D4
 SG_ KBI_Consistency_ACC : 59|1@1+ (1.0,0.0) [0.0|1] ""  Getriebe_AL551_951_D4_C7
 SG_ KBI_Error_Display_ACC : 60|1@1+ (1.0,0.0) [0.0|1] ""  Getriebe_AL551_951_D4_C7
 SG_ KBI_DisplayFault_SWA : 61|2@1+ (1.0,0.0) [0.0|3] ""  Getriebe_AL551_951_D4_C7
 SG_ KBI_KD_Error : 63|1@1+ (1.0,0.0) [0.0|1] ""  Getriebe_AL551_951_D4_C7

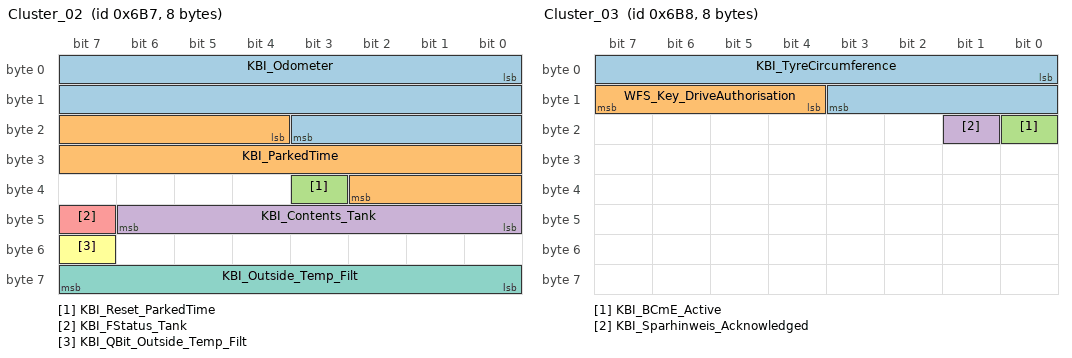
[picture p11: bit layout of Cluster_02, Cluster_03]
BO_ 1719 Cluster_02: 8 Gateway_D4C7
 SG_ KBI_Odometer : 0|20@1+ (1,0) [0|1048573] "Unit_KiloMeter"  Vector__XXX
 SG_ KBI_ParkedTime : 20|15@1+ (4,0) [0|131068] "Unit_Secon"  Getriebe_AL551_951_D4_C7,Getriebe_DL501_C7,Getriebe_VL381_C7,Motor_EDC17_D4,Motor_ME17_BY,Motor_MED17_SIMOS8_D4
 SG_ KBI_Reset_ParkedTime : 35|1@1+ (1.0,0.0) [0.0|1] ""  Getriebe_AL551_951_D4_C7,Getriebe_DL501_C7,Getriebe_VL381_C7,Motor_EDC17_D4,Motor_ME17_BY,Motor_MED17_SIMOS8_D4
 SG_ KBI_Contents_Tank : 40|7@1+ (1,0) [0|126] "Unit_Liter"  Motor_EDC17_D4,Motor_ME17_BY,Motor_MED17_SIMOS8_D4
 SG_ KBI_FStatus_Tank : 47|1@1+ (1.0,0.0) [0.0|1] ""  Motor_EDC17_D4,Motor_ME17_BY,Motor_MED17_SIMOS8_D4
 SG_ KBI_QBit_Outside_Temp_Filt : 55|1@1+ (1.0,0.0) [0.0|1] ""  EPB_D4,Getriebe_AL551_951_D4_C7,Getriebe_DL501_C7,Getriebe_VL381_C7,Motor_EDC17_D4,Motor_ME17_BY,Motor_MED17_SIMOS8_D4,SCR_C7
 SG_ KBI_Outside_Temp_Filt : 56|8@1+ (0.5,-50) [-50.0|75.0] "Unit_DegreCelsi"  EPB_D4,Getriebe_AL551_951_D4_C7,Getriebe_DL501_C7,Getriebe_VL381_C7,Motor_EDC17_D4,Motor_ME17_BY,Motor_MED17_SIMOS8_D4,SCR_C7

BO_ 1720 Cluster_03: 8 Gateway_D4C7
 SG_ KBI_TyreCircumference : 0|12@1+ (1,0) [0|4095] "Unit_MilliMeter"  Getriebe_AL551_951_D4_C7,Getriebe_DL501_C7,Getriebe_VL381_C7
 SG_ WFS_Key_DriveAuthorisation : 12|4@1+ (1.0,0.0) [0.0|15] ""  Vector__XXX
 SG_ KBI_BCmE_Active : 16|1@1+ (1.0,0.0) [0.0|1] ""  Vector__XXX
 SG_ KBI_Sparhinweis_Acknowledged : 17|1@1+ (1.0,0.0) [0.0|1] ""  Vector__XXX

BO_ 517 KS_Airbag: 8 Airbag_D4
 SG_ KS_Airbag_Data : 0|64@1+ (1.0,0.0) [0.0|18446744073709551615] ""  Gateway_D4C7

BO_ 640 KS_Master: 8 Gateway_D4C7
 SG_ KS_Master_Data : 0|64@1+ (1.0,0.0) [0.0|18446744073709551615] ""  Airbag_D4

BO_ 919 LDW_02: 8 Gateway_D4C7
 SG_ LDW_Chime : 12|2@1+ (1.0,0.0) [0.0|3] ""  Kombi_D4
 SG_ LDW_SW_Warning_Left : 14|1@1+ (1.0,0.0) [0.0|1] ""  Vector__XXX
 SG_ LDW_SW_Warning_Right : 15|1@1+ (1.0,0.0) [0.0|1] ""  Vector__XXX
 SG_ LDW_Texte : 16|4@1+ (1.0,0.0) [0.0|15] ""  Kombi_D4
 SG_ LDW_Side_DLCTLC : 20|1@1+ (1.0,0.0) [0.0|1] ""  Vector__XXX
 SG_ LDW_LearnMode : 21|3@1+ (1.0,0.0) [0.0|7] ""  HUD_C7
 SG_ LDW_Anlaufsp_VLR : 24|4@1+ (1,0) [0|15] ""  SMLS_D4
 SG_ LDW_Vib_Amp_VLR : 28|4@1+ (1,0) [0|15] ""  SMLS_D4
 SG_ LDW_StartUpTime_VLR : 32|4@1+ (1,0) [0|15] ""  SMLS_D4
 SG_ LDW_LearnMode_Right : 36|2@1+ (1,0) [0|3] ""  XXX
 SG_ LDW_LearnMode_Left : 38|2@1+ (1,0) [0|3] ""  XXX
 SG_ LDW_DLC : 40|8@1+ (0.01,-1.25) [-1.25|1.25] "Unit_Meter"  Vector__XXX
 SG_ LDW_TLC : 48|5@1+ (0.1,0) [0.0|3.0] "Unit_Secon"  Vector__XXX
 SG_ LDW_Warning_Left : 56|1@1+ (1.0,0.0) [0.0|1] ""  SMLS_D4
 SG_ LDW_Warning_Right : 57|1@1+ (1.0,0.0) [0.0|1] ""  SMLS_D4
 SG_ LDW_CodingInfo_For_VLR : 58|2@1+ (1.0,0.0) [0.0|3] ""  SMLS_D4
 SG_ LDW_WindscreenHeating_Active : 60|1@1+ (1.0,0.0) [0.0|1] ""  Klima_D4_C7,SMLS_D4
 SG_ LDW_Status_LED_Yellow : 61|1@1+ (1.0,0.0) [0.0|1] ""  APS_D4,Kombi_D4
 SG_ LDW_Status_LED_Green : 62|1@1+ (1.0,0.0) [0.0|1] ""  APS_D4,Kombi_D4
 SG_ LDW_KD_Error : 63|1@1+ (1.0,0.0) [0.0|1] ""  Vector__XXX

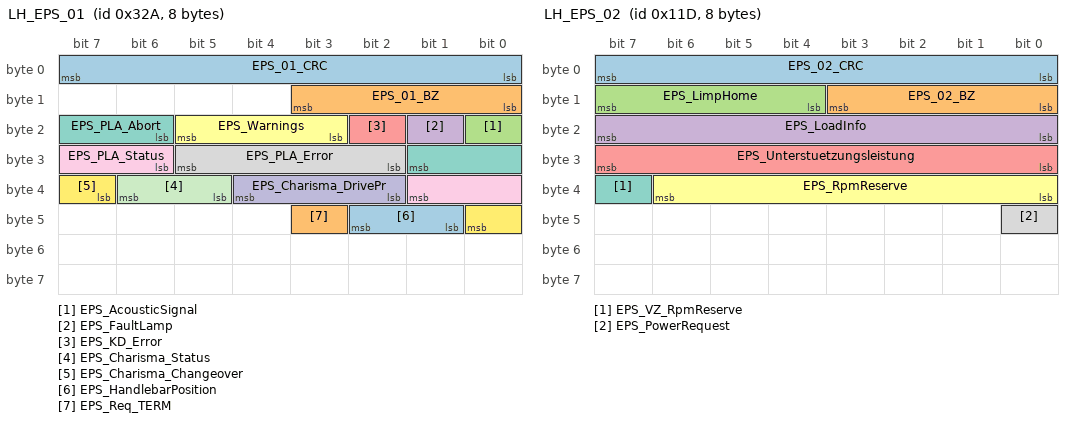
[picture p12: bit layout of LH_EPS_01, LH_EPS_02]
BO_ 810 LH_EPS_01: 8 Gateway_D4C7
 SG_ EPS_01_CRC : 0|8@1+ (1,0) [0|255] ""  APS_D4
 SG_ EPS_01_BZ : 8|4@1+ (1,0) [0|15] ""  APS_D4
 SG_ EPS_AcousticSignal : 16|1@1+ (1.0,0.0) [0.0|1] ""  Kombi_D4
 SG_ EPS_FaultLamp : 17|1@1+ (1.0,0.0) [0.0|1] ""  Vector__XXX
 SG_ EPS_KD_Error : 18|1@1+ (1.0,0.0) [0.0|1] ""  Vector__XXX
 SG_ EPS_Warnings : 19|3@1+ (1.0,0.0) [0.0|7] ""  Kombi_D4
 SG_ EPS_PLA_Abort : 22|4@1+ (1,0) [0|15] ""  APS_D4
 SG_ EPS_PLA_Error : 26|4@1+ (1,0) [0|15] ""  APS_D4
 SG_ EPS_PLA_Status : 30|4@1+ (1,0) [0|15] ""  APS_D4
 SG_ EPS_Charisma_DrivePr : 34|3@1+ (1.0,0.0) [0.0|7] ""  Vector__XXX
 SG_ EPS_Charisma_Status : 37|2@1+ (1.0,0.0) [0.0|3] ""  Vector__XXX
 SG_ EPS_Charisma_Changeover : 39|2@1+ (1.0,0.0) [0.0|3] ""  Vector__XXX
 SG_ EPS_HandlebarPosition : 41|2@1+ (1.0,0.0) [0.0|3] ""  Vector__XXX
 SG_ EPS_Req_TERM : 43|1@1+ (1.0,0.0) [0.0|1] ""  Vector__XXX

BO_ 285 LH_EPS_02: 8 Gateway_D4C7
 SG_ EPS_02_CRC : 0|8@1+ (1,0) [0|255] ""  SCU_D4
 SG_ EPS_02_BZ : 8|4@1+ (1,0) [0|15] ""  SCU_D4
 SG_ EPS_LimpHome : 12|4@1+ (1.0,0.0) [0.0|15] ""  Vector__XXX
 SG_ EPS_LoadInfo : 16|8@1+ (1,0) [0|253] "Unit_Amper"  Vector__XXX
 SG_ EPS_Unterstuetzungsleistung : 24|8@1+ (0.5,0) [0.0|100.0] "Unit_PerCent"  SCU_D4
 SG_ EPS_RpmReserve : 32|7@1+ (10,0) [0|1000] "Unit_DegreOfArcPerSecon"  SCU_D4
 SG_ EPS_VZ_RpmReserve : 39|1@1+ (1.0,0.0) [0.0|1] ""  SCU_D4
 SG_ EPS_PowerRequest : 40|1@1+ (1.0,0.0) [0.0|1] ""  Vector__XXX

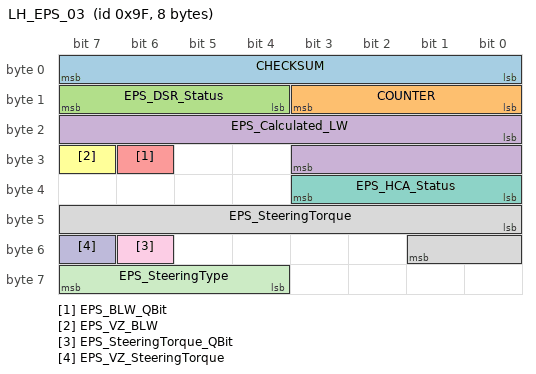
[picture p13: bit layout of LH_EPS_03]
BO_ 159 LH_EPS_03: 8 XXX
 SG_ CHECKSUM : 0|8@1+ (1,0) [0|255] ""  XXX
 SG_ COUNTER : 8|4@1+ (1,0) [0|15] ""  XXX
 SG_ EPS_DSR_Status : 12|4@1+ (1,0) [0|15] ""  XXX
 SG_ EPS_Calculated_LW : 16|12@1+ (0.15,0) [0|613.95] "Unit_DegreOfArc"  XXX
 SG_ EPS_BLW_QBit : 30|1@1+ (1,0) [0|1] ""  XXX
 SG_ EPS_VZ_BLW : 31|1@1+ (1,0) [0|1] ""  XXX
 SG_ EPS_HCA_Status : 32|4@1+ (1,0) [0|15] ""  XXX
 SG_ EPS_SteeringTorque : 40|10@1+ (1,0) [0|8] "Unit_centiNewtoMeter"  XXX
 SG_ EPS_SteeringTorque_QBit : 54|1@1+ (1,0) [0|1] ""  XXX
 SG_ EPS_VZ_SteeringTorque : 55|1@1+ (1,0) [0|1] ""  XXX
 SG_ EPS_SteeringType : 60|4@1+ (1,0) [0|15] ""  XXX

BO_ 1137 Light_Rear_01: 8 Gateway_D4C7
 SG_ Light_Rear_01_BZ : 0|4@1+ (1,0) [0|15] ""  Motor_EDC17_D4,Motor_ME17_BY,Motor_MED17_SIMOS8_D4
 SG_ BCM2_BrakeLight_By_ECD : 5|1@1+ (1.0,0.0) [0.0|1] ""  Motor_EDC17_D4,Motor_ME17_BY,Motor_MED17_SIMOS8_D4
 SG_ LH_OutsideLight_def : 7|1@1+ (1.0,0.0) [0.0|1] ""  Vector__XXX
 SG_ LH_SideLight_H_Active : 8|1@1+ (1.0,0.0) [0.0|1] ""  Vector__XXX
 SG_ LH_ParkingLight_HL_Active : 9|1@1+ (1.0,0.0) [0.0|1] ""  Vector__XXX
 SG_ LH_ParkingLight_HR_Active : 10|1@1+ (1.0,0.0) [0.0|1] ""  Vector__XXX
 SG_ LH_BrakeLight_H_Active : 11|1@1+ (1.0,0.0) [0.0|1] ""  Vector__XXX
 SG_ LH_RearFog_Active : 12|1@1+ (1.0,0.0) [0.0|1] ""  Vector__XXX
 SG_ LH_ReversingLight_Active : 13|1@1+ (1.0,0.0) [0.0|1] ""  Vector__XXX
 SG_ LH_Indicator_HL_Act : 14|1@1+ (1.0,0.0) [0.0|1] ""  Vector__XXX
 SG_ LH_Indicator_HR_Act : 15|1@1+ (1.0,0.0) [0.0|1] ""  Vector__XXX
 SG_ LH_Indicator_Left_def : 16|1@1+ (1.0,0.0) [0.0|1] ""  Vector__XXX
 SG_ LH_BrakeLight_Left_def : 17|1@1+ (1.0,0.0) [0.0|1] ""  Vector__XXX
 SG_ LH_TailLight_Left_def : 18|1@1+ (1.0,0.0) [0.0|1] ""  Vector__XXX
 SG_ LH_Reverse_Left_def : 19|1@1+ (1.0,0.0) [0.0|1] ""  Vector__XXX
 SG_ LH_Fog_Left_def : 20|1@1+ (1.0,0.0) [0.0|1] ""  Vector__XXX
 SG_ LH_End_Brake_Fog_Left_def : 21|1@1+ (1.0,0.0) [0.0|1] ""  Vector__XXX
 SG_ LH_End_Brake_Fog_Right_def : 22|1@1+ (1.0,0.0) [0.0|1] ""  Vector__XXX
 SG_ LH_End_Brake_Left_def : 24|1@1+ (1.0,0.0) [0.0|1] ""  Vector__XXX
 SG_ LH_End_Fog_Left_def : 25|1@1+ (1.0,0.0) [0.0|1] ""  Vector__XXX
 SG_ LH_SL_BRL_BLK_Left_def : 26|1@1+ (1.0,0.0) [0.0|1] ""  Vector__XXX
 SG_ LH_Brake_Blk_Left_def : 27|1@1+ (1.0,0.0) [0.0|1] ""  Vector__XXX
 SG_ LH_Indicator_Right_def : 32|1@1+ (1.0,0.0) [0.0|1] ""  Vector__XXX
 SG_ LH_BrakeLight_Right_def : 33|1@1+ (1.0,0.0) [0.0|1] ""  Vector__XXX
 SG_ LH_TailLight_Right_def : 34|1@1+ (1.0,0.0) [0.0|1] ""  Vector__XXX
 SG_ LH_Reverse_Right_def : 35|1@1+ (1.0,0.0) [0.0|1] ""  Vector__XXX
 SG_ LH_Fog_Right_def : 36|1@1+ (1.0,0.0) [0.0|1] ""  Vector__XXX
 SG_ LH_End_Brake_Right_def : 40|1@1+ (1.0,0.0) [0.0|1] ""  Vector__XXX
 SG_ LH_End_Fog_Right_def : 41|1@1+ (1.0,0.0) [0.0|1] ""  Vector__XXX
 SG_ LH_SL_BRL_BLK_Right_def : 42|1@1+ (1.0,0.0) [0.0|1] ""  Vector__XXX
 SG_ LH_Brake_Blk_Right_def : 43|1@1+ (1.0,0.0) [0.0|1] ""  Vector__XXX
 SG_ LH_Kennzl_def : 48|1@1+ (1.0,0.0) [0.0|1] ""  Vector__XXX
 SG_ LH_3_BrakeLight_def : 49|1@1+ (1.0,0.0) [0.0|1] ""  Motor_EDC17_D4,Motor_ME17_BY,Motor_MED17_SIMOS8_D4
 SG_ LH_Fog_mi_def : 50|1@1+ (1.0,0.0) [0.0|1] ""  Vector__XXX
 SG_ LH_Reverse_mi_def : 51|1@1+ (1.0,0.0) [0.0|1] ""  Vector__XXX
 SG_ LH_BrakeLight_Left_Total_def : 54|1@1+ (1.0,0.0) [0.0|1] ""  Motor_EDC17_D4,Motor_ME17_BY,Motor_MED17_SIMOS8_D4
 SG_ LH_BrakeLight_Right_Total_def : 55|1@1+ (1.0,0.0) [0.0|1] ""  Motor_EDC17_D4,Motor_ME17_BY,Motor_MED17_SIMOS8_D4

BO_ 267 LS_01: 4 Gateway_D4C7
 SG_ CHECKSUM : 0|8@1+ (1,0) [0|255] ""  Getriebe_AL551_951_D4_C7,Getriebe_DL501_C7,Getriebe_VL381_C7,Motor_EDC17_D4,Motor_ME17_BY,Motor_MED17_SIMOS8_D4
 SG_ COUNTER : 8|4@1+ (1,0) [0|15] ""  Getriebe_AL551_951_D4_C7,Getriebe_DL501_C7,Getriebe_VL381_C7,Motor_EDC17_D4,Motor_ME17_BY,Motor_MED17_SIMOS8_D4
 SG_ LS_MainSwitch : 12|1@1+ (1.0,0.0) [0.0|1] ""  Motor_EDC17_D4,Motor_ME17_BY,Motor_MED17_SIMOS8_D4
 SG_ LS_Cancel : 13|1@1+ (1.0,0.0) [0.0|1] ""  Motor_EDC17_D4,Motor_ME17_BY,Motor_MED17_SIMOS8_D4
 SG_ LS_Type_MainSwitch : 14|1@1+ (1.0,0.0) [0.0|1] ""  Motor_EDC17_D4,Motor_ME17_BY,Motor_MED17_SIMOS8_D4
 SG_ LS_Limiter : 15|1@1+ (1.0,0.0) [0.0|1] ""  Motor_EDC17_D4,Motor_ME17_BY,Motor_MED17_SIMOS8_D4
 SG_ LS_Tip_Set : 16|1@1+ (1.0,0.0) [0.0|1] ""  Getriebe_DL501_C7,Motor_EDC17_D4,Motor_ME17_BY,Motor_MED17_SIMOS8_D4
 SG_ LS_Tip_High : 17|1@1+ (1.0,0.0) [0.0|1] ""  Getriebe_DL501_C7,Motor_EDC17_D4,Motor_ME17_BY,Motor_MED17_SIMOS8_D4
 SG_ LS_Tip_Down : 18|1@1+ (1.0,0.0) [0.0|1] ""  Getriebe_DL501_C7,Motor_EDC17_D4,Motor_ME17_BY,Motor_MED17_SIMOS8_D4
 SG_ LS_Tip_Resume : 19|1@1+ (1.0,0.0) [0.0|1] ""  Getriebe_DL501_C7,Motor_EDC17_D4,Motor_ME17_BY,Motor_MED17_SIMOS8_D4
 SG_ LS_Adjustment_TimeGap : 20|2@1+ (1.0,0.0) [0.0|3] ""  Vector__XXX
 SG_ MFL_Tip_Down : 22|1@1+ (1.0,0.0) [0.0|1] ""  Getriebe_AL551_951_D4_C7,Getriebe_DL501_C7,Getriebe_VL381_C7
 SG_ MFL_Tip_Up : 23|1@1+ (1.0,0.0) [0.0|1] ""  Getriebe_AL551_951_D4_C7,Getriebe_DL501_C7,Getriebe_VL381_C7
 SG_ LS_Tiptronic_Error : 24|1@1+ (1.0,0.0) [0.0|1] ""  Getriebe_AL551_951_D4_C7,Getriebe_DL501_C7
 SG_ LS_Error : 25|1@1+ (1,0) [0|1] ""  Motor_EDC17_D4,Motor_ME17_BY,Motor_MED17_SIMOS8_D4
 SG_ LS_Coding : 26|3@1+ (1.0,0.0) [0.0|7] ""  Motor_EDC17_D4,Motor_ME17_BY,Motor_MED17_SIMOS8_D4
 SG_ LS_Tip_Stage_2 : 29|1@1+ (1.0,0.0) [0.0|1] ""  Motor_EDC17_D4,Motor_ME17_BY,Motor_MED17_SIMOS8_D4
 SG_ LS_GRA_ACC_2stufig : 30|1@1+ (1.0,0.0) [0.0|1] ""  Motor_EDC17_D4,Motor_ME17_BY,Motor_MED17_SIMOS8_D4
 SG_ MFL_M_Key : 31|1@1+ (1.0,0.0) [0.0|1] ""  Getriebe_AL551_951_D4_C7

VAL_ 159 EPS_HCA_Status 0 "disabled" 1 "initializing" 2 "fault" 3 "ready" 4 "rejected" 5 "active" ;
VAL_ 269 ACC_Enable_TorqueReq 0 "TorqueReq_Not_Enabled" 1 "TorqueReq_Enabled" ;
VAL_ 269 ACC_Enable_DecelReq 0 "DecelReq_Not_Enabled" 1 "DecelReq_Enabled" ;
VAL_ 269 ACC_GearboxPosition_P 0 "P_Position_Not_Requested" 1 "Request_P_Position" ;
VAL_ 269 ACC_Limited_PullAwayDyn 0 "No_Limitation" 1 "Limitation_PullAwayDynamics_Requested" ;
VAL_ 269 ACC_Loeseanforderung 0 "No_Request" 1 "Loeseanforderung" ;
VAL_ 269 ACC_StartStop_Info 0 "EngineRunning_LongTerm_Not_Necessary_StopEnable" 1 "EngineStartUp_Not_Mandatory_Necessary_StopInhibit_No_StartRequest" 2 "EngineStartUp_Mandatory_Necessary_StartRequest" 3 "SystemError" ;
VAL_ 269 ACC_Vorbefuellung_BrakeSystem 0 "Vorbefuellung_OFF" 1 "Vorbefuellung_ON" ;
VAL_ 269 ACC_Status_ACC 0 "ACC_OFF_MainSwitch_Off" 1 "ACC_INIT" 2 "ACC_STANDBY" 3 "ACC_Active_Controls" 4 "ACC_OVERRIDE" 5 "Not_Defined" 6 "Reversible_Error_In_ACC_System" 7 "Irreversible_Error_In_ACC_System" ;
VAL_ 269 ACC_Actuation_EPB 0 "No_EPB_Request" 1 "EPB_Actuator_Close" ;
VAL_ 269 ACC_Influence_ESP 0 "No_Zwangszuschaltung" 1 "ESP_Zwangszuschaltung" ;
VAL_ 269 ACC_Stop 0 "No_Stop_Requested" 1 "Stop_Requested" ;
VAL_ 269 ACC_KD_Error 0 "No_KD_Error" 1 "KD_Error" ;
VAL_ 64 FROM_RGS_Anst 4 "Active_Level_1" 5 "Active_Level_2" 6 "Active_Level_3" 7 "Active_Level_4" 8 "Deactivated" ;
VAL_ 64 FROM_Front_Crash 0 "No_Front_Crash" 1 "Front_Crash" ;
VAL_ 64 FROM_Rear_Crash 0 "No_Rear_Crash" 1 "Rear_Crash" ;
VAL_ 64 FROM_SF_Crash 0 "No_Side_Crash_Driver" 1 "Side_Crash_Driver" ;
VAL_ 64 FROM_SB_Crash 0 "No_Side_Crash_Passenger" 1 "Side_Crash_Passenger" ;
VAL_ 64 FROM_Rollover_Crash 0 "No_Rollover" 1 "Rollover" ;
VAL_ 64 FROM_Crash_Int 0 "No_Crash" 1 "Crash_Intensity_1" 2 "Crash_Intensity_2_(Only_ActuatorTest_B8)" 3 "Crash_Intensity_2_(Only_D4_C7_Colorado_NF_PAG__Crash_In_B8)" 4 "Crash_Intensity_3_(Old_VW/AUDI__Stellgiedtest_B8)" 5 "Crash_Intensity_3_(Old_PAG)" 7 "Crash_Intensity_3" ;
VAL_ 64 FROM_Lamp 0 "Off" 1 "On" ;
VAL_ 64 FROM_Deactivated 0 "Active" 1 "Deactivated" ;
VAL_ 64 FROM_VB_Deactivated 0 "PassengerAirbag_Active" 1 "PassengerAirbag_Deactivated" ;
VAL_ 64 FROM_SystemError 0 "No_Error" 1 "Airbag_SystemError" ;
VAL_ 64 FROM_Diagnostics 0 "Not_in_Diagnostics" 1 "in_Diagnostics" ;
VAL_ 64 FROM_ActuatorTest 0 "Not_In_ActuatorTest" 1 "Airbag_In_ActuatorTest" ;
VAL_ 64 FROM_Erh_Open_VB 0 "No_Display" 1 "PassengerAirbag_Deactivated" 2 "PassengerAirbag_Activated" 3 "Not_Defined" ;
VAL_ 64 FROM_BeltWarn_VF 0 "No_Warning" 1 "BeltWarning_Trigger" ;
VAL_ 64 FROM_BeltWarn_VB 0 "No_Warning" 1 "BeltWarning_Trigger" ;
VAL_ 64 FROM_Display_Pedestrian 0 "No_FSG_Aktion_Triggered" 1 "Bonnet_Open" 2 "SystemError" ;
VAL_ 64 FROM_Texte_AKS 0 "No_AKS_Ausloesung" 1 "AKS_Triggered" 2 "AKS_SystemError" ;
VAL_ 64 FROM_PAO_Lamp_Req 0 "Lamp_SwitchOff" 1 "Lamp_SwitchOn" ;
VAL_ 64 FROM_MKB_Valid 0 "MultiCollisionBraking_Not_Unlocked" 1 "MultiCollisionBraking_Unlocked" ;
VAL_ 64 FROM_MKB_Request 0 "MultiCollisionBraking_Not_Requested" 1 "MultiCollisionBraking_Requested" ;
VAL_ 64 FROM_SupplyVoltage 0 "Plausible" 1 "Implausible" ;
VAL_ 64 FROM_KD_Error 0 "No_KD_Error" 1 "KD_Error" ;
VAL_ 1312 FROM_Occupancy_VB 0 "Not_Available" 1 "Error" 2 "Not_Occupied" 3 "Occupied" ;
VAL_ 1312 FROM_BeltBuckle_FA 0 "Not_Fitted" 1 "Not_Avail�gbar (Error Or Init)" 2 "Not_Inserted" 3 "Inserted" ;
VAL_ 1312 FROM_BeltBuckle_BF 0 "Not_Fitted" 1 "Not_Avail�gbar (Error Or Init)" 2 "Not_Inserted" 3 "Inserted" ;
VAL_ 1312 FROM_BeltBuckle_Row2_FA 0 "Not_Fitted" 1 "Not_Avail�gbar (Error Or Init)" 2 "Not_Inserted" 3 "Inserted" ;
VAL_ 1312 FROM_BeltBuckle_Row2_MI 0 "Not_Fitted" 1 "Not_Avail�gbar (Error Or Init)" 2 "Not_Inserted" 3 "Inserted" ;
VAL_ 1312 FROM_BeltBuckle_Row2_BF 0 "Not_Fitted" 1 "Not_Avail�gbar (Error Or Init)" 2 "Not_Inserted" 3 "Inserted" ;
VAL_ 1312 FROM_BeltBuckle_Row3_FA 0 "Not_Fitted" 1 "Not_Avail�gbar (Error Or Init)" 2 "Not_Inserted" 3 "Inserted" ;
VAL_ 1312 FROM_BeltBuckle_Row3_MI 0 "Not_Fitted" 1 "Not_Avail�gbar (Error Or Init)" 2 "Not_Inserted" 3 "Inserted" ;
VAL_ 1312 FROM_BeltBuckle_Row3_BF 0 "Not_Fitted" 1 "Not_Avail�gbar (Error Or Init)" 2 "Not_Inserted" 3 "Inserted" ;
VAL_ 1312 FROM_SeatPos_Sens_FA 0 "Not Avail�gbar" 1 "Error" 2 "Seat Not Front" 3 "Seat Front" ;
VAL_ 1312 FROM_SeatPos_Sens_BF 0 "Not Avail�gbar" 1 "Error" 2 "Seat Not Front" 3 "Seat Front" ;
VAL_ 1633 AAG_BrakeLight_By_ECD 0 "BrakeLight_Actual_Off" 1 "BrakeLight_By_ECD_Active" ;
VAL_ 1633 AAG_Trailer_Unplugged 1 "Trailer_Was_At_TERM15_Off_Unplugged" ;
VAL_ 1633 AAG_NSL_Active 1 "Trailer_Nebelschusslicht_Active" ;
VAL_ 1633 AAG_Trailer_Detected 0 "No_Trailer_Detected" 1 "AAG_Trailer_Detected" ;
VAL_ 1633 AAG_Indicator_H_Active 1 "Trailer_Indicator_Active" ;
VAL_ 1633 AAG_Indicator_HL_def 1 "Trailer_Indicator_Left_Defective" ;
VAL_ 1633 AAG_Indicator_HR_def 1 "Trailer_Indicator_Right_Defective" ;
VAL_ 1633 AAG_BrakeLight_H_def 1 "Trailer_BrakeLight_Defective" ;
VAL_ 1633 AAG_TailLight_HL_def 1 "Trailer_TailLight_Left_Defective" ;
VAL_ 1633 AAG_TailLight_HR_def 1 "Trailer_TailLight_Right_Defective" ;
VAL_ 1633 AAG_KD_Error 0 "No_KD_Error" 1 "KD_Error" ;
VAL_ 1633 AAG_AVS_Error 0 "iO" 1 "niO" 2 "niO_VehicleStop_Required" 3 "tbd" ;
VAL_ 1633 AAG_AVS_Statuses 0 "EndPosition Retracted Reached" 1 "EndPosition Extended Reached" 2 "OffDrive Automatic " 3 "OnDrive Automatic" 4 "OffDrive Manual " 5 "OnDrive Manual" 6 "zwischenposition" 7 "Not Initialised" ;
VAL_ 777 BEM_Coast_Info 0 "No_Request" 1 "MinRpm_1" 2 "MinRpm_2" 3 "Segelveto" ;
VAL_ 777 BEM_P_Alternator 255 "Error" ;
VAL_ 777 BEM_n_LLA 0 "No_Increase" 1 "Stage_1" 2 "Stage_2" 3 "Stage_3" ;
VAL_ 777 BEM_01_ShutoffStages 0 "Stage_0_No_Restriction" 1 "Stage_1" 2 "Stage_2" 3 "Stage_3" 4 "TransportMode" 7 "Ruhestrommessmodus" ;
VAL_ 777 BEM_Req_TERM 0 "No Request" 1 "Request K�hlerl�fter Actuation" ;
VAL_ 777 BEM_StartStop_Info 0 "EngineRunning_Not_Necessary_(StopEnable)" 1 "EngineStartUp_Not_Mandatory_Necessary_(StopInhibit,No_StartRequest)" 2 "EngineStartUp_Mandatory_Necessary_(StartRequest)" 3 "SystemError" ;
VAL_ 901 CHA_SystemStatus 0 "Status in Order" 1 "Reserved" 2 "Reserved" 3 "Reserved" ;
VAL_ 901 CHA_Driver_Changeover 0 "No_Or_Automatic Changeover" 1 "manuelle_Changeover" ;
VAL_ 901 CHA_Target_DrivePr_MO 0 "Not_Occupied" 1 "Programm_1" 2 "Programm_2" 3 "Programm_3" 4 "Programm_4" 5 "Programm_5" 6 "Programm_6" 7 "Programm_7" ;
VAL_ 901 CHA_Target_DrivePr_GE 0 "Not_Occupied" 1 "Programm_1" 2 "Programm_2" 3 "Programm_3" 4 "Programm_4" 5 "Programm_5" 6 "Programm_6" 7 "Programm_7" ;
VAL_ 901 CHA_Target_DrivePr_ST 0 "Not_Occupied" 1 "Programm_1" 2 "Programm_2" 3 "Programm_3" 4 "Programm_4" 5 "Programm_5" 6 "Programm_6" 7 "Programm_7" ;
VAL_ 901 CHA_Target_DrivePr_SCU 0 "Not_Occupied" 1 "Programm_1" 2 "Programm_2" 3 "Programm_3" 4 "Programm_4" 5 "Programm_5" 6 "Programm_6" 7 "Programm_7" ;
VAL_ 901 CHA_Target_DrivePr_DR 0 "Not_Occupied" 1 "Programm_1" 2 "Programm_2" 3 "Programm_3" 4 "Programm_4" 5 "Programm_5" 6 "Programm_6" 7 "Programm_7" ;
VAL_ 901 CHA_Target_DrivePr_QS 0 "Not_Occupied" 1 "Programm_1" 2 "Programm_2" 3 "Programm_3" 4 "Programm_4" 5 "Programm_5" 6 "Programm_6" 7 "Programm_7" ;
VAL_ 901 CHA_Target_DrivePr_AFS 0 "Not_Occupied" 1 "Programm_1" 2 "Programm_2" 3 "Programm_3" 4 "Programm_4" 5 "Programm_5" 6 "Programm_6" 7 "Programm_7" ;
VAL_ 901 CHA_Target_DrivePr_RGS 0 "Not_Occupied" 1 "Programm_1" 2 "Programm_2" 3 "Programm_3" 4 "Programm_4" 5 "Programm_5" 6 "Programm_6" 7 "Programm_7" ;
VAL_ 901 CHA_Target_DrivePr_EPS 0 "Not_Occupied" 1 "Programm_1" 2 "Programm_2" 3 "Programm_3" 4 "Programm_4" 5 "Programm_5" 6 "Programm_6" 7 "Programm_7" ;
VAL_ 901 CHA_Target_DrivePr_ACC 0 "Not_Occupied" 1 "Programm_1" 2 "Programm_2" 3 "Programm_3" 4 "Programm_4" 5 "Programm_5" 6 "Programm_6" 7 "Programm_7" ;
VAL_ 901 CHA_Target_DrivePr_SAK 0 "Not_Occupied" 1 "Programm_1" 2 "Programm_2" 3 "Programm_3" 4 "Programm_4" 5 "Programm_5" 6 "Programm_6" 7 "Programm_7" ;
VAL_ 1714 DGN_UnlearnCounter 255 "ung�ltiger Z�hlerstand Or No g�ltiger DriveCycle" ;
VAL_ 1714 KBI_Odometer 1048574 "Init" 1048575 "Error" ;
VAL_ 1714 UH_Month 14 "Reserved" ;
VAL_ 1714 UH_Tag 0 "Reserved" ;
VAL_ 1714 Cluster_02_Old 0 "Current" 1 "Outdated" ;
VAL_ 1714 ClockTime_01_Old 0 "Current" 1 "Outdated" ;
VAL_ 1520 DI_TERM_58d 254 "Init" 255 "Error" ;
VAL_ 1520 DI_TERM_58s 126 "Init" 127 "Error" ;
VAL_ 1520 DI_TERM_58St 126 "Init" 127 "Error" ;
VAL_ 1603 KBI_Unit_Date 0 "Tag/Month/Year" 1 "Month/Tag/Year" 2 "Year/Month/Tag" 3 "Reserved" ;
VAL_ 1603 KBI_Unit_Pressure 0 "PressureInfo in bar" 1 "PressureInfo in psi" 2 "PressureInfo in kPa" 3 "tbd." ;
VAL_ 1603 KBI_Unit_Streckenanz 0 "Kilometres" 1 "Miles" ;
VAL_ 1603 KBI_MFA_v_Unit_02 0 "kmh" 1 "mph" ;
VAL_ 1603 KBI_Unit_Temp 0 "Degree Celsius �C" 1 "Degree Fahrenheit �F" ;
VAL_ 1603 KBI_Unit_ClockTime 0 "24h" 1 " 12h AT/PM" ;
VAL_ 1603 KBI_Unit_Consumption 0 "mpg UK" 1 "mpg USA" 2 "Litres/100km" 3 "km/Litres" ;
VAL_ 1603 KBI_Unit_Volume 0 "Litres" 1 "Gallons UK" 2 "Gallons USA" 3 "Reserved" ;
VAL_ 260 EPB_QBit_LongAccel 0 "g�ltiger Value" 1 "Substitute-, Init- Or ErrorValue" ;
VAL_ 260 EPB_QBit_PedalTravel_Clutch 0 "g�ltiger Value" 1 "Substitute-, Init- Or ErrorValue" ;
VAL_ 260 EPB_BCM2_Engine_Wakeup 0 "No Request" 1 "Request On BCM2 Wakeupleitung To Engine hochzuziehen DueTo From Car-Wakeup" ;
VAL_ 260 EPB_Enable_Decel_Req 0 "Not Enabled" 1 "Enabled" ;
VAL_ 260 EPB_LongAccel 255 "Error" ;
VAL_ 260 EPB_PedalTravel_Clutch 0 "Init" 255 "Error" ;
VAL_ 260 EPB_PullAwayRequest_Detected 0 "No PullAwayRequest Detected" 1 "PullAwayRequest Detected" ;
VAL_ 260 EPB_DAA_BoundaryCond_erf 0 "BoundaryCond_Not_Met" 1 "BoundaryCond_Met" ;
VAL_ 260 EPB_ErrorStatus 0 "No Error in EPB - AVH May From ESP OffFilt�hrt Become" 1 "Only VW526: tempor�rer Error" 2 "Only VW526: EPB in Diagnostics" 3 "Error in EPB - AVH May From ESP Not OffFilt�hrt Become" ;
VAL_ 260 EPB_Schalterposition 0 "No DriverRequest" 1 "DriverRequest �ffnen" 2 "DriverRequest Schlie�en" 3 "Error" ;
VAL_ 260 EPB_QBit_Schalterpos 0 "g�ltiger Value (Full Function)" 1 " Substitute-, Init- Or ErrorValue (Switch ausser Function)" ;
VAL_ 260 EPB_Consistency_ACC 0 "No Error Detected" 1 "Error Detected" ;
VAL_ 260 EPB_ClampForce 30 "Init" 31 "Error" ;
VAL_ 260 EPB_Status 0 "Open" 1 "Brake_geschl_(ClampForce_Full/reduziert)" 2 "Actuator In Run" 3 "Error" ;
VAL_ 260 EPB_KD_Error 0 "No_KD_Error" 1 "KD_Error" ;
VAL_ 781 EPB_FaultLamp_Yellow 0 "Off" 1 "On" ;
VAL_ 781 EPB_FaultLamp_BKL 0 "BKL Off" 1 "BKL On" ;
VAL_ 781 EPB_FunctionLamp 0 "Off" 1 "On" ;
VAL_ 781 EPB_Texte 0 "No_Display" 1 "InclinationAngle_Closed_Large" 2 "ParkingBrake_From_Hand_Open" 3 "EPB_in_Diagnostics" 4 "BrakePedal_Press" 5 "tbd." 6 "tbd." 7 "St�rung PullAwayAssistant" 8 "Abschleppschutz Blocked" ;
VAL_ 781 EPB_Acoustic 0 "WarningTone Off" 1 "WarningTone On" ;
VAL_ 781 EPB_AutoHoldLamp 0 "Lamp Off (AutoHold Inactive)" 1 "Lamp On (AutoHold Active)" ;
VAL_ 781 EPB_BrakePad_Warn 0 "BrakePad_ok" 1 "BrakePad_Under_Minimum" ;
VAL_ 256 ASR_Torque_Slow 1022 "Init" 1023 "Error" ;
VAL_ 256 ASR_MSR_Torque_Fast 1022 "Init" 1023 "Error" ;
VAL_ 256 ESP_v_Signal 65533 "Undervoltage" 65534 "Init" 65535 "Error" ;
VAL_ 256 ASR_Keying_Passive 0 "ASR_Activated" 1 "ASR_Passive_Keyed_Or_Thresholds_Changed" ;
VAL_ 256 ESP_Keying_Passive 0 "ESP_Activated" 1 "ESP_Passive_Keyed_Or_Thresholds_Changed" ;
VAL_ 256 ESP_SystemStatus 0 "iO" 1 "Error" ;
VAL_ 256 ASR_ShiftIntervention 0 "No Request" 1 "ASR_ShiftMap" 2 "R�ckschaltung" 3 "ShiftInhibit" ;
VAL_ 256 OBD_RoughRoad 0 "No RoughRoad Detected" 1 "RoughRoad Detected" ;
VAL_ 256 OBD_QBit_RoughRoad 0 "Valid_Value" 1 "Substitute_Init_Or_ErrorValue" ;
VAL_ 256 ESP_QBit_v_Signal 0 "Valid_Value" 1 "Substitute_Init_Or_ErrorValue" ;
VAL_ 256 ABS_Braking 0 "No_ABS_Control" 1 "ABS_Control_Active" ;
VAL_ 256 ASR_Req 0 "No_Request" 1 "ASR_Request" ;
VAL_ 256 MSR_Req 0 "No Request" 1 "MSR-Request" ;
VAL_ 256 EBV_Intervention 0 "No EBV-Intervention" 1 "EBV-Intervention" ;
VAL_ 256 EDS_Intervention 0 "No_EDS_Intervention" 1 "EDS_Intervention" ;
VAL_ 256 ESP_Intervention 0 "No_ESP_Intervention" 1 "ESP_Intervention_Active" ;
VAL_ 256 ESP_ASP 0 "Inactive" 1 "Active" ;
VAL_ 256 ESP_KD_Error 0 "No_KD_Error" 1 "KD_Error" ;
VAL_ 257 ESP_QBit_YawRate 0 "Valid_Value" 1 "Substitute_Init_Or_ErrorValue" ;
VAL_ 257 ESP_QBit_LongAccel 0 "Valid_Value" 1 "Substitute_Init_Or_ErrorValue" ;
VAL_ 257 ESP_QBit_LatAccel 0 "Valid_Value" 1 "Substitute_Init_Or_ErrorValue" ;
VAL_ 257 ESP_Stillstandsflag 0 "No_Standstill_Detected" 1 "Standstill_Detected" ;
VAL_ 257 ESP_LateralAccel 255 "Error" ;
VAL_ 257 ESP_LongAccel 1022 "Signal_Not_Present" 1023 "Error" ;
VAL_ 257 ESP_Verteil_RollTorque 30 "Init" 31 "Error" ;
VAL_ 257 ESP_QBit_Req_Vert_Roll 0 "Valid_Value" 1 "Substitute_Init_Or_ErrorValue" ;
VAL_ 257 ESP_YawRate 16383 "Error" ;
VAL_ 257 ESP_VZ_YawRate 0 "Positive" 1 "Negative" ;
VAL_ 257 ESP_Notbremsanzeige 0 "No_EmergencyBraking_Detected" 1 "EmergencyBraking_Detected" ;
VAL_ 257 ESP_VoltageReq 0 "No_Request" 1 "Request_VoltageValue_1" ;
VAL_ 257 ESP_PLA_Abort 0 "Init" 1 "SpeedExceedance" 2 "Wrong_PLA_Status" 3 "Deactivation_By_Abort_Steering" 4 "PLA_BrakeRequest_After_Standstill" 5 "Abort_By_Term15_Off" 6 "Abort_By_FT_Open" ;
VAL_ 257 ESP_Status_ESP_PLA 0 "ESP_PLA_Deactivated" 1 "ESP_PLA_Init" 2 "ESP_PLA_Error" 4 "ESP_PLA_Activatable" 6 "ESP_PLA_Brake_Active" 8 "ESP_PLA_Operational" 9 "ESP_PLA_Restart" 10 "ESP_PLA_Abort" ;
VAL_ 259 ESP_VL_FR 0 "Forward" 1 "Reverse" ;
VAL_ 259 ESP_VR_FR 0 "Forward" 1 "Reverse" ;
VAL_ 259 ESP_HL_FR 0 "Forward" 1 "Reverse" ;
VAL_ 259 ESP_HR_FR 0 "Forward" 1 "Reverse" ;
VAL_ 259 ESP_VL_WheelSpeed 4093 "Undervoltage" 4094 "Init" 4095 "Error" ;
VAL_ 259 ESP_VR_WheelSpeed 4093 "Undervoltage" 4094 "Init" 4095 "Error" ;
VAL_ 259 ESP_HL_WheelSpeed 4093 "Undervoltage" 4094 "Init" 4095 "Error" ;
VAL_ 259 ESP_HR_WheelSpeed 4093 "Undervoltage" 4094 "Init" 4095 "Error" ;
VAL_ 776 ESP_Meldungen 0 "No_Display_No_Chime" 1 "AutoHold_Notice_1_And_No_Chime" 2 "Malfunction_AutoHold_And_1x_Chime" 3 "Malfunction_HillHold_And_1x_Chime" 4 "TakeOver_And_1x_Chime" ;
VAL_ 776 ESP_HDC_FuncLamp 0 "Off" 1 "On" ;
VAL_ 776 ESP_Lamp 0 "Off" 1 "On" ;
VAL_ 776 ABS_Lamp 0 "Off" 1 "On" ;
VAL_ 776 BK_Lamp 0 "Off" 1 "On" ;
VAL_ 776 ESP_Acoustic 0 "No_Acoustic" 1 "1x_Beep" ;
VAL_ 776 ESP_Diagnostics 0 "ESP_Not_in_Diagnostics" 1 "ESP_in_Diagnostics" ;
VAL_ 776 ESP_Textanzeigen_02 0 "No_Text" 1 "ESP_Malfunction" 2 "ABS_Malfunction" 3 "ESP_ABS_Malfunction" 4 "Not_Defined" 5 "ASR_Malfunction" 6 "ESP_switched_off" 7 "ASR_off" 8 "ESP_ASR_on" 9 "Malfunction_HillHold" 10 "No_BrakeForceAmplification" 11 "ASR_Activated" 12 "ABS_ASR_Malfunction" 13 "Please_Tyre_Check" 14 "Malfunction_AutoHold" 15 "ESP_offroad" 16 "AutoHold_Notice_1" 17 "ESP_sport" 18 "ESP_ForcedActivation" ;
VAL_ 776 ESP_Off_Lamp 0 "Lamp_Off" 1 "Lamp_On" ;
VAL_ 776 ESP_m_WheelSpeed 32765 "Undervoltage" 32766 "Init" 32767 "Error" ;
VAL_ 776 ESP_ASR_Lamp 0 "ESP_ASR_Lamp_Off" 1 "ESP_ASR_Lamp_On" ;
VAL_ 776 ESP_ErrorStatus_DistPulse 0 "DistancePulses_iO" 1 "Error" ;
VAL_ 776 ESP_DistPulse_Overflow 0 "Reset And No �RangeRun" 1 "AtLeast 1x �RangeRun" ;
VAL_ 776 ESP_QBit_DistPulse_VA 0 "Valid_Value" 1 "Substitute_Init_Or_ErrorValue" ;
VAL_ 776 ESP_Displaywarnungen 0 "No_Warning" 1 "BKL_Display_Warning" ;
VAL_ 776 ESP_HDC_ControlSpeed 0 "Not_Fitted" 125 "HDC_Standby" 127 "Error" ;
VAL_ 776 ESP_BKV_Warning 0 "No_Display_No_Chime" 1 "No_BrakeForceAmplification_plus_1x_Chime" ;
VAL_ 262 ESP_QBit_BrakePressure 0 "Valid_Value" 1 "Substitute_Init_Or_ErrorValue" ;
VAL_ 262 ESP_QBit_Driver_Brakes 0 "Valid_Value" 1 "Substitute_Init_Or_ErrorValue" ;
VAL_ 262 ESP_Threshold_Vacuum 0 "No_Signal" 1 "Vacuum_Smaller_Equal_450_mbar" 2 "Vacuum_Greater_450_mbar" 3 "Error_Unterdrucksensor" ;
VAL_ 262 ESP_BrakePressure 1023 "Error" ;
VAL_ 262 ESP_Driver_Brakes 0 "BrakePressureThreshold_Not_Exceeded" 1 "BrakePressureThreshold_Exceeded" ;
VAL_ 262 ESP_Decel_TSK_Active 0 "TSK_Deceleration_Inactive" 1 "TSK_Deceleration_Active" ;
VAL_ 262 ESP_SteeringIntervention_ADS 0 "No_SteeringIntervention" 1 "stabilisierender_SteeringIntervention" ;
VAL_ 262 ESP_Consistency_TSK 0 "Message_For_DecelerationRequest_Consistent" 1 "Message_For_DecelerationRequest_Not_Consistent" ;
VAL_ 262 ESP_BrakeJerk_AWV2 0 "No_BrakeJerk_ausgefuehrt" 1 "BrakeJerk_ausgefuehrt" ;
VAL_ 262 ESP_Consistency_AWV2 0 "Message_For_AWV2_Consistent" 1 "Message_For_AWV2_Not_Consistent" ;
VAL_ 262 ECD_Error 0 "ECD_iO" 1 "ECD_Error" ;
VAL_ 262 ECD_Not_Available 0 "ECD_Function_Available" 1 "ECD_Function_Not_Available" ;
VAL_ 262 ESP_Status_BrakesTemp 0 "Brake Not �berhitzt" 1 "Brake �berhitzt" ;
VAL_ 262 ESP_AutoHold_Standby 0 "AutoHold_Not_In_Standby" 1 "AutoHold_In_Standby" ;
VAL_ 262 ESP_HDC_Standby 0 "HDC_Function_Not_In_Standby" 1 "HDC_Function_In_Standby" ;
VAL_ 262 ESP_HBA_Active 0 "HBA_Not_Active" 1 "HBA_Active" ;
VAL_ 262 ESP_Prefill_Triggered 0 "Not_Triggered" 1 "Prefill_Triggered" ;
VAL_ 262 ESP_Reversing_Detected 0 "No_Rueckwaetsfahrt" 1 "Reversing_Detected" ;
VAL_ 262 ESP_Status_HillStartAssist 0 "Off" 1 "On" ;
VAL_ 262 ESP_HDC_Active 0 "Inactive" 1 "Active" ;
VAL_ 262 ESP_StartStop_Info 0 "EngineRunning_Not_Necessary_(StopEnable)" 1 "EngineStartUp_Not_Mandatory_Necessary_(StopInhibit,No_StartRequest)" 2 "EngineStartUp_Mandatory_Necessary_(StartRequest)" 3 "SystemError" ;
VAL_ 262 ESP_Interv_HL 0 "No_Intervention" 1 "ESP_Intervention_HL" ;
VAL_ 262 ESP_Interv_HR 0 "No_Intervention" 1 "ESP_Intervention_HR" ;
VAL_ 262 ESP_Interv_VL 0 "No_Intervention" 1 "ESP_Intervention_VL" ;
VAL_ 262 ESP_Interv_VR 0 "No_Intervention" 1 "ESP_Intervention_VR" ;
VAL_ 262 ESP_BKV_Vacuum 255 "Error" ;
VAL_ 262 ESP_AutoHold_Active 0 "AutoHold Inactive" 1 "AutoHold Active" ;
VAL_ 262 ESP_FStatus_HillStartAssist 0 "No_Error" 1 "Error" ;
VAL_ 262 ESP_Decel_EPB_Active 0 "Not Activated" 1 "Activated" ;
VAL_ 262 ECD_BrakeLight 0 "Off" 1 "On" ;
VAL_ 262 ESP_Decel_EPB_Avail 0 "Not Available" 1 "System Available" ;
VAL_ 262 ESP_Status_BrakePressure 0 "Brake drucklos" 1 "With BrakePressure" ;
VAL_ 262 ESP_Request_EPB 0 "No_Request" 1 "Request_Open" 2 "Request_Close" 3 "Reserved" ;
VAL_ 132 ESP_06_KD_Error 0 "No_KD_Error" 1 "KD_Error" ;
VAL_ 132 ESP_VZ_Teilsollwinkel 0 "Positive" 1 "Negative" ;
VAL_ 132 ESP_AngleIntervention 0 "No Intervention" 1 "Intervention With langsamer R�ckf�hrung" 2 "Intervention With mittlerer R�ckf�hrung" 3 "Intervention With Faster R�ckf�hrung" ;
VAL_ 132 ESP_Status_ADS 0 "ADS iO" 1 "ADS Yet Not Avail�gbar" 2 "ADS tempor�r Not Avail�gbar" ;
VAL_ 132 ESP_v_ref 4093 "Undervoltage" 4095 "Error" ;
VAL_ 914 ESP_ACC_LDE 0 "Lebensdauerende_Not_Reached" 1 "Lebensdauerende_Reached" ;
VAL_ 914 ESP_Quattro_Drive 0 "Front" 1 "AllWheelDrive" ;
VAL_ 914 ESP_Coding_ADS 0 "Init" 1 "ESP_Not_ADS_Coded" 2 "ADS_Coded" 3 "tbd" ;
VAL_ 914 ESP_RTA_HL 254 "Alignment_nocht_Not_genuegend_konvergent" 255 "Error" ;
VAL_ 914 ESP_RTA_HR 254 "Alignment_nocht_Not_genuegend_konvergent" 255 "Error" ;
VAL_ 914 ESP_RTA_VR 254 "Alignment_nocht_Not_genuegend_konvergent" 255 "Error" ;
VAL_ 914 OBD_Error_WheelSensor_HL 0 "No_Error" 1 "KS-" 2 "KS+" 3 "OC" 4 "OOR+" 5 "OOR-" 6 "RC+" 7 "RC-" 8 "KS+/OC" 9 "KS-/OC" 10 "KS-/KS+" 11 "KS-/KS+/OC" 12 "Free" 13 "Free" 14 "Free" 15 "Free" ;
VAL_ 914 OBD_Error_WheelSensor_HR 0 "No_Error" 1 "KS-" 2 "KS+" 3 "OC" 4 "OOR+" 5 "OOR-" 6 "RC+" 7 "RC-" 8 "KS+/OC" 9 "KS-/OC" 10 "KS-/KS+" 11 "KS-/KS+/OC" 12 "Free" 13 "Free" 14 "Free" 15 "Free" ;
VAL_ 914 OBD_Error_WheelSensor_VL 0 "No_Error" 1 "KS-" 2 "KS+" 3 "OC" 4 "OOR+" 5 "OOR-" 6 "RC+" 7 "RC-" 8 "KS+/OC" 9 "KS-/OC" 10 "KS-/KS+" 11 "KS-/KS+/OC" 12 "Free" 13 "Free" 14 "Free" 15 "Free" ;
VAL_ 914 OBD_Error_WheelSensor_VR 0 "No_Error" 1 "KS-" 2 "KS+" 3 "OC" 4 "OOR+" 5 "OOR-" 6 "RC+" 7 "RC-" 8 "KS+/OC" 9 "KS-/OC" 10 "KS-/KS+" 11 "KS-/KS+/OC" 12 "Free" 13 "Free" 14 "Free" 15 "Free" ;
VAL_ 914 ESP_Qualification_DriveType 0 "alte_Bedeutung_Bit_ESP_Quattro_Drive" 1 "New_Bedeutung_Bit_ESP_Quattro_Drive" ;
VAL_ 914 ESP_Offroad_Mode 0 "No_ESP_OffroadMode" 1 "ESP_OffroadMode" ;
VAL_ 914 ESP_MKB_ausloesbar 0 "MultiCollisionBraking_Not_Unlocked" 1 "MultiCollisionBraking_Unlocked" ;
VAL_ 914 ESP_MKB_Status 0 "MultiCollisionBraking_Not_Active" 1 "MultiCollisionBraking_Active" ;
VAL_ 914 ESP_CM_Variant 0 "Standard" 1 "Extended" ;
VAL_ 914 ESP_OBD_Status 0 "MIL_Off" 1 "MIL_On" ;
VAL_ 1623 ESP_BrakesTemp_Rear 0 "Temp_Smaller_99DegreeC" 1 "Temp_Between_100-199DegreeC" 2 "Temp_Between_200-299DegreeC" 3 "Temp_Between_300-399DegreeC" 4 "Temp_Between_400-499DegreeC" 5 "Temp_Between_500-599DegreeC" 6 "Temp_Greater_599DegreeC" 7 "Error" ;
VAL_ 924 BCM1_02_Old 0 "Current" 1 "Outdated" ;
VAL_ 924 Wiper_01_Old 0 "Current" 1 "Outdated" ;
VAL_ 924 Climate_02_Old 0 "Current" 1 "Outdated" ;
VAL_ 924 BCM1_01_Old 0 "Current" 1 "Outdated" ;
VAL_ 924 ESP_07_Old 0 "Current" 1 "Outdated" ;
VAL_ 924 DoorECU_BT_1_Old 0 "Current" 1 "Outdated" ;
VAL_ 924 DoorECU_HL_1_Old 0 "Current" 1 "Outdated" ;
VAL_ 924 DoorECU_HR_1_Old 0 "Current" 1 "Outdated" ;
VAL_ 924 Engine_02_Old 0 "Current" 1 "Outdated" ;
VAL_ 924 Climate_Sensor_02_Old 0 "Current" 1 "Outdated" ;
VAL_ 924 DoorECU_FT_1_Old 0 "Current" 1 "Outdated" ;
VAL_ 924 Engine_05_Old 0 "Current" 1 "Outdated" ;
VAL_ 924 QSP_01_Old 0 "Current" 1 "Outdated" ;
VAL_ 924 ParkAssist_01_Old 0 "Current" 1 "Outdated" ;
VAL_ 924 Chassis_02_Old 0 "Current" 1 "Outdated" ;
VAL_ 924 BCM1_MH_WIV_Switch 0 "MH_Closed" 1 "MH_Open" ;
VAL_ 924 Wiper_Front_Active 1 "Wiper Front l�uft" ;
VAL_ 924 BCM1_ReversingLight_Switch 0 "Off" 1 "Pressed" ;
VAL_ 924 MO_Status_NormalOperation_01 0 "No NormalOperation" 1 "NormalOperation Reached" ;
VAL_ 924 TERM_AuxHeater_Enable 0 "No_Enable_AuxHeater" 1 "AuxHeaterEnable" ;
VAL_ 924 BCM1_ForwardGear_Engaged 0 "ReverseGear bzw. restliche Gears Engaged" 1 "First Or Second Gear Engaged" ;
VAL_ 924 ESP_Coding_ADS 0 "Init" 1 "ESP_Not_ADS_Coded" 2 "ADS_Coded" 3 "tbd" ;
VAL_ 924 QSP_StartStop_Info 0 "EngineRunning_Not_Necessary_(StopEnable)" 1 "EngineStartUp_Not_Mandatory_Necessary_(StopInhibit,No_StartRequest)" 2 "EngineStartUp_Mandatory_Necessary_(StartRequest)" 3 "SystemError" ;
VAL_ 924 FA_StartStop_Info 0 "EngineRunning_Not_Necessary_(StopEnable)" 1 "EngineStartUp_Not_Mandatory_Necessary_(StopInhibit,No_StartRequest)" 2 "EngineStartUp_Mandatory_Necessary_(StartRequest)" 3 "SystemError" ;
VAL_ 924 PH_StartStop_Info 0 "EngineRunning_Not_Necessary_(StopEnable)" 1 "EngineStartUp_Not_Mandatory_Necessary_(StopInhibit,No_StartRequest)" 2 "EngineStartUp_Mandatory_Necessary_(StartRequest)" 3 "SystemError" ;
VAL_ 924 TERM_FoggingRisk 0 "No_FoggingRisk" 1 "FoggingRisk" ;
VAL_ 924 BCM1_GLW_HighBeam_Req 0 "Off" 1 "On" ;
VAL_ 924 BCM1_RHeadlights_Veh_Req 0 "Light_Not_Requested" 1 "Light Actual ToSwitchOn" ;
VAL_ 924 FT_Door_Opened 1 "Door Open" ;
VAL_ 924 MO_Handshake_STH 0 "No EKP-Actuation By STH-Request" 1 "EKP-Actuation By STH-Request" ;
VAL_ 924 FT_ParkPawl 0 "Lock_in_PreDetent_And_MainDetent" 1 "Door_Open_Or_Door_Position_Between_Before_And_MainDetent" ;
VAL_ 924 BCM1_OBD_FStatus_ATemp 0 "No Error" 1 "KS-" 2 "KS+" 3 "OC (WireBreak)" 4 "OOR+ (out of range high)" 5 "OOR- (out of range low)" 6 "RC+ (Signal Implausible High)" 7 "RC- (Signal Implausible Low)" 8 "KS+/OC" 9 "KS-/OC" 10 "KS-/KS+" 11 "KS-/KS+/OC (allgemeiner Error)" ;
VAL_ 924 BCM1_Outside_Temp_Unfilt 253 "Not Fitted" 254 "Initwert" 255 "Error" ;
VAL_ 924 BCM1_OilPressure_Switch 0 "Open" 1 "Closed (p > p Target)" ;
VAL_ 924 BCM1_OilPressure_Switch_2 0 "Open" 1 "Closed" ;
VAL_ 924 BT_Door_Opened 1 "Door_Open" ;
VAL_ 924 HL_Door_Opened 1 "Door Opened" ;
VAL_ 924 HR_Door_Opened 1 "Door Open" ;
VAL_ 924 BCM1_Adaptive_LightDistribution_Req 0 "Off" 1 "On" ;
VAL_ 924 BCM1_Sliding_Leuchtw_Req 0 "Off" 1 "On" ;
VAL_ 924 BCM1_Switch_StartStop 0 "Start_Stop_Over_MainSwitch_Deactivated" 1 "Start_Stop_Over_MainSwitch_Activated" ;
VAL_ 924 ESP_Offroad_Mode 0 "No_ESP_OffroadMode" 1 "ESP_OffroadMode" ;
VAL_ 924 MO_Enable_Recup 0 "Recuperation-Mode Off" 1 "Recommendation VoltageIncrease" 2 "Recommendation VoltageDecrease" 3 "RecuperationMode Active, VoltageVariation Not Necessary" ;
VAL_ 1604 SMLS_01_Old 0 "Current" 1 "Outdated" ;
VAL_ 1604 BCM1_01_Old 0 "Current" 1 "Outdated" ;
VAL_ 1604 BCM1_02_Old 0 "Current" 1 "Outdated" ;
VAL_ 1604 BCM2_02_Old 0 "Current" 1 "Outdated" ;
VAL_ 1604 HYB_Req_E_Mode_Old 0 "Current" 1 "Outdated" ;
VAL_ 1604 ESP_04_Old 0 "Current" 1 "Outdated" ;
VAL_ 1604 BH_Indicator_Left 0 "Not_Pressed" 1 "IndicatorLever_Direction_Left_Pressed" ;
VAL_ 1604 BH_Indicator_Right 0 "Not_Pressed" 1 "IndicatorLever_Direction_Right_Pressed" ;
VAL_ 1604 BM_Motorway 0 "MotorwayFlash Not Active " 1 "MotorwayFlash Active " ;
VAL_ 1604 BH_HighBeam 0 "Not_Pressed" 1 "IndicatorLever_in_Direction_HighBeam_Pressed" ;
VAL_ 1604 BH_HeadlightFlash 0 "Not_Pressed" 1 "IndicatorLever in Direction HeadlightFlash Pressed" ;
VAL_ 1604 BCM1_MH_Switch 0 "MH_Closed" 1 "MH_Open" ;
VAL_ 1604 HYB_Req_E_Mode 0 "PushButton_Not_Pressed" 1 "PushButton_Pressed" ;
VAL_ 1604 HUD_NV_in_Display 0 "NV_Not_in_Display" 1 "NV_in_Display" ;
VAL_ 1604 BCM1_Tourist_Light_Req 0 "Light_Not_Requested" 1 "Request From TouristLight" ;
VAL_ 1604 LV_LowBeam_Left_def 0 "OK" 1 "Defective" ;
VAL_ 1604 LV_LowBeam_Right_def 0 "OK" 1 "Defective" ;
VAL_ 1604 LV_LowBeam_Display 0 "Not Active" 1 "Active" ;
VAL_ 1604 LV_AFL_Active_Display 0 "Not Active" 1 "Active" ;
VAL_ 1604 BCM1_Light_Darkness_Active 1 "Light DueTo Darkness Active, Not At MotorwayLight, DaytimeRunningLight Or RainLight" ;
VAL_ 1604 LV_RearFogLight_Display 0 "Not Active" 1 "Active" ;
VAL_ 1604 BCM1_LeftHandTraffic 0 "RightHandTraffic" 1 "LeftHandTraffic" ;
VAL_ 1604 BCM2_P_Locked 0 "WH Not in Position P" 1 "WH in Position P" ;
VAL_ 1604 BCM1_LDS_Position 0 "Init" 1 "Position_0" 2 "Auto" 3 "SideLight" 4 "LowBeam" 7 "Error" ;
VAL_ 1604 BCM1_AllWeatherLight_Req 0 "Light_Not_Requested" 1 "Light_Actual_ToSwitchOn" ;
VAL_ 1604 HUD_DisplayFault_NV 0 "No_Error" 1 "DisplayFault" ;
VAL_ 1604 ESP_Diagnostics 0 "ESP_Not_in_Diagnostics" 1 "ESP_in_Diagnostics" ;
VAL_ 130 GE_ShiftOperation 0 "No Shift" 1 "Shift Active" ;
VAL_ 130 GE_Status_Clutch 0 "Clutch ge�ffnet" 1 "Clutch geregelt" 2 "Clutch Closed" 3 "Error" ;
VAL_ 130 GE_Inhibit_Suppression 0 "No_Inhibit" 1 "Inhibit" ;
VAL_ 130 GE_MTorque_Target 1022 "No Intervention" 1023 "Error" ;
VAL_ 130 GE_MTorque_Status 0 "No Request" 1 "Reducing GearboxIntervention" 2 "erh�hender GearboxIntervention" 3 "�nderung With Sprung" ;
VAL_ 130 GE_MTorque_Lead 1022 "No_Request" 1023 "Error" ;
VAL_ 130 GE_Enable_MTorque_Lead 0 "Not_Enabled" 1 "Enabled" ;
VAL_ 130 GE_KD_Error 0 "No_KD_Error" 1 "KD_Error" ;
VAL_ 131 GE_Req_CylDeact 0 "Changeover Allowed" 1 "Changeover Prohibited" 3 "VMB-Recommendation" ;
VAL_ 131 GE_Synchro_RequestedRpm 511 "Error" ;
VAL_ 131 GE_Synchro_Time 255 "Error" ;
VAL_ 131 GE_Torque_Limit_Gradient 255 "No Limit (Init)" ;
VAL_ 131 GE_Anheb_TargetRpm_Idle 255 "Error" ;
VAL_ 131 GE_Vorsteuermoment 510 "Init" 511 "Error" ;
VAL_ 131 GE_Tachometer_Damping 0 "normale D�mpfung" 1 "Dynamic D�mpfung" ;
VAL_ 131 GE_OverrunCut_Unt 0 "Inactive" 1 "Active" ;
VAL_ 131 GE_Enable_Synchro 0 "Inactive" 1 "Active" ;
VAL_ 131 GE_HYB_RPM_Intervention 0 "No_RpmIntervention" 1 "Slip_Start" 2 "Low_Speed_Mode" ;
VAL_ 258 GE_Enable_Langfr_ProtectionTorque 0 "Not Enabled" 1 "Enabled" ;
VAL_ 258 GE_Uefkt 1023 "Error" ;
VAL_ 258 GE_TargetGear 0 "Gear P/N (Disengaged)" 1 "Gear 1" 2 "Gear 2" 3 "Gear 3" 4 "Gear 4" 5 "Gear 5" 6 "Gear 6" 7 "Gear 7" 8 "Gear R" 11 "Gear 8" 12 "Gear 9" 14 "ActualGear Not Defined" 15 "Error" ;
VAL_ 258 GE_StartStop_Info 0 "EngineRunning_Not_Necessary_(StopEnable)" 1 "EngineStartUp_Not_Mandatory_Necessary_(StopInhibit,No_StartRequest)" 2 "EngineStartUp_Mandatory_Necessary_(StartRequest)" 3 "SystemError" ;
VAL_ 258 GE_Langfr_ProtectionTorque 1022 "Init" 1023 "Error" ;
VAL_ 258 GE_SelectorLever 0 "UNDEFINED" 1 "INIT" 5 "P" 6 "R" 7 "N" 8 "D" 9 "S" 10 "E" 13 "T" 14 "T" ;
VAL_ 258 GE_InputSpeed 16382 "Init" 16383 "Error" ;
VAL_ 258 GE_LimpHome 0 "No LimpHome / Init" 1 "Gearbox In LimpHome" ;
VAL_ 258 GE_Coding_MSG 0 "Coding iO / Init" 1 "Coding niO" ;
VAL_ 1089 GE_Index_Fahrwid 255 "Error" ;
VAL_ 1089 GE_HeatRequest 0 "Maximum_Waermebedarf" 1 "No_Waermebedarf" 2 "Kuehlbedarf" 3 "Emergency_(Maximum_Kuehlbedarf)" ;
VAL_ 1089 GE_OBD_Status 0 "MIL Off" 1 "MIL On" ;
VAL_ 1089 GE_LFR_Adaptation 0 "For_Adaptation_geeignet" 1 "For_Adaptation_Not_geeignet" ;
VAL_ 1089 GE_OBD_AbsperrValve 0 "No_Error" 1 "KS-" 2 "KS+" 3 "OC" 4 "OOR+" 5 "OOR-" 6 "RC+" 7 "RC-" 8 "KS+/OC" 9 "KS-/OC" 10 "KS-/KS+" 11 "KS-/KS+/OC" 12 "Free" 13 "Free" 14 "Free" 15 "Free" ;
VAL_ 1089 GE_Grenzkriechmoment 62 "Init" 63 "Error" ;
VAL_ 1089 GE_Charisma_DrivePr 0 "Not_Occupied" 1 "Programm_1" 2 "Programm_2" 3 "Programm_3" 4 "Programm_4" 5 "Programm_5" 6 "Programm_6" 7 "Programm_7" ;
VAL_ 1089 GE_Charisma_Status 0 "Init" 1 "Available" 2 "Not_Available" 3 "Asynchronous_By_DriverDemand" ;
VAL_ 1089 GE_Charisma_Changeover 0 "Idle" 1 "Detection_ChangeoverPrompt" 2 "ControlMessage_Not_Defined" 3 "Changeover_Delayed" ;
VAL_ 1089 GE_Enable_ExpiryInfo_WFS 0 "Off" 1 "On" ;
VAL_ 1089 GE_LossTorque 255 "Error" ;
VAL_ 1089 GE_amax_Possible 511 "Value Actual Not Defined" ;
VAL_ 1089 GE_SumpTemperature 255 "Error" ;
VAL_ 1424 KY_Funkschl_Nr 0 "No Authorised Key Detected" 1 "Active_RemoteKey_Nr_01" 2 "Active_RemoteKey_Nr_02" 3 "Active_RemoteKey_Nr_03" 4 "Active_RemoteKey_Nr_04" 5 "Active_RemoteKey_Nr_05" 6 "Active_RemoteKey_Nr_06" 7 "Active_RemoteKey_Nr_07" 8 "Active_RemoteKey_Nr_08" 9 "Invalid_09" 10 "Invalid_10" 11 "Invalid_11" 12 "Invalid_12" 13 "Invalid_13" 14 "Invalid_14" 15 "Invalid_15" ;
VAL_ 1424 KY_ID_Geb_Authorised 0 "Key_Not_Authorised" 1 "Key Authorised" ;
VAL_ 1424 KY_ID_Geb_Inserted 0 "No_Key_In_IgnitionLock" 1 " Key Inserted In IgnitionLock" ;
VAL_ 1424 KY_FFB_Frequency 1 "433 MHz" 2 "315 MHz" 3 "868 MHz" ;
VAL_ 1424 KY_HF_Active 0 "Funktempfang_Not_Active" 1 "HF_RadioReception_Active" ;
VAL_ 1424 KY_LF_Active 0 "Funktempfang_Not_Active" 1 "LF_RadioReception_Active" ;
VAL_ 1424 KY_ELV_Lock 0 "ELV_Not_Locked" 1 "ELV Locked" ;
VAL_ 1424 KY_ELV_entr 0 "ELV_Not_Unlocked" 1 "ELV Unlocked" ;
VAL_ 1424 KY_ELV_enable_Request 0 "Enable_Not_Requested" 1 "Enable ELV Is Requested" ;
VAL_ 1424 KY_Valet_Parking 0 "No_Valet_Key_Detected" 1 "Valet Key Detected" ;
VAL_ 1424 KY_Keyless_Fitment 0 "No_Keyless_Fitted" 1 "Keyless Fitted" ;
VAL_ 1424 FBS_Warn_Steering_def 0 "iO" 1 "Defective" ;
VAL_ 1424 FBS_Warn_SteerLocking_def 0 "i.O." 1 "Defective" ;
VAL_ 1424 FBS_Warn_Key_Batt 0 "i.O." 1 "Defective" ;
VAL_ 1424 FBS_Prio_Warn_04 1 "Cluster Prio Warning FBS 4" ;
VAL_ 1424 FBS_Prio_Warn_05 1 "Cluster Prio Warning FBS 5" ;
VAL_ 1424 KYL_Warn_No_Key 1 "No Key Detected" ;
VAL_ 1424 KYL_Warn_Kessy_Defective 0 "Kessy_i.O." 1 "Kessy Defective" ;
VAL_ 1424 KY_KYL_Prio_Warn_03 1 "Cluster Prio Warning Keyless 3" ;
VAL_ 1424 KY_KYL_Prio_Warn_04 1 "Cluster Prio Warning Keyless 4" ;
VAL_ 1424 KY_KYL_Prio_Warn_05 1 "Cluster Prio Warning Keyless 5" ;
VAL_ 1424 KY_WFS_Safe 1 "WFS Not Deactivated" ;
VAL_ 1424 KY_WFS_LZ 0 "Not def." 1 "LZ 1" 2 "LZ 2" 3 "LZ 3" ;
VAL_ 1424 KY_StartStop_Info 0 "EngineRunning_Not_Necessary_(StopEnable)" 1 "EngineStartUp_Not_Mandatory_Necessary_(StopInhibit,No_StartRequest)" 2 "EngineStartUp_Mandatory_Necessary_(StartRequest)" 3 "SystemError" ;
VAL_ 1424 KYL_Notzuendschloss 0 "Not_Fitted" 1 "Fitted" ;
VAL_ 1424 KYL_Warn_Notzuendschloss 0 "Off" 1 "On" ;
VAL_ 1424 FBS_KD_Error 0 "No_KD_Error" 1 "KD_Error" ;
VAL_ 960 ZV_Locked_External_Target_02 1 "Fahrzeug verriegelt extern; Sollzusstand" ;
VAL_ 960 ZAS_Term_S 0 "Off" 1 "S_Contact_On" ;
VAL_ 960 ZAS_Term_15 0 "Off" 1 "On" ;
VAL_ 960 ZAS_Term_X 0 "Off" 1 "On" ;
VAL_ 960 ZAS_Term_50 0 "Off" 1 "TERM50_On_Startwunsch_Driver" ;
VAL_ 959 TERM_Rpm_Trailer 0 "No_Raise" 1 "RpmIncrease_From_Engine_Requested" ;
VAL_ 959 TERM_PreWarn_Compressor_On 1 "PreWarning Compressor On" ;
VAL_ 959 TERM_Handshake_BEM 0 "No_Leistungsaenderung_in_The_Heizsystemen_Active" 1 "Heizleistungsaenderung_Is_Straight_Performed" ;
VAL_ 959 TERM_Compressor_Torque_Old 1 "Outdated_bzw_Ermittlung_Of_Moments_Not_Possible__zB_No_Rpm_No_RefrigerantPressure" ;
VAL_ 959 TERM_PreWarn_HHS_On 1 "PreWarning_RearWindowHeating_On" ;
VAL_ 959 TERM_PreWarn_HFS_On 1 "PreWarning_WindscreenHeating_On" ;
VAL_ 959 TERM_PreWarn_AuxHeater_On 1 "PreWarning_AuxHeater_On" ;
VAL_ 959 TERM_KD_Error 0 "No_KD_Error" 1 "KD_Error" ;
VAL_ 959 TERM_Comp_rev_rq 255 "Error" ;
VAL_ 959 TERM_Charisma_DrivePr 0 "Not_Occupied" 1 "Programm_1" 2 "Programm_2" 3 "Programm_3" 4 "Programm_4" 5 "Programm_5" 6 "Programm_6" 7 "Programm_7" ;
VAL_ 959 TERM_Charisma_Status 0 "Init" 1 "Available" 2 "Not_Available" 3 "Asynchronous_By_DriverDemand" ;
VAL_ 959 TERM_Charisma_Changeover 0 "Idle" 1 "Detection_ChangeoverPrompt" 2 "ControlMessage_Not_Defined" 3 "Changeover_Delayed" ;
VAL_ 959 TERM_Load_Compressor 255 "Error" ;
VAL_ 959 TERM_Req_TERM 255 "Error" ;
VAL_ 959 TERM_4_Zones 0 "2_Zones_AirCon" 1 "4_Zones_AirCon" ;
VAL_ 959 TERM_AC_Switch 0 "Off" 1 "On" ;
VAL_ 959 TERM_State 0 "Off" 1 "On" ;
VAL_ 959 TERM_ThermalManagement 0 "No_Enable_TMM__max_HeatDemand" 1 "Small_Enable_TMM" 2 "Average_Enable_TMM" 3 "Full_Enable_TMM__No_HeatDemand" ;
VAL_ 959 TERM_Comp_enable 0 "Disable" 1 "Enable" ;
VAL_ 959 TERM_StartStop_Info 0 "EngineRunning_Not_Necessary_(StopEnable)" 1 "EngineStartUp_Not_Mandatory_Necessary_(StopInhibit,No_StartRequest)" 2 "EngineStartUp_Mandatory_Necessary_(StartRequest)" 3 "SystemError" ;
VAL_ 959 TERM_Diag_Absperrvent 0 "No_Error" 1 "KS-" 2 "KS+" 3 "OC" 4 "OOR+" 5 "OOR-" 6 "RC+" 7 "RC-" 8 "KS+/OC" 9 "KS-/OC" 10 "KS-/KS+" 11 "KS-/KS+/OC" ;
VAL_ 779 KBI_ABS_Lamp 0 "ABS Lamp Off" 1 "ABS Lamp On" ;
VAL_ 779 KBI_ESP_Lamp 0 "ESP Lamp Off" 1 "ESP Lamp On" ;
VAL_ 779 KBI_BKL_Lamp 0 "BKL Off" 1 "BKL On" ;
VAL_ 779 KBI_Airbag_Lamp 0 "Airbag Lamp Off" 1 "Airbag Lamp On" ;
VAL_ 779 KBI_SILA_Valid 0 "Invalid" 1 "Valid" ;
VAL_ 779 KBI_Preheat_System_Lamp 0 "Lamp Off" 1 "Lamp On" ;
VAL_ 779 KBI_NV_in_Display 0 "NV_Not_in_Display" 1 "NV_in_Display" ;
VAL_ 779 KBI_DisplayStatus_ACC 0 "No_ACC_Display" 1 "ACC_Display_Active" ;
VAL_ 779 KBI_LowFuelWarning 0 "Lamp Off" 1 "Lamp On" ;
VAL_ 779 KBI_MFA_v_Unit_01 0 "kmh" 1 "mph" ;
VAL_ 779 KBI_In_ActuatorTest 0 "No ActuatorTest" 1 "Cluster In ActuatorTest" ;
VAL_ 779 KBI_DisplayFault_LDW 0 "Not Present bzw. unterst�tzt" 1 "Display iO" 2 "DisplayFault" 3 "Not Defined" ;
VAL_ 779 KBI_Variant_USA 0 "No USA-Variant" 1 "USA-Variant" ;
VAL_ 779 KBI_OilPressureWarning 0 "Inactive" 1 "Active" ;
VAL_ 779 KBI_Handbrake 0 "Not_angezogen" 1 "angezogen" ;
VAL_ 779 KBI_PLA_in_Display 0 "PLA_Not_in_Display" 1 "PLA_in_Display" ;
VAL_ 779 KBI_DisplayFault_NV 0 "No_DisplayFault" 1 "DisplayFault" ;
VAL_ 779 KBI_Unit_Speedo 0 "km/h" 1 "mph" ;
VAL_ 779 KBI_Consistency_ACC 0 "ACC Message Consistent" 1 "ACC Message inkonsistent    " ;
VAL_ 779 KBI_Error_Display_ACC 0 " iO" 1 "DisplayFault ACC" ;
VAL_ 779 KBI_DisplayFault_SWA 0 "Not Present bzw. unterst�tzt" 1 "Display iO" 2 "DisplayFault" 3 "Not Defined" ;
VAL_ 779 KBI_KD_Error 0 "No_KD_Error" 1 "KD_Error" ;
VAL_ 1719 KBI_Odometer 1048574 "Init" 1048575 "Error" ;
VAL_ 1719 KBI_Reset_ParkedTime 0 "ParkedTime iO" 1 "TERM30 Was Distance" ;
VAL_ 1719 KBI_Contents_Tank 127 "Error" ;
VAL_ 1719 KBI_FStatus_Tank 0 "Tankf�llstand i.O." 1 "Tankf�llstand n.i.O" ;
VAL_ 1719 KBI_QBit_Outside_Temp_Filt 0 "Valid_Value" 1 "Substitute_Init_Or_ErrorValue" ;
VAL_ 1719 KBI_Outside_Temp_Filt 253 "Not Fitted" 254 "Init" 255 "Error" ;
VAL_ 1720 WFS_Key_DriveAuthorisation 0 "No Authorised Key Detected " 1 "Active_RemoteKey_Nr_01" 2 "Active_RemoteKey_Nr_02" 3 "Active_RemoteKey_Nr_03" 4 "Active_RemoteKey_Nr_04" 5 "Active_RemoteKey_Nr_05" 6 "Active_RemoteKey_Nr_06" 7 "Active_RemoteKey_Nr_07" 8 "Active_RemoteKey_Nr_08" 9 "Invalid_09" 10 "Invalid_10" 11 "Invalid_11" 12 "Invalid_12" 13 "Invalid_13" 14 "Invalid_14" 15 "Invalid_15" ;
VAL_ 1720 KBI_BCmE_Active 0 "Display_Not_Active" 1 "Display_Active" ;
VAL_ 1720 KBI_Sparhinweis_Acknowledged 0 "Not_Acknowledged" 1 "Acknowledged" ;
VAL_ 285 EPS_LimpHome 0 "No_LimpHome" 1 "LimpHome_Undervoltage" 2 "LimpHome_Overvoltage" 3 "Reserved" 4 "LimpHome_Overtemperature" 5 "LimpHome_Undervoltage_And_Overtemperature" 6 "LimpHome_Overvoltage_And_Overtemperature" 7 "Reserved" 8 "Reserved" 9 "Reserved" 10 "Reserved" 11 "Reserved" 12 "Reserved" 13 "Reserved" 14 "Reserved" 15 "Reserved" ;
VAL_ 285 EPS_LoadInfo 255 "Error" ;
VAL_ 285 EPS_Unterstuetzungsleistung 255 "Error" ;
VAL_ 285 EPS_RpmReserve 127 "Error" ;
VAL_ 285 EPS_VZ_RpmReserve 0 "Positive" 1 "Negative" ;
VAL_ 285 EPS_PowerRequest 0 "No_Request" 1 "Request_hoehere_Voltage_Or_Power" ;
VAL_ 1137 BCM2_BrakeLight_By_ECD 0 "BrakeLight_Actual_Off" 1 "BrakeLight_By_ECD_Active" ;
VAL_ 1137 LH_OutsideLight_def 0 "OK" 1 "Defective" ;
VAL_ 1137 LH_SideLight_H_Active 1 "SideLight Rear Active" ;
VAL_ 1137 LH_ParkingLight_HL_Active 0 "Not Active" 1 "ParkingLight Rear Left Active" ;
VAL_ 1137 LH_ParkingLight_HR_Active 0 "Not Active" 1 "ParkingLight Rear Right Active" ;
VAL_ 1137 LH_BrakeLight_H_Active 1 "BrakeLight Rear Active" ;
VAL_ 1137 LH_RearFog_Active 0 "Not Active" 1 "Active" ;
VAL_ 1137 LH_ReversingLight_Active 0 "Not Active" 1 "Active" ;
VAL_ 1137 LH_Indicator_HL_Act 1 "Indicator Rear Left Active" ;
VAL_ 1137 LH_Indicator_HR_Act 1 "Indicator Rear Right Active" ;
VAL_ 1137 LH_Indicator_Left_def 0 "OK" 1 "Indicator Rear Left Defective" ;
VAL_ 1137 LH_BrakeLight_Left_def 0 "OK" 1 "AtLeast On BrakeLight Rear Left Defective" ;
VAL_ 1137 LH_TailLight_Left_def 0 "OK" 1 "AtLeast On TailLight Rear Left Defective" ;
VAL_ 1137 LH_Reverse_Left_def 0 "OK" 1 "R�ckfahrlicht Rear Left Defective" ;
VAL_ 1137 LH_Fog_Left_def 0 "OK" 1 " RearFogLight Rear Left Defective" ;
VAL_ 1137 LH_End_Brake_Fog_Left_def 0 "iO" 1 "Defective" ;
VAL_ 1137 LH_End_Brake_Fog_Right_def 0 "iO" 1 "Defective" ;
VAL_ 1137 LH_End_Brake_Left_def 0 "OK" 1 "Defective" ;
VAL_ 1137 LH_End_Fog_Left_def 0 "OK" 1 "Defective" ;
VAL_ 1137 LH_SL_BRL_BLK_Left_def 0 "OK" 1 "Defective" ;
VAL_ 1137 LH_Brake_Blk_Left_def 0 "OK" 1 "Defective" ;
VAL_ 1137 LH_Indicator_Right_def 0 "OK" 1 "Indicator Rear Right Defective" ;
VAL_ 1137 LH_BrakeLight_Right_def 0 "OK" 1 "AtLeast On BrakeLight Rear Right Defective" ;
VAL_ 1137 LH_TailLight_Right_def 0 "OK" 1 "AtLeast On TailLight Rear Right Defective" ;
VAL_ 1137 LH_Reverse_Right_def 0 "OK" 1 "R�ckfahrlicht Rear Right Defective" ;
VAL_ 1137 LH_Fog_Right_def 0 "OK" 1 "RearFogLight Rear Right Defective" ;
VAL_ 1137 LH_End_Brake_Right_def 0 "OK" 1 "Defective" ;
VAL_ 1137 LH_End_Fog_Right_def 0 "OK" 1 "Defective" ;
VAL_ 1137 LH_SL_BRL_BLK_Right_def 0 "OK" 1 "Defective" ;
VAL_ 1137 LH_Brake_Blk_Right_def 0 "OK" 1 "Defective" ;
VAL_ 1137 LH_Kennzl_def 0 "OK" 1 "Kennzeichenbeleuchtung Rear Defective" ;
VAL_ 1137 LH_3_BrakeLight_def 0 "OK" 1 "HighSet  BrakeLight Defective" ;
VAL_ 1137 LH_Fog_mi_def 0 "OK" 1 " RearFogLight Rear Centre Defective" ;
VAL_ 1137 LH_Reverse_mi_def 0 "OK" 1 "R�ckfahllicht Centre Defective" ;
VAL_ 1137 LH_BrakeLight_Left_Total_def 0 "OK" 1 "All BrakeLights Rear Left Defective" ;
VAL_ 1137 LH_BrakeLight_Right_Total_def 0 "OK" 1 "All BrakeLights Rear Right Defective" ;
VAL_ 267 LS_MainSwitch 0 "Gerastet Off" 1 "On" ;
VAL_ 267 LS_Cancel 0 "TipSwitch Not Pressed" 1 "TipSwitch Pressed" ;
VAL_ 267 LS_Type_MainSwitch 0 "gerasteter_StalkSwitch" 1 "getasteter_StalkSwitch" ;
VAL_ 267 LS_Limiter 0 "Limiter Off" 1 "Limiter On" ;
VAL_ 267 LS_Tip_Set 0 "TipSwitch Not Pressed" 1 "TipSwitch Pressed" ;
VAL_ 267 LS_Tip_High 0 "TipSwitch Not Pressed" 1 "TipSwitch Pressed" ;
VAL_ 267 LS_Tip_Down 0 "TipSwitch Not Pressed" 1 "TipSwitch Pressed" ;
VAL_ 267 LS_Tip_Resume 0 "TipSwitch Not Pressed" 1 "TipSwitch Pressed" ;
VAL_ 267 LS_Adjustment_TimeGap 0 "Key Not Pressed" 1 "Dist -1" 2 "Dist +1" 3 "Not Occupied" ;
VAL_ 267 MFL_Tip_Down 0 "Not_Pressed" 1 "Pressed" ;
VAL_ 267 MFL_Tip_Up 0 "Not_Pressed" 1 "Pressed" ;
VAL_ 267 LS_Tiptronic_Error 0 " i. O." 1 "Error Detected" ;
VAL_ 267 LS_Coding 0 "No Lever, No Tiptronic At SteeringWheel" 1 "No Lever, Tiptronic At SteeringWheel" 2 "GRA Lever, No Tiptronic At SteeringWheel" 3 "GRA Lever, Tiptronic At SteeringWheel" 4 "ACC Lever, No Tiptronic At SteeringWheel" 5 "ACC Lever, Tiptronic At SteeringWheel" 6 "Not Used" 7 "Not Used" ;
VAL_ 267 LS_Tip_Stage_2 0 "LeverActuation_in_First_TipStage__No_LeverActuation" 1 "LeverActuation_in_The_zweiten_TipStage" ;
VAL_ 267 LS_GRA_ACC_2stufig 0 "No_zweistufiger_Lever_Fitted" 1 "zweistufiger_Lever_Fitted" ;
VAL_ 267 MFL_M_Key 0 "Not_Pressed" 1 "Pressed" ;
CM_ SG_ 265 ACC_Allowed_ControlDeviation_Bottom "[DE: ACC_zul_Regelabw_unten]";
CM_ SG_ 265 ACC_TargetAcceleration "[DE: ACC_Sollbeschleunigung]";
CM_ SG_ 265 ACC_Allowed_ControlDeviation_Top "[DE: ACC_zul_Regelabw_oben]";
CM_ SG_ 265 ACC_Neg_TargetAccel_Degree "[DE: ACC_neg_Sollbeschl_Grad]";
CM_ SG_ 265 ACC_pos_TargetAccel_Degree "[DE: ACC_pos_Sollbeschl_Grad]";
CM_ SG_ 265 ACC_Dynamics "[DE: ACC_Dynamik]";
CM_ SG_ 265 ACC_Stop "[DE: ACC_Anhalten]";
CM_ SG_ 265 ACC_Minimum_Braking "[DE: ACC_Minimale_Bremsung]";
CM_ SG_ 780 ACC_SetSpeed_02 "[DE: ACC_Wunschgeschw_02]";
CM_ SG_ 780 ACC_Status_Prim_Disp "[DE: ACC_Status_Prim_Anz]";
CM_ SG_ 780 ACC_DistanceIndex "[DE: ACC_Abstandsindex]";
CM_ SG_ 780 ACC_Acoustic "[DE: ACC_Akustik]";
CM_ SG_ 780 ACC_Set_TimeGap "[DE: ACC_Gesetzte_Zeitluecke]";
CM_ SG_ 780 ACC_Optical_DriverNotice "[DE: ACC_Optischer_Fahrerhinweis]";
CM_ SG_ 780 ACC_Type_SpeedoScale "[DE: ACC_Typ_Tachokranz]";
CM_ SG_ 780 ACC_Display_TimeGap "[DE: ACC_Anzeige_Zeitluecke]";
CM_ SG_ 780 ACC_SpeedoScale "[DE: ACC_Tachokranz]";
CM_ SG_ 780 ACC_Relevant_Object "[DE: ACC_Relevantes_Objekt]";
CM_ SG_ 780 ACC_Texte_PrimaryDisplay "[DE: ACC_Texte_Primaeranz]";
CM_ SG_ 780 ACC_SetSpeed_Reached "[DE: ACC_Wunschgeschw_erreicht]";
CM_ SG_ 780 ACC_Status_Display "[DE: ACC_Status_Anzeige]";
CM_ SG_ 804 ACC_Texte_AuxDisplay "[DE: ACC_Texte_Zusatzanz]";
CM_ SG_ 804 ACC_Status_AuxDisplay "[DE: ACC_Status_Zusatzanz]";
CM_ SG_ 804 ACC_WarningNote "[DE: ACC_Warnhinweis]";
CM_ SG_ 804 ACC_Speed_TargetVehicle "[DE: ACC_Geschw_Zielfahrzeug]";
CM_ SG_ 804 ACC_Charisma_DrivePr "[DE: ACC_Charisma_FahrPr]";
CM_ SG_ 804 ACC_Charisma_Changeover "[DE: ACC_Charisma_Umschaltung]";
CM_ SG_ 269 ACC_Enable_TorqueReq "[DE: ACC_Freigabe_Momentenanf]";
CM_ SG_ 269 ACC_Enable_DecelReq "[DE: ACC_Freigabe_Verzanf]";
CM_ SG_ 269 ACC_GearboxPosition_P "[DE: ACC_Getriebestellung_P]";
CM_ SG_ 269 ACC_Limited_PullAwayDyn "[DE: ACC_limitierte_Anfahrdyn]";
CM_ SG_ 269 ACC_TorqueRequest "[DE: ACC_Momentenanforderung]";
CM_ SG_ 269 ACC_Allowed_ControlDeviation "[DE: ACC_zul_Regelabw]";
CM_ SG_ 269 ACC_Decel_Req "[DE: ACC_Verz_anf]";
CM_ SG_ 269 ACC_StartStop_Info "[DE: ACC_StartStopp_Info]";
CM_ SG_ 269 ACC_Vorbefuellung_BrakeSystem "[DE: ACC_Vorbefuellung_Bremsanlage]";
CM_ SG_ 269 ACC_ax_Gearbox "[DE: ACC_ax_Getriebe]";
CM_ SG_ 269 ACC_Actuation_EPB "[DE: ACC_Betaetigung_EPB]";
CM_ SG_ 269 ACC_Influence_ESP "[DE: ACC_Beeinflussung_ESP]";
CM_ SG_ 269 ACC_Stop "[DE: ACC_Anhalten]";
CM_ SG_ 269 ACC_KD_Error "[DE: ACC_KD_Fehler]";
CM_ SG_ 279 AWV1_Req_Prefill "[DE: AWV1_Anf_Prefill]";
CM_ SG_ 279 AWV2_Enable "[DE: AWV2_Freigabe]";
CM_ SG_ 279 AWV2_JerkProfile "[DE: AWV2_Ruckprofil]";
CM_ SG_ 279 AWV2_PrioWarning "[DE: AWV2_Priowarnung]";
CM_ SG_ 279 ANB_CM_Request "[DE: ANB_CM_Anforderung]";
CM_ SG_ 279 ANB_Info_PartialBraking "[DE: ANB_Info_Teilbremsung]";
CM_ SG_ 279 ANB_EmergencyFlash "[DE: ANB_Notfallblinken]";
CM_ SG_ 279 ANB_PartialBraking_Enable "[DE: ANB_Teilbremsung_Freigabe]";
CM_ SG_ 279 ANB_TargetBrake_Teilbrems_Decel_Req "[DE: ANB_Zielbrems_Teilbrems_Verz_Anf]";
CM_ SG_ 279 ANB_TargetBraking_Enable "[DE: ANB_Zielbremsung_Freigabe]";
CM_ SG_ 279 AWV_BeforeStage "[DE: AWV_Vorstufe]";
CM_ SG_ 279 AWV_Hold "[DE: AWV_Halten]";
CM_ SG_ 279 AWV_CityANB_Variant "[DE: AWV_CityANB_Auspraegung]";
CM_ SG_ 279 PCF_Enable "[DE: PCF_Freigabe]";
CM_ SG_ 279 AWV1_ECD_StartUp "[DE: AWV1_ECD_Anlauf]";
CM_ SG_ 279 AWV_AWA_VZ_Req_Lenkmomoffset "[DE: AWV_AWA_VZ_Anf_Lenkmomoffset]";
CM_ SG_ 279 AWV_AWA_Req_Lenkmomoffset "[DE: AWV_AWA_Anf_Lenkmomoffset]";
CM_ SG_ 64 FROM_RGS_Anst "[DE: AB_RGS_Anst]";
CM_ SG_ 64 FROM_Front_Crash "[DE: AB_Front_Crash]";
CM_ SG_ 64 FROM_Rear_Crash "[DE: AB_Heck_Crash]";
CM_ SG_ 64 FROM_SF_Crash "[DE: AB_SF_Crash]";
CM_ SG_ 64 FROM_SB_Crash "[DE: AB_SB_Crash]";
CM_ SG_ 64 FROM_Rollover_Crash "[DE: AB_Rollover_Crash]";
CM_ SG_ 64 FROM_Crash_Int "[DE: AB_Crash_Int]";
CM_ SG_ 64 FROM_Lamp "[DE: AB_Lampe]";
CM_ SG_ 64 FROM_Deactivated "[DE: AB_Deaktiviert]";
CM_ SG_ 64 FROM_VB_Deactivated "[DE: AB_VB_deaktiviert]";
CM_ SG_ 64 FROM_SystemError "[DE: AB_Systemfehler]";
CM_ SG_ 64 FROM_Diagnostics "[DE: AB_Diagnose]";
CM_ SG_ 64 FROM_ActuatorTest "[DE: AB_Stellgliedtest]";
CM_ SG_ 64 FROM_Erh_Open_VB "[DE: AB_Erh_Auf_VB]";
CM_ SG_ 64 FROM_BeltWarn_VF "[DE: AB_Gurtwarn_VF]";
CM_ SG_ 64 FROM_BeltWarn_VB "[DE: AB_Gurtwarn_VB]";
CM_ SG_ 64 FROM_Display_Pedestrian "[DE: AB_Anzeige_Fussg]";
CM_ SG_ 64 FROM_Texte_AKS "[DE: AB_Texte_AKS]";
CM_ SG_ 64 FROM_PAO_Lamp_Req "[DE: AB_PAO_Leuchte_Anf]";
CM_ SG_ 64 FROM_MKB_Valid "[DE: AB_MKB_gueltig]";
CM_ SG_ 64 FROM_MKB_Request "[DE: AB_MKB_Anforderung]";
CM_ SG_ 64 FROM_SupplyVoltage "[DE: AB_Versorgungsspannung]";
CM_ SG_ 64 FROM_KD_Error "[DE: AB_KD_Fehler]";
CM_ SG_ 1312 FROM_Occupancy_VB "[DE: AB_Belegung_VB]";
CM_ SG_ 1312 FROM_BeltBuckle_FA "[DE: AB_Gurtschloss_FA]";
CM_ SG_ 1312 FROM_BeltBuckle_BF "[DE: AB_Gurtschloss_BF]";
CM_ SG_ 1312 FROM_BeltBuckle_Row2_FA "[DE: AB_Gurtschloss_Reihe2_FA]";
CM_ SG_ 1312 FROM_BeltBuckle_Row2_MI "[DE: AB_Gurtschloss_Reihe2_MI]";
CM_ SG_ 1312 FROM_BeltBuckle_Row2_BF "[DE: AB_Gurtschloss_Reihe2_BF]";
CM_ SG_ 1312 FROM_BeltBuckle_Row3_FA "[DE: AB_Gurtschloss_Reihe3_FA]";
CM_ SG_ 1312 FROM_BeltBuckle_Row3_MI "[DE: AB_Gurtschloss_Reihe3_MI]";
CM_ SG_ 1312 FROM_BeltBuckle_Row3_BF "[DE: AB_Gurtschloss_Reihe3_BF]";
CM_ SG_ 1312 FROM_SeatPos_Sens_FA "[DE: AB_Sitzpos_Sens_FA]";
CM_ SG_ 1312 FROM_SeatPos_Sens_BF "[DE: AB_Sitzpos_Sens_BF]";
CM_ SG_ 1633 AAG_BrakeLight_By_ECD "[DE: AAG_Bremsl_durch_ECD]";
CM_ SG_ 1633 AAG_Trailer_Unplugged "[DE: AAG_Anhaenger_abgesteckt]";
CM_ SG_ 1633 AAG_NSL_Active "[DE: AAG_NSL_aktiv]";
CM_ SG_ 1633 AAG_Trailer_Detected "[DE: AAG_Anhaenger_erkannt]";
CM_ SG_ 1633 AAG_Indicator_H_Active "[DE: AAG_Blinker_H_aktiv]";
CM_ SG_ 1633 AAG_Indicator_HL_def "[DE: AAG_Blinker_HL_def]";
CM_ SG_ 1633 AAG_Indicator_HR_def "[DE: AAG_Blinker_HR_def]";
CM_ SG_ 1633 AAG_BrakeLight_H_def "[DE: AAG_Bremslicht_H_def]";
CM_ SG_ 1633 AAG_TailLight_HL_def "[DE: AAG_Schlusslicht_HL_def]";
CM_ SG_ 1633 AAG_TailLight_HR_def "[DE: AAG_Schlusslicht_HR_def]";
CM_ SG_ 1633 AAG_KD_Error "[DE: AAG_KD_Fehler]";
CM_ SG_ 1633 AAG_AVS_Error "[DE: AAG_AVS_Fehler]";
CM_ SG_ 1633 AAG_AVS_Statuses "[DE: AAG_AVS_Stati]";
CM_ SG_ 777 BEM_Coast_Info "[DE: BEM_Segel_Info]";
CM_ SG_ 777 BEM_P_Alternator "[DE: BEM_P_Generator]";
CM_ SG_ 777 BEM_01_ShutoffStages "[DE: BEM_01_Abschaltstufen]";
CM_ SG_ 777 BEM_Req_TERM "[DE: BEM_Anf_KL]";
CM_ SG_ 777 BEM_StartStop_Info "[DE: BEM_StartStopp_Info]";
CM_ SG_ 867 BM_ZV_Open "[DE: BM_ZV_auf]";
CM_ SG_ 867 BM_ZV_Closed "[DE: BM_ZV_zu]";
CM_ SG_ 867 BM_DWA_On "[DE: BM_DWA_ein]";
CM_ SG_ 867 BM_Panic "[DE: BM_Panik]";
CM_ SG_ 867 BM_Not_Braking "[DE: BM_Not_Bremsung]";
CM_ SG_ 867 BM_Left "[DE: BM_links]";
CM_ SG_ 867 BM_Right "[DE: BM_rechts]";
CM_ SG_ 867 BM_HazardFlash "[DE: BM_Warnblinken]";
CM_ SG_ 867 BM_Motorway "[DE: BM_Autobahn]";
CM_ SG_ 867 BM_Telematics "[DE: BM_Telematik]";
CM_ SG_ 867 BM_HD_Opening_angelernt "[DE: BM_HD_Oeffnung_angelernt]";
CM_ SG_ 867 BM_WBT_Lighting "[DE: BM_WBT_Beleuchtung]";
CM_ SG_ 867 Flash_Left_Veh_Clock "[DE: Blinken_li_Fzg_Takt]";
CM_ SG_ 867 Flash_Right_Veh_Clock "[DE: Blinken_re_Fzg_Takt]";
CM_ SG_ 867 Flash_Left_Cluster_Clock "[DE: Blinken_li_Kombi_Takt]";
CM_ SG_ 867 Flash_Right_Cluster_Clock "[DE: Blinken_re_Kombi_Takt]";
CM_ SG_ 867 BM_NBA_n_Coded_n_Active "[DE: BM_NBA_n_codiert_n_aktiv]";
CM_ SG_ 867 Flash_FWB_Active "[DE: Blinken_FWB_aktiv]";
CM_ SG_ 490 CCP_GE_Ditto_01_Data "[DE: CCP_GE_DTO_01_Data]";
CM_ SG_ 488 CCP_MO_Ditto_01_Data "[DE: CCP_MO_DTO_01_Data]";
CM_ SG_ 2616986625 CCP_MO_Ditto_02_Data "[DE: CCP_MO_DTO_02_Data]";
CM_ SG_ 489 CCP_MOS_Ditto_01_Data "[DE: CCP_MOS_DTO_01_Data]";
CM_ SG_ 2616986630 CCP_MOS_Ditto_02_Data "[DE: CCP_MOS_DTO_02_Data]";
CM_ SG_ 2617042432 CCP_SoundActuator_CRO_01_Data "[DE: CCP_Soundaktor_CRO_01_Data]";
CM_ SG_ 2617042433 CCP_SoundActuator_Ditto_01_Data "[DE: CCP_Soundaktor_DTO_01_Data]";
CM_ SG_ 901 CHA_SystemStatus "[DE: CHA_Systemstatus]";
CM_ SG_ 901 CHA_Driver_Changeover "[DE: CHA_Fahrer_Umschaltung]";
CM_ SG_ 901 CHA_Target_DrivePr_MO "[DE: CHA_Ziel_FahrPr_MO]";
CM_ SG_ 901 CHA_Target_DrivePr_GE "[DE: CHA_Ziel_FahrPr_GE]";
CM_ SG_ 901 CHA_Target_DrivePr_ST "[DE: CHA_Ziel_FahrPr_ST]";
CM_ SG_ 901 CHA_Target_DrivePr_SCU "[DE: CHA_Ziel_FahrPr_SCU]";
CM_ SG_ 901 CHA_Target_DrivePr_DR "[DE: CHA_Ziel_FahrPr_DR]";
CM_ SG_ 901 CHA_Target_DrivePr_QS "[DE: CHA_Ziel_FahrPr_QS]";
CM_ SG_ 901 CHA_Target_DrivePr_AFS "[DE: CHA_Ziel_FahrPr_AFS]";
CM_ SG_ 901 CHA_Target_DrivePr_RGS "[DE: CHA_Ziel_FahrPr_RGS]";
CM_ SG_ 901 CHA_Target_DrivePr_EPS "[DE: CHA_Ziel_FahrPr_EPS]";
CM_ SG_ 901 CHA_Target_DrivePr_ACC "[DE: CHA_Ziel_FahrPr_ACC]";
CM_ SG_ 901 CHA_Target_DrivePr_SAK "[DE: CHA_Ziel_FahrPr_SAK]";
CM_ SG_ 1714 DGN_UnlearnCounter "[DE: DGN_Verlernzaehler]";
CM_ SG_ 1714 KBI_Odometer "[DE: KBI_Kilometerstand]";
CM_ SG_ 1714 UH_Year "[DE: UH_Jahr]";
CM_ SG_ 1714 UH_Month "[DE: UH_Monat]";
CM_ SG_ 1714 UH_Hour "[DE: UH_Stunde]";
CM_ SG_ 1714 UH_Second "[DE: UH_Sekunde]";
CM_ SG_ 1714 Cluster_02_Old "[DE: Kombi_02_alt]";
CM_ SG_ 1714 ClockTime_01_Old "[DE: Uhrzeit_01_alt]";
CM_ SG_ 1520 DI_TERM_58d "[DE: DI_KL_58d]";
CM_ SG_ 1520 DI_TERM_58s "[DE: DI_KL_58s]";
CM_ SG_ 1520 DI_TERM_58St "[DE: DI_KL_58st]";
CM_ SG_ 1603 KBI_Unit_Date "[DE: KBI_Einheit_Datum]";
CM_ SG_ 1603 KBI_Unit_Pressure "[DE: KBI_Einheit_Druck]";
CM_ SG_ 1603 KBI_Unit_Streckenanz "[DE: KBI_Einheit_Streckenanz]";
CM_ SG_ 1603 KBI_MFA_v_Unit_02 "[DE: KBI_MFA_v_Einheit_02]";
CM_ SG_ 1603 KBI_Unit_Temp "[DE: KBI_Einheit_Temp]";
CM_ SG_ 1603 KBI_Unit_ClockTime "[DE: KBI_Einheit_Uhrzeit]";
CM_ SG_ 1603 KBI_Unit_Consumption "[DE: KBI_Einheit_Verbrauch]";
CM_ SG_ 1603 KBI_Unit_Volume "[DE: KBI_Einheit_Volumen]";
CM_ SG_ 1603 KBI_Unit_Language "[DE: KBI_Einheit_Sprache]";
CM_ SG_ 260 EPB_QBit_LongAccel "[DE: EPB_QBit_Laengsbeschleunigung]";
CM_ SG_ 260 EPB_QBit_PedalTravel_Clutch "[DE: EPB_QBit_Pedalweg_Kuppl]";
CM_ SG_ 260 EPB_BCM2_Engine_Wakeup "[DE: EPB_BCM2_Motor_Wakeup]";
CM_ SG_ 260 EPB_Enable_Decel_Req "[DE: EPB_Freig_Verzoeg_Anf]";
CM_ SG_ 260 EPB_Decel_Req "[DE: EPB_Verzoeg_Anf]";
CM_ SG_ 260 EPB_LongAccel "[DE: EPB_Laengsbeschleunigung]";
CM_ SG_ 260 EPB_PedalTravel_Clutch "[DE: EPB_Pedalweg_Kuppl]";
CM_ SG_ 260 EPB_PullAwayRequest_Detected "[DE: EPB_Anfahrwunsch_erkannt]";
CM_ SG_ 260 EPB_DAA_BoundaryCond_erf "[DE: EPB_DAA_Randbed_erf]";
CM_ SG_ 260 EPB_ErrorStatus "[DE: EPB_Fehlerstatus]";
CM_ SG_ 260 EPB_Consistency_ACC "[DE: EPB_Konsistenz_ACC]";
CM_ SG_ 260 EPB_ClampForce "[DE: EPB_Spannkraft]";
CM_ SG_ 260 EPB_KD_Error "[DE: EPB_KD_Fehler]";
CM_ SG_ 781 EPB_FaultLamp_Yellow "[DE: EPB_Fehlerlampe_Gelb]";
CM_ SG_ 781 EPB_FaultLamp_BKL "[DE: EPB_Fehlerlampe_BKL]";
CM_ SG_ 781 EPB_FunctionLamp "[DE: EPB_Funktionslampe]";
CM_ SG_ 781 EPB_Acoustic "[DE: EPB_Akustik]";
CM_ SG_ 781 EPB_AutoHoldLamp "[DE: EPB_Autoholdlampe]";
CM_ SG_ 781 EPB_BrakePad_Warn "[DE: EPB_Bremsbelag_Warn]";
CM_ SG_ 256 ASR_Torque_Slow "[DE: ASR_Moment_langsam]";
CM_ SG_ 256 ASR_MSR_Torque_Fast "[DE: ASR_MSR_Moment_schnell]";
CM_ SG_ 256 ASR_Keying_Passive "[DE: ASR_Tastung_passiv]";
CM_ SG_ 256 ESP_Keying_Passive "[DE: ESP_Tastung_passiv]";
CM_ SG_ 256 ESP_SystemStatus "[DE: ESP_Systemstatus]";
CM_ SG_ 256 ASR_ShiftIntervention "[DE: ASR_Schalteingriff]";
CM_ SG_ 256 OBD_RoughRoad "[DE: OBD_Schlechtweg]";
CM_ SG_ 256 OBD_QBit_RoughRoad "[DE: OBD_QBit_Schlechtweg]";
CM_ SG_ 256 ABS_Braking "[DE: ABS_Bremsung]";
CM_ SG_ 256 ASR_Req "[DE: ASR_Anf]";
CM_ SG_ 256 MSR_Req "[DE: MSR_Anf]";
CM_ SG_ 256 EBV_Intervention "[DE: EBV_Eingriff]";
CM_ SG_ 256 EDS_Intervention "[DE: EDS_Eingriff]";
CM_ SG_ 256 ESP_Intervention "[DE: ESP_Eingriff]";
CM_ SG_ 256 ESP_KD_Error "[DE: ESP_KD_Fehler]";
CM_ SG_ 257 ESP_QBit_YawRate "[DE: ESP_QBit_Gierrate]";
CM_ SG_ 257 ESP_QBit_LongAccel "[DE: ESP_QBit_Laengsbeschl]";
CM_ SG_ 257 ESP_QBit_LatAccel "[DE: ESP_QBit_Querb]";
CM_ SG_ 257 ESP_LateralAccel "[DE: ESP_Querbeschleunigung]";
CM_ SG_ 257 ESP_LongAccel "[DE: ESP_Laengsbeschl]";
CM_ SG_ 257 ESP_Verteil_RollTorque "[DE: ESP_Verteil_Wankmom]";
CM_ SG_ 257 ESP_QBit_Req_Vert_Roll "[DE: ESP_QBit_Anf_Vert_Wank]";
CM_ SG_ 257 ESP_YawRate "[DE: ESP_Gierrate]";
CM_ SG_ 257 ESP_VZ_YawRate "[DE: ESP_VZ_Gierrate]";
CM_ SG_ 257 ESP_VoltageReq "[DE: ESP_SpannungsAnf]";
CM_ SG_ 257 ESP_PLA_Abort "[DE: ESP_PLA_Abbruch]";
CM_ SG_ 259 ESP_VL_WheelSpeed "[DE: ESP_VL_Radgeschw]";
CM_ SG_ 259 ESP_VR_WheelSpeed "[DE: ESP_VR_Radgeschw]";
CM_ SG_ 259 ESP_HL_WheelSpeed "[DE: ESP_HL_Radgeschw]";
CM_ SG_ 259 ESP_HR_WheelSpeed "[DE: ESP_HR_Radgeschw]";
CM_ SG_ 776 ESP_HDC_FuncLamp "[DE: ESP_HDC_FktLampe]";
CM_ SG_ 776 ESP_Lamp "[DE: ESP_Lampe]";
CM_ SG_ 776 ABS_Lamp "[DE: ABS_Lampe]";
CM_ SG_ 776 BK_Lamp "[DE: BK_Lampe]";
CM_ SG_ 776 ESP_Acoustic "[DE: ESP_Akustik]";
CM_ SG_ 776 ESP_Diagnostics "[DE: ESP_Diagnose]";
CM_ SG_ 776 ESP_Off_Lamp "[DE: ESP_Off_Lampe]";
CM_ SG_ 776 ESP_m_WheelSpeed "[DE: ESP_m_Raddrehz]";
CM_ SG_ 776 ESP_ASR_Lamp "[DE: ESP_ASR_Lampe]";
CM_ SG_ 776 ESP_DistPulse_VA "[DE: ESP_Wegimp_VA]";
CM_ SG_ 776 ESP_ErrorStatus_DistPulse "[DE: ESP_Fehlerstatus_Wegimp]";
CM_ SG_ 776 ESP_DistPulse_Overflow "[DE: ESP_Wegimp_Ueberlauf]";
CM_ SG_ 776 ESP_QBit_DistPulse_VA "[DE: ESP_QBit_Wegimp_VA]";
CM_ SG_ 776 ESP_HDC_ControlSpeed "[DE: ESP_HDC_Regelgeschw]";
CM_ SG_ 776 ESP_BKV_Warning "[DE: ESP_BKV_Warnung]";
CM_ SG_ 776 ESP_ToothCount "[DE: ESP_Zaehnezahl]";
CM_ SG_ 262 ESP_QBit_BrakePressure "[DE: ESP_QBit_Bremsdruck]";
CM_ SG_ 262 ESP_QBit_Driver_Brakes "[DE: ESP_QBit_Fahrer_bremst]";
CM_ SG_ 262 ESP_Threshold_Vacuum "[DE: ESP_Schwelle_Unterdruck]";
CM_ SG_ 262 ESP_BrakePressure "[DE: ESP_Bremsdruck]";
CM_ SG_ 262 ESP_Driver_Brakes "[DE: ESP_Fahrer_bremst]";
CM_ SG_ 262 ESP_Decel_TSK_Active "[DE: ESP_Verz_TSK_aktiv]";
CM_ SG_ 262 ESP_SteeringIntervention_ADS "[DE: ESP_Lenkeingriff_ADS]";
CM_ SG_ 262 ESP_Consistency_TSK "[DE: ESP_Konsistenz_TSK]";
CM_ SG_ 262 ESP_BrakeJerk_AWV2 "[DE: ESP_Bremsruck_AWV2]";
CM_ SG_ 262 ESP_Consistency_AWV2 "[DE: ESP_Konsistenz_AWV2]";
CM_ SG_ 262 ECD_Error "[DE: ECD_Fehler]";
CM_ SG_ 262 ECD_Not_Available "[DE: ECD_nicht_verfuegbar]";
CM_ SG_ 262 ESP_Status_BrakesTemp "[DE: ESP_Status_Bremsentemp]";
CM_ SG_ 262 ESP_AutoHold_Standby "[DE: ESP_Autohold_Standby]";
CM_ SG_ 262 ESP_HBA_Active "[DE: ESP_HBA_aktiv]";
CM_ SG_ 262 ESP_Prefill_Triggered "[DE: ESP_Prefill_ausgeloest]";
CM_ SG_ 262 ESP_Reversing_Detected "[DE: ESP_Rueckwaertsfahrt_erkannt]";
CM_ SG_ 262 ESP_Status_HillStartAssist "[DE: ESP_Status_Anfahrhilfe]";
CM_ SG_ 262 ESP_HDC_Active "[DE: ESP_HDC_aktiv]";
CM_ SG_ 262 ESP_StartStop_Info "[DE: ESP_StartStopp_Info]";
CM_ SG_ 262 ESP_Interv_HL "[DE: ESP_Eingr_HL]";
CM_ SG_ 262 ESP_Interv_HR "[DE: ESP_Eingr_HR]";
CM_ SG_ 262 ESP_Interv_VL "[DE: ESP_Eingr_VL]";
CM_ SG_ 262 ESP_Interv_VR "[DE: ESP_Eingr_VR]";
CM_ SG_ 262 ESP_BKV_Vacuum "[DE: ESP_BKV_Unterdruck]";
CM_ SG_ 262 ESP_AutoHold_Active "[DE: ESP_Autohold_aktiv]";
CM_ SG_ 262 ESP_FStatus_HillStartAssist "[DE: ESP_FStatus_Anfahrhilfe]";
CM_ SG_ 262 ESP_Decel_EPB_Active "[DE: ESP_Verz_EPB_aktiv]";
CM_ SG_ 262 ECD_BrakeLight "[DE: ECD_Bremslicht]";
CM_ SG_ 262 ESP_Decel_EPB_Avail "[DE: ESP_Verzoeg_EPB_verf]";
CM_ SG_ 262 ESP_Status_BrakePressure "[DE: ESP_Status_Bremsdruck]";
CM_ SG_ 262 ESP_Request_EPB "[DE: ESP_Anforderung_EPB]";
CM_ SG_ 132 ESP_06_KD_Error "[DE: ESP_06_KD_Fehler]";
CM_ SG_ 132 ESP_AngleIntervention "[DE: ESP_Winkeleingriff]";
CM_ SG_ 914 ESP_Quattro_Drive "[DE: ESP_Quattro_Antrieb]";
CM_ SG_ 914 ESP_Coding_ADS "[DE: ESP_Codierung_ADS]";
CM_ SG_ 914 OBD_Error_WheelSensor_HL "[DE: OBD_Fehler_Radsensor_HL]";
CM_ SG_ 914 OBD_Error_WheelSensor_HR "[DE: OBD_Fehler_Radsensor_HR]";
CM_ SG_ 914 OBD_Error_WheelSensor_VL "[DE: OBD_Fehler_Radsensor_VL]";
CM_ SG_ 914 OBD_Error_WheelSensor_VR "[DE: OBD_Fehler_Radsensor_VR]";
CM_ SG_ 914 ESP_Qualification_DriveType "[DE: ESP_Qualifizierung_Antriebsart]";
CM_ SG_ 914 ESP_Offroad_Mode "[DE: ESP_Offroad_Modus]";
CM_ SG_ 914 ESP_CM_Variant "[DE: ESP_CM_Variante]";
CM_ SG_ 286 ESP_ANB_CM_Rueckk_Convert "[DE: ESP_ANB_CM_Rueckk_Umsetz]";
CM_ SG_ 286 ESP_Consistency_ACC_Message "[DE: ESP_Konsistenz_ACC_Botschaft]";
CM_ SG_ 286 ESP_ZT_Rueckk_Convert "[DE: ESP_ZT_Rueckk_Umsetz]";
CM_ SG_ 286 ESP_DoorContact_DriverDoor "[DE: ESP_Tuerkontakt_Fahrertuer]";
CM_ SG_ 286 ESP_Abrutschen_Standstill "[DE: ESP_Abrutschen_Stillstand]";
CM_ SG_ 286 ESP_Driver_Occurs_ZBR_Threshold "[DE: ESP_Fahrer_tritt_ZBR_Schw]";
CM_ SG_ 286 ESP_v_ref_Direction "[DE: ESP_v_ref_Fahrtrichtung]";
CM_ SG_ 286 ESC_BrakePressureGradient "[DE: ESC_Bremsdruckgradient]";
CM_ SG_ 1623 ESP_BrakesTemp_Rear "[DE: ESP_BremsenTemp_hinten]";
CM_ SG_ 924 BCM1_02_Old "[DE: BCM1_02_alt]";
CM_ SG_ 924 Wiper_01_Old "[DE: Wischer_01_alt]";
CM_ SG_ 924 Climate_02_Old "[DE: Klima_02_alt]";
CM_ SG_ 924 BCM1_01_Old "[DE: BCM1_01_alt]";
CM_ SG_ 924 ESP_07_Old "[DE: ESP_07_alt]";
CM_ SG_ 924 DoorECU_BT_1_Old "[DE: TSG_BT_1_alt]";
CM_ SG_ 924 DoorECU_HL_1_Old "[DE: TSG_HL_1_alt]";
CM_ SG_ 924 DoorECU_HR_1_Old "[DE: TSG_HR_1_alt]";
CM_ SG_ 924 Engine_02_Old "[DE: Motor_02_alt]";
CM_ SG_ 924 Climate_Sensor_02_Old "[DE: Klima_Sensor_02_alt]";
CM_ SG_ 924 DoorECU_FT_1_Old "[DE: TSG_FT_1_alt]";
CM_ SG_ 924 Engine_05_Old "[DE: Motor_05_alt]";
CM_ SG_ 924 QSP_01_Old "[DE: QSP_01_alt]";
CM_ SG_ 924 ParkAssist_01_Old "[DE: Parkhilfe_01_alt]";
CM_ SG_ 924 Chassis_02_Old "[DE: Fahrwerk_02_alt]";
CM_ SG_ 924 BCM1_MH_WIV_Switch "[DE: BCM1_MH_WIV_Schalter]";
CM_ SG_ 924 Wiper_Front_Active "[DE: Wischer_vorne_aktiv]";
CM_ SG_ 924 BCM1_ReversingLight_Switch "[DE: BCM1_Rueckfahrlicht_Schalter]";
CM_ SG_ 924 MO_Status_NormalOperation_01 "[DE: MO_Status_Normalbetrieb_01]";
CM_ SG_ 924 TERM_AuxHeater_Enable "[DE: KL_Zuheizer_Freigabe]";
CM_ SG_ 924 BCM1_ForwardGear_Engaged "[DE: BCM1_Vorwaertsgang_eingelegt]";
CM_ SG_ 924 ESP_Coding_ADS "[DE: ESP_Codierung_ADS]";
CM_ SG_ 924 QSP_StartStop_Info "[DE: QSP_StartStopp_Info]";
CM_ SG_ 924 FA_StartStop_Info "[DE: FA_StartStopp_Info]";
CM_ SG_ 924 PH_StartStop_Info "[DE: PH_StartStopp_Info]";
CM_ SG_ 924 TERM_FoggingRisk "[DE: KL_Beschlagsgefahr]";
CM_ SG_ 924 BCM1_GLW_HighBeam_Req "[DE: BCM1_GLW_Fernlicht_Anf]";
CM_ SG_ 924 BCM1_RHeadlights_Veh_Req "[DE: BCM1_RFahrlicht_Fzg_Anf]";
CM_ SG_ 924 FT_Door_Opened "[DE: FT_Tuer_geoeffnet]";
CM_ SG_ 924 FT_ParkPawl "[DE: FT_Sperrklinke]";
CM_ SG_ 924 BCM1_Outside_Temp_Unfilt "[DE: BCM1_Aussen_Temp_ungef]";
CM_ SG_ 924 BCM1_OilPressure_Switch "[DE: BCM1_Oeldruck_Schalter]";
CM_ SG_ 924 BCM1_OilPressure_Switch_2 "[DE: BCM1_Oeldruck_Schalter_2]";
CM_ SG_ 924 BT_Door_Opened "[DE: BT_Tuer_geoeffnet]";
CM_ SG_ 924 HL_Door_Opened "[DE: HL_Tuer_geoeffnet]";
CM_ SG_ 924 HR_Door_Opened "[DE: HR_Tuer_geoeffnet]";
CM_ SG_ 924 BCM1_Adaptive_LightDistribution_Req "[DE: BCM1_Adaptive_Lichtvert_Anf]";
CM_ SG_ 924 BCM1_Sliding_Leuchtw_Req "[DE: BCM1_Gleitende_Leuchtw_Anf]";
CM_ SG_ 924 BCM1_Switch_StartStop "[DE: BCM1_Schalter_StartStopp]";
CM_ SG_ 924 ESP_Offroad_Mode "[DE: ESP_Offroad_Modus]";
CM_ SG_ 924 MO_Enable_Recup "[DE: MO_Freig_Reku]";
CM_ SG_ 927 FROM_BeltBuckle_FA "[DE: AB_Gurtschloss_FA]";
CM_ SG_ 1604 SMLS_01_Old "[DE: SMLS_01_alt]";
CM_ SG_ 1604 HUD_01_Old "[DE: HUD_01_alt]";
CM_ SG_ 1604 BCM1_01_Old "[DE: BCM1_01_alt]";
CM_ SG_ 1604 BCM1_02_Old "[DE: BCM1_02_alt]";
CM_ SG_ 1604 BCM2_02_Old "[DE: BCM2_02_alt]";
CM_ SG_ 1604 HYB_Req_E_Mode_Old "[DE: HYB_Anf_E_Mode_alt]";
CM_ SG_ 1604 BCM1_04_Old "[DE: BCM1_04_alt]";
CM_ SG_ 1604 ESP_04_Old "[DE: ESP_04_alt]";
CM_ SG_ 1604 BH_Indicator_Left "[DE: BH_Blinker_li]";
CM_ SG_ 1604 BH_Indicator_Right "[DE: BH_Blinker_re]";
CM_ SG_ 1604 BM_Motorway "[DE: BM_Autobahn]";
CM_ SG_ 1604 BH_HighBeam "[DE: BH_Fernlicht]";
CM_ SG_ 1604 BH_HeadlightFlash "[DE: BH_Lichthupe]";
CM_ SG_ 1604 BCM1_MH_Switch "[DE: BCM1_MH_Schalter]";
CM_ SG_ 1604 HYB_Req_E_Mode "[DE: HYB_Anf_E_Mode]";
CM_ SG_ 1604 HUD_NV_in_Display "[DE: HUD_NV_in_Anzeige]";
CM_ SG_ 1604 BCM1_Tourist_Light_Req "[DE: BCM1_Touristen_Licht_Anf]";
CM_ SG_ 1604 LV_LowBeam_Left_def "[DE: LV_Abblendlicht_li_def]";
CM_ SG_ 1604 LV_LowBeam_Right_def "[DE: LV_Abblendlicht_re_def]";
CM_ SG_ 1604 LV_LowBeam_Display "[DE: LV_Abblendlicht_Anzeige]";
CM_ SG_ 1604 LV_AFL_Active_Display "[DE: LV_AFL_aktiv_Anzeige]";
CM_ SG_ 1604 BCM1_Light_Darkness_Active "[DE: BCM1_Licht_Dunkelheit_aktiv]";
CM_ SG_ 1604 LV_RearFogLight_Display "[DE: LV_Nebelschlusslicht_Anzeige]";
CM_ SG_ 1604 BCM1_LeftHandTraffic "[DE: BCM1_Linksverkehr]";
CM_ SG_ 1604 BCM2_P_Locked "[DE: BCM2_P_verriegelt]";
CM_ SG_ 1604 BCM1_LDS_Position "[DE: BCM1_LDS_Stellung]";
CM_ SG_ 1604 BCM1_AllWeatherLight_Req "[DE: BCM1_Allwetterlicht_Anf]";
CM_ SG_ 1604 HUD_DisplayFault_NV "[DE: HUD_Anzeigefehler_NV]";
CM_ SG_ 1604 ESP_Diagnostics "[DE: ESP_Diagnose]";
CM_ SG_ 130 Gearbox_01_CHK "[DE: Getriebe_01_CHK]";
CM_ SG_ 130 Gearbox_01_BZ "[DE: Getriebe_01_BZ]";
CM_ SG_ 130 GE_ShiftOperation "[DE: GE_Schaltvorgang]";
CM_ SG_ 130 GE_Status_Clutch "[DE: GE_Status_Kupplung]";
CM_ SG_ 130 GE_Inhibit_Suppression "[DE: GE_Verbot_Ausblendung]";
CM_ SG_ 130 GE_MTorque_Target "[DE: GE_MMom_Soll]";
CM_ SG_ 130 GE_MTorque_Status "[DE: GE_MMom_Status]";
CM_ SG_ 130 GE_Enable_Mmom_Target "[DE: GE_Freig_Mmom_Soll]";
CM_ SG_ 130 GE_Status_ShiftSequence "[DE: GE_Status_Schaltablauf]";
CM_ SG_ 130 GE_MTorque_Lead "[DE: GE_MMom_Vorhalt]";
CM_ SG_ 130 GE_Enable_MTorque_Lead "[DE: GE_Freig_MMom_Vorhalt]";
CM_ SG_ 130 GE_KD_Error "[DE: GE_KD_Fehler]";
CM_ SG_ 131 Gearbox_02_CHK "[DE: Getriebe_02_CHK]";
CM_ SG_ 131 Gearbox_02_BZ "[DE: Getriebe_02_BZ]";
CM_ SG_ 131 GE_Req_CylDeact "[DE: GE_Anf_Zylabsch]";
CM_ SG_ 131 GE_Synchro_RequestedRpm "[DE: GE_Synchro_Wunschdrehz]";
CM_ SG_ 131 GE_Synchro_Time "[DE: GE_Synchro_Zeit]";
CM_ SG_ 131 GE_Torque_Limit_Gradient "[DE: GE_Mom_Begr_Gradient]";
CM_ SG_ 131 GE_Anheb_TargetRpm_Idle "[DE: GE_Anheb_Solldrehz_Leerlauf]";
CM_ SG_ 131 GE_Tachometer_Damping "[DE: GE_Drehzahlmesser_Daempfung]";
CM_ SG_ 131 GE_OverrunCut_Unt "[DE: GE_Schubabschalt_Unt]";
CM_ SG_ 131 GE_Enable_Synchro "[DE: GE_Freigabe_Synchro]";
CM_ SG_ 131 GE_HYB_RPM_Intervention "[DE: GE_HYB_DZ_Eingriff]";
CM_ SG_ 258 Gearbox_03_CHK "[DE: Getriebe_03_CHK]";
CM_ SG_ 258 Gearbox_03_BZ "[DE: Getriebe_03_BZ]";
CM_ SG_ 258 GE_Enable_Langfr_ProtectionTorque "[DE: GE_Freig_Langfr_Schutzmom]";
CM_ SG_ 258 GE_TargetGear "[DE: GE_Zielgang]";
CM_ SG_ 258 GE_StartStop_Info "[DE: GE_StartStopp_Info]";
CM_ SG_ 258 GE_Langfr_ProtectionTorque "[DE: GE_Langfr_Schutzmom]";
CM_ SG_ 258 GE_Reserved_SelectorLever "[DE: GE_reserv_Waehlhebel]";
CM_ SG_ 258 GE_SelectorLever "[DE: GE_Waehlhebel]";
CM_ SG_ 258 GE_InputSpeed "[DE: GE_Eingangsdrehz]";
CM_ SG_ 258 GE_LimpHome "[DE: GE_Notlauf]";
CM_ SG_ 258 GE_Coding_MSG "[DE: GE_Codierung_MSG]";
CM_ SG_ 1089 GE_HeatRequest "[DE: GE_Heizwunsch]";
CM_ SG_ 1089 GE_LFR_Adaptation "[DE: GE_LFR_Adaption]";
CM_ SG_ 1089 GE_OBD_AbsperrValve "[DE: GE_OBD_AbsperrVent]";
CM_ SG_ 1089 GE_Charisma_DrivePr "[DE: GE_Charisma_FahrPr]";
CM_ SG_ 1089 GE_Charisma_Changeover "[DE: GE_Charisma_Umschaltung]";
CM_ SG_ 1089 GE_Enable_ExpiryInfo_WFS "[DE: GE_Freigabe_Verfallsinfo_WFS]";
CM_ SG_ 1089 GE_LossTorque "[DE: GE_Verlustmoment]";
CM_ SG_ 1089 GE_amax_Possible "[DE: GE_amax_moeglich]";
CM_ SG_ 1089 GE_SumpTemperature "[DE: GE_Sumpftemperatur]";
CM_ SG_ 294 EA_ACC_TargetStatus "[DE: EA_ACC_Sollstatus]";
CM_ SG_ 294 EA_JerkProfile "[DE: EA_Ruckprofil]";
CM_ SG_ 294 HCA_01_SendStatus "[DE: HCA_01_Sendestatus]";
CM_ SG_ 294 EA_JerkEnable "[DE: EA_Ruckfreigabe]";
CM_ SG_ 294 EA_ACC_SetSpeed "[DE: EA_ACC_Wunschgeschwindigkeit]";
CM_ SG_ 2015 ISO_OBD_Functional_Req_Data "[DE: ISO_OBD_Funktionaler_Req_Data]";
CM_ SG_ 2017 ISO_Gearbox_01_Req_Data "[DE: ISO_Getriebe_01_Req_Data]";
CM_ SG_ 2025 ISO_Gearbox_01_Resp_Data "[DE: ISO_Getriebe_01_Resp_Data]";
CM_ SG_ 2019 ISO_OBD_Reserved5_Req_Data "[DE: ISO_OBD_reserv5_Req_Data]";
CM_ SG_ 2027 ISO_OBD_Reserved5_Resp_Data "[DE: ISO_OBD_reserv5_Resp_Data]";
CM_ SG_ 1820 ISO_SoundActuator_Req_Data "[DE: ISO_Soundaktor_Req_Data]";
CM_ SG_ 1926 ISO_SoundActuator_Resp_Data "[DE: ISO_Soundaktor_Resp_Data]";
CM_ SG_ 1875 ISO_SelectorLever_Req_Data "[DE: ISO_Waehlhebel_Req_Data]";
CM_ SG_ 1981 ISO_SelectorLever_Resp_Data "[DE: ISO_Waehlhebel_Resp_Data]";
CM_ SG_ 1424 KY_ID_Geb_Authorised "[DE: KY_ID_Geb_autorisiert]";
CM_ SG_ 1424 KY_ID_Geb_Inserted "[DE: KY_ID_Geb_steckt]";
CM_ SG_ 1424 KY_FFB_Frequency "[DE: KY_FFB_Frequenz]";
CM_ SG_ 1424 KY_HF_Active "[DE: KY_HF_Aktiv]";
CM_ SG_ 1424 KY_LF_Active "[DE: KY_LF_Aktiv]";
CM_ SG_ 1424 KY_ELV_Lock "[DE: KY_ELV_verr]";
CM_ SG_ 1424 KY_ELV_enable_Request "[DE: KY_ELV_enable_Anforderung]";
CM_ SG_ 1424 KY_Keyless_Fitment "[DE: KY_Keyless_Verbau]";
CM_ SG_ 1424 KY_FBS_Driver_Notices "[DE: KY_FBS_Fahrer_Hinweise]";
CM_ SG_ 1424 FBS_Warn_Steering_def "[DE: FBS_Warn_Lenkung_def]";
CM_ SG_ 1424 FBS_Warn_SteerLocking_def "[DE: FBS_Warn_LenkVerriegelung_def]";
CM_ SG_ 1424 FBS_Warn_Key_Batt "[DE: FBS_Warn_Schluessel_Batt]";
CM_ SG_ 1424 KY_KYL_Driver_Notices "[DE: KY_KYL_Fahrer_Hinweise]";
CM_ SG_ 1424 KYL_Warn_No_Key "[DE: KYL_Warn_kein_Schluessel]";
CM_ SG_ 1424 KYL_Warn_Kessy_Defective "[DE: KYL_Warn_Kessy_defekt]";
CM_ SG_ 1424 KY_Key_Target "[DE: KY_Schluessel_Soll]";
CM_ SG_ 1424 KY_Key_Actual "[DE: KY_Schluessel_Ist]";
CM_ SG_ 1424 KY_StartStop_Info "[DE: KY_StartStopp_Info]";
CM_ SG_ 1424 FBS_KD_Error "[DE: FBS_KD_Fehler]";
CM_ SG_ 960 Terminals_Status_01_CHK "[DE: Klemmen_Status_01_CHK]";
CM_ SG_ 960 Terminals_Status_01_BZ "[DE: Klemmen_Status_01_BZ]";
CM_ SG_ 960 ZV_Locked_External_Target_02 "[DE: ZV_verriegelt_extern_soll_02]";
CM_ SG_ 960 ZAS_Term_S "[DE: ZAS_Kl_S]";
CM_ SG_ 960 ZAS_Term_15 "[DE: ZAS_Kl_15]";
CM_ SG_ 960 ZAS_Term_X "[DE: ZAS_Kl_X]";
CM_ SG_ 960 ZAS_Term_50 "[DE: ZAS_Kl_50]";
CM_ SG_ 959 TERM_Rpm_Trailer "[DE: KL_Drehz_Anh]";
CM_ SG_ 959 TERM_PreWarn_Compressor_On "[DE: KL_Vorwarn_Komp_ein]";
CM_ SG_ 959 TERM_Handshake_BEM "[DE: KL_Handshake_BEM]";
CM_ SG_ 959 TERM_Compressor_Torque_Old "[DE: KL_Komp_Moment_alt]";
CM_ SG_ 959 TERM_PreWarn_HHS_On "[DE: KL_Vorwarn_HHS_ein]";
CM_ SG_ 959 TERM_PreWarn_HFS_On "[DE: KL_Vorwarn_HFS_ein]";
CM_ SG_ 959 TERM_PreWarn_AuxHeater_On "[DE: KL_Vorwarn_Zuheizer_ein]";
CM_ SG_ 959 TERM_KD_Error "[DE: KL_KD_Fehler]";
CM_ SG_ 959 TERM_Comp_rev_rq "[DE: KL_Comp_rev_rq]";
CM_ SG_ 959 TERM_Charisma_DrivePr "[DE: KL_Charisma_FahrPr]";
CM_ SG_ 959 TERM_Charisma_Status "[DE: KL_Charisma_Status]";
CM_ SG_ 959 TERM_Charisma_Changeover "[DE: KL_Charisma_Umschaltung]";
CM_ SG_ 959 TERM_Load_Compressor "[DE: KL_Last_Kompr]";
CM_ SG_ 959 TERM_Power_Hzg_Target "[DE: KL_Leistung_Hzg_Soll]";
CM_ SG_ 959 TERM_Req_TERM "[DE: KL_Anf_KL]";
CM_ SG_ 959 TERM_4_Zones "[DE: KL_4_Zonen]";
CM_ SG_ 959 TERM_AC_Switch "[DE: KL_AC_Schalter]";
CM_ SG_ 959 TERM_State "[DE: KL_Zustand]";
CM_ SG_ 959 TERM_ThermalManagement "[DE: KL_Thermomanagement]";
CM_ SG_ 959 TERM_Comp_enable "[DE: KL_Comp_enable]";
CM_ SG_ 959 TERM_StartStop_Info "[DE: KL_StartStopp_Info]";
CM_ SG_ 959 TERM_el_AuxHeater_Stage "[DE: KL_el_Zuheizer_Stufe]";
CM_ SG_ 959 TERM_Diag_Absperrvent "[DE: KL_Diag_Absperrvent]";
CM_ SG_ 779 KBI_ABS_Lamp "[DE: KBI_ABS_Lampe]";
CM_ SG_ 779 KBI_ESP_Lamp "[DE: KBI_ESP_Lampe]";
CM_ SG_ 779 KBI_BKL_Lamp "[DE: KBI_BKL_Lampe]";
CM_ SG_ 779 KBI_Airbag_Lamp "[DE: KBI_Airbag_Lampe]";
CM_ SG_ 779 KBI_SILA_Valid "[DE: KBI_SILA_gueltig]";
CM_ SG_ 779 KBI_Steering_Lamp "[DE: KBI_Lenkung_Lampe]";
CM_ SG_ 779 KBI_Preheat_System_Lamp "[DE: KBI_Vorglueh_System_Lampe]";
CM_ SG_ 779 KBI_NV_in_Display "[DE: KBI_NV_in_Anzeige]";
CM_ SG_ 779 KBI_DisplayStatus_ACC "[DE: KBI_Anzeigestatus_ACC]";
CM_ SG_ 779 KBI_OilPressure_Switch "[DE: KBI_Oeldruck_Schalter]";
CM_ SG_ 779 KBI_LowFuelWarning "[DE: KBI_Tankwarnung]";
CM_ SG_ 779 KBI_MFA_v_Unit_01 "[DE: KBI_MFA_v_Einheit_01]";
CM_ SG_ 779 KBI_In_ActuatorTest "[DE: KBI_im_Stellgliedtest]";
CM_ SG_ 779 KBI_DisplayFault_LDW "[DE: KBI_Anzeigefehler_LDW]";
CM_ SG_ 779 KBI_Variant_USA "[DE: KBI_Variante_USA]";
CM_ SG_ 779 KBI_OilPressureWarning "[DE: KBI_Oeldruckwarnung]";
CM_ SG_ 779 KBI_Handbrake "[DE: KBI_Handbremse]";
CM_ SG_ 779 KBI_PLA_in_Display "[DE: KBI_PLA_in_Anzeige]";
CM_ SG_ 779 KBI_DisplayFault_NV "[DE: KBI_Anzeigefehler_NV]";
CM_ SG_ 779 KBI_Displayed_Speed "[DE: KBI_angez_Geschw]";
CM_ SG_ 779 KBI_Unit_Speedo "[DE: KBI_Einheit_Tacho]";
CM_ SG_ 779 KBI_Consistency_ACC "[DE: KBI_Konsistenz_ACC]";
CM_ SG_ 779 KBI_Error_Display_ACC "[DE: KBI_Fehler_Anzeige_ACC]";
CM_ SG_ 779 KBI_DisplayFault_SWA "[DE: KBI_Anzeigefehler_SWA]";
CM_ SG_ 779 KBI_KD_Error "[DE: KBI_KD_Fehler]";
CM_ SG_ 1719 KBI_Odometer "[DE: KBI_Kilometerstand]";
CM_ SG_ 1719 KBI_ParkedTime "[DE: KBI_Standzeit]";
CM_ SG_ 1719 KBI_Reset_ParkedTime "[DE: KBI_Reset_Standzeit]";
CM_ SG_ 1719 KBI_Contents_Tank "[DE: KBI_Inhalt_Tank]";
CM_ SG_ 1719 KBI_QBit_Outside_Temp_Filt "[DE: KBI_QBit_Aussen_Temp_gef]";
CM_ SG_ 1719 KBI_Outside_Temp_Filt "[DE: KBI_Aussen_Temp_gef]";
CM_ SG_ 1720 KBI_TyreCircumference "[DE: KBI_Reifenumfang]";
CM_ SG_ 1720 WFS_Key_DriveAuthorisation "[DE: WFS_Schluessel_Fahrberecht]";
CM_ SG_ 1720 KBI_BCmE_Active "[DE: KBI_BCmE_aktiv]";
CM_ SG_ 1720 KBI_Sparhinweis_Acknowledged "[DE: KBI_Sparhinweis_quittiert]";
CM_ SG_ 919 LDW_Chime "[DE: LDW_Gong]";
CM_ SG_ 919 LDW_SW_Warning_Left "[DE: LDW_SW_Warnung_links]";
CM_ SG_ 919 LDW_SW_Warning_Right "[DE: LDW_SW_Warnung_rechts]";
CM_ SG_ 919 LDW_Side_DLCTLC "[DE: LDW_Seite_DLCTLC]";
CM_ SG_ 919 LDW_LearnMode "[DE: LDW_Lernmodus]";
CM_ SG_ 919 LDW_StartUpTime_VLR "[DE: LDW_Anlaufzeit_VLR]";
CM_ SG_ 919 LDW_LearnMode_Right "[DE: LDW_Lernmodus_rechts]";
CM_ SG_ 919 LDW_LearnMode_Left "[DE: LDW_Lernmodus_links]";
CM_ SG_ 919 LDW_Warning_Left "[DE: LDW_Warnung_links]";
CM_ SG_ 919 LDW_Warning_Right "[DE: LDW_Warnung_rechts]";
CM_ SG_ 919 LDW_CodingInfo_For_VLR "[DE: LDW_Codierinfo_fuer_VLR]";
CM_ SG_ 919 LDW_WindscreenHeating_Active "[DE: LDW_Frontscheibenheizung_aktiv]";
CM_ SG_ 919 LDW_Status_LED_Yellow "[DE: LDW_Status_LED_gelb]";
CM_ SG_ 919 LDW_Status_LED_Green "[DE: LDW_Status_LED_gruen]";
CM_ SG_ 919 LDW_KD_Error "[DE: LDW_KD_Fehler]";
CM_ SG_ 810 EPS_AcousticSignal "[DE: EPS_Akustiksignal]";
CM_ SG_ 810 EPS_FaultLamp "[DE: EPS_Fehlerlampe]";
CM_ SG_ 810 EPS_KD_Error "[DE: EPS_KD_Fehler]";
CM_ SG_ 810 EPS_Warnings "[DE: EPS_Warnungen]";
CM_ SG_ 810 EPS_PLA_Abort "[DE: EPS_PLA_Abbruch]";
CM_ SG_ 810 EPS_PLA_Error "[DE: EPS_PLA_Fehler]";
CM_ SG_ 810 EPS_Charisma_DrivePr "[DE: EPS_Charisma_FahrPr]";
CM_ SG_ 810 EPS_Charisma_Changeover "[DE: EPS_Charisma_Umschaltung]";
CM_ SG_ 810 EPS_HandlebarPosition "[DE: EPS_Lenkerposition]";
CM_ SG_ 810 EPS_Req_TERM "[DE: EPS_Anf_KL]";
CM_ SG_ 285 EPS_LimpHome "[DE: EPS_Notlauf]";
CM_ SG_ 285 EPS_LoadInfo "[DE: EPS_Lastinfo]";
CM_ SG_ 285 EPS_RpmReserve "[DE: EPS_Drehzahlreserve]";
CM_ SG_ 285 EPS_VZ_RpmReserve "[DE: EPS_VZ_Drehzahlreserve]";
CM_ SG_ 285 EPS_PowerRequest "[DE: EPS_Leistungsanforderung]";
CM_ SG_ 159 EPS_Calculated_LW "[DE: EPS_Berechneter_LW]";
CM_ SG_ 159 EPS_SteeringTorque "[DE: EPS_Lenkmoment]";
CM_ SG_ 159 EPS_SteeringTorque_QBit "[DE: EPS_Lenkmoment_QBit]";
CM_ SG_ 159 EPS_VZ_SteeringTorque "[DE: EPS_VZ_Lenkmoment]";
CM_ SG_ 159 EPS_SteeringType "[DE: EPS_Lenkungstyp]";
CM_ SG_ 1137 Light_Rear_01_BZ "[DE: Licht_hinten_01_BZ]";
CM_ SG_ 1137 BCM2_BrakeLight_By_ECD "[DE: BCM2_Bremsl_durch_ECD]";
CM_ SG_ 1137 LH_OutsideLight_def "[DE: LH_Aussenlicht_def]";
CM_ SG_ 1137 LH_SideLight_H_Active "[DE: LH_Standlicht_H_aktiv]";
CM_ SG_ 1137 LH_ParkingLight_HL_Active "[DE: LH_Parklicht_HL_aktiv]";
CM_ SG_ 1137 LH_ParkingLight_HR_Active "[DE: LH_Parklicht_HR_aktiv]";
CM_ SG_ 1137 LH_BrakeLight_H_Active "[DE: LH_Bremslicht_H_aktiv]";
CM_ SG_ 1137 LH_RearFog_Active "[DE: LH_Nebelschluss_aktiv]";
CM_ SG_ 1137 LH_ReversingLight_Active "[DE: LH_Rueckfahrlicht_aktiv]";
CM_ SG_ 1137 LH_Indicator_HL_Act "[DE: LH_Blinker_HL_akt]";
CM_ SG_ 1137 LH_Indicator_HR_Act "[DE: LH_Blinker_HR_akt]";
CM_ SG_ 1137 LH_Indicator_Left_def "[DE: LH_Blinker_li_def]";
CM_ SG_ 1137 LH_BrakeLight_Left_def "[DE: LH_Bremsl_li_def]";
CM_ SG_ 1137 LH_TailLight_Left_def "[DE: LH_Schlusslicht_li_def]";
CM_ SG_ 1137 LH_Reverse_Left_def "[DE: LH_Rueckf_li_def]";
CM_ SG_ 1137 LH_Fog_Left_def "[DE: LH_Nebel_li_def]";
CM_ SG_ 1137 LH_End_Brake_Fog_Left_def "[DE: LH_Schluss_Brems_Nebel_li_def]";
CM_ SG_ 1137 LH_End_Brake_Fog_Right_def "[DE: LH_Schluss_Brems_Nebel_re_def]";
CM_ SG_ 1137 LH_End_Brake_Left_def "[DE: LH_Schluss_Brems_li_def]";
CM_ SG_ 1137 LH_End_Fog_Left_def "[DE: LH_Schluss_Nebel_li_def]";
CM_ SG_ 1137 LH_SL_BRL_BLK_Left_def "[DE: LH_SL_BRL_BLK_li_def]";
CM_ SG_ 1137 LH_Brake_Blk_Left_def "[DE: LH_Brems_Blk_li_def]";
CM_ SG_ 1137 LH_Indicator_Right_def "[DE: LH_Blinker_re_def]";
CM_ SG_ 1137 LH_BrakeLight_Right_def "[DE: LH_Bremsl_re_def]";
CM_ SG_ 1137 LH_TailLight_Right_def "[DE: LH_Schlusslicht_re_def]";
CM_ SG_ 1137 LH_Reverse_Right_def "[DE: LH_Rueckf_re_def]";
CM_ SG_ 1137 LH_Fog_Right_def "[DE: LH_Nebel_re_def]";
CM_ SG_ 1137 LH_End_Brake_Right_def "[DE: LH_Schluss_Brems_re_def]";
CM_ SG_ 1137 LH_End_Fog_Right_def "[DE: LH_Schluss_Nebel_re_def]";
CM_ SG_ 1137 LH_SL_BRL_BLK_Right_def "[DE: LH_SL_BRL_BLK_re_def]";
CM_ SG_ 1137 LH_Brake_Blk_Right_def "[DE: LH_Brems_Blk_re_def]";
CM_ SG_ 1137 LH_3_BrakeLight_def "[DE: LH_3_Bremsl_def]";
CM_ SG_ 1137 LH_Fog_mi_def "[DE: LH_Nebel_mi_def]";
CM_ SG_ 1137 LH_Reverse_mi_def "[DE: LH_Rueckf_mi_def]";
CM_ SG_ 1137 LH_BrakeLight_Left_Total_def "[DE: LH_Bremsl_li_ges_def]";
CM_ SG_ 1137 LH_BrakeLight_Right_Total_def "[DE: LH_Bremsl_re_ges_def]";
CM_ SG_ 267 LS_MainSwitch "[DE: LS_Hauptschalter]";
CM_ SG_ 267 LS_Cancel "[DE: LS_Abbrechen]";
CM_ SG_ 267 LS_Type_MainSwitch "[DE: LS_Typ_Hauptschalter]";
CM_ SG_ 267 LS_Tip_Set "[DE: LS_Tip_Setzen]";
CM_ SG_ 267 LS_Tip_High "[DE: LS_Tip_Hoch]";
CM_ SG_ 267 LS_Tip_Down "[DE: LS_Tip_Runter]";
CM_ SG_ 267 LS_Tip_Resume "[DE: LS_Tip_Wiederaufnahme]";
CM_ SG_ 267 LS_Adjustment_TimeGap "[DE: LS_Verstellung_Zeitluecke]";
CM_ SG_ 267 LS_Tiptronic_Error "[DE: LS_Tiptronic_Fehler]";
CM_ SG_ 267 LS_Error "[DE: LS_Fehler]";
CM_ SG_ 267 LS_Coding "[DE: LS_Codierung]";
CM_ SG_ 267 LS_Tip_Stage_2 "[DE: LS_Tip_Stufe_2]";
CM_ SG_ 267 MFL_M_Key "[DE: MFL_M_Taste]";
CM_ BO_ 1633 "[DE: Anhaenger_01]";
CM_ BO_ 867 "[DE: Blinkmodi_01]";
CM_ BO_ 490 "[DE: CCP_GE_DTO_01]";
CM_ BO_ 488 "[DE: CCP_MO_DTO_01]";
CM_ BO_ 2616986625 "[DE: CCP_MO_DTO_02]";
CM_ BO_ 489 "[DE: CCP_MOS_DTO_01]";
CM_ BO_ 2616986630 "[DE: CCP_MOS_DTO_02]";
CM_ BO_ 2617042432 "[DE: CCP_Soundaktor_CRO_01]";
CM_ BO_ 2617042433 "[DE: CCP_Soundaktor_DTO_01]";
CM_ BO_ 1714 "[DE: Diagnose_01]";
CM_ BO_ 1520 "[DE: Dimmung_01]";
CM_ BO_ 1603 "[DE: Einheiten_01]";
CM_ BO_ 130 "[DE: Getriebe_01]";
CM_ BO_ 131 "[DE: Getriebe_02]";
CM_ BO_ 258 "[DE: Getriebe_03]";
CM_ BO_ 1089 "[DE: Getriebe_04]";
CM_ BO_ 1795 "[DE: ISO_Funktionaler_Req_Aggregate]";
CM_ BO_ 1792 "[DE: ISO_Funktionaler_Req_All]";
CM_ BO_ 2015 "[DE: ISO_Funktionaler_Req_OBD]";
CM_ BO_ 2017 "[DE: ISO_Getriebe_01_Req]";
CM_ BO_ 2025 "[DE: ISO_Getriebe_01_Resp]";
CM_ BO_ 2019 "[DE: ISO_OBD_reserv5_Req]";
CM_ BO_ 2027 "[DE: ISO_OBD_reserv5_Resp]";
CM_ BO_ 1820 "[DE: ISO_Soundaktor_Req]";
CM_ BO_ 1926 "[DE: ISO_Soundaktor_Resp]";
CM_ BO_ 1875 "[DE: ISO_Waehlhebel_Req]";
CM_ BO_ 1981 "[DE: ISO_Waehlhebel_Resp]";
CM_ BO_ 960 "[DE: Klemmen_Status_01]";
CM_ BO_ 959 "[DE: Klima_01]";
CM_ BO_ 779 "[DE: Kombi_01]";
CM_ BO_ 1719 "[DE: Kombi_02]";
CM_ BO_ 1720 "[DE: Kombi_03]";
CM_ BO_ 1137 "[DE: Licht_hinten_01]";
CM_ "English names by can2gauge tools/dbc/dbc_tool.py from opendbc vw_mlb.dbc (MIT); the original German names are in the comments as [DE: ...]";
